VERSION "HNNBNNNYNNNNNNNNNNNNNNNNNNNNNNNNNNNNNNNNNN/4/%%%/4/'%**4NNN///"

NS_ :

BS_:

BU_: AFS AFS_LMod_L AFS_LMod_R BCM1 BVS FCM GLW_LMod_L GLW_LMod_R LCM_L LCM_R LED_DK3_LM_L LED_DK3_LM_R LED_LM_L LED_LM_R LLP_L LLP_R LWR_MXB_L LWR_MXB_R MXB MXB_LM_L MXB_LM_R ZFAS

BO_ 919 GLW_Feh_LM_R: 5 GLW_LMod_R
 SG_ FGR_Akt_KS_Plus : 0|1@1+ (1,0) [0|1] ""  AFS,BCM1,FCM
 SG_ FGR_RAkt_KS_Plus : 1|1@1+ (1,0) [0|1] ""  AFS,BCM1,FCM
 SG_ FGR_Akt_KS_Gnd : 2|1@1+ (1,0) [0|1] ""  AFS,BCM1,FCM
 SG_ FGR_RAkt_KS_Gnd : 3|1@1+ (1,0) [0|1] ""  AFS,BCM1,FCM
 SG_ FGR_Akt_OL : 4|1@1+ (1,0) [0|1] ""  AFS,BCM1,FCM
 SG_ FGR_RAkt_OL : 5|1@1+ (1,0) [0|1] ""  AFS,BCM1,FCM
 SG_ FGR_Akt_UeSpg : 6|1@1+ (1,0) [0|1] ""  AFS,BCM1,FCM
 SG_ FGR_RAkt_UeSpg : 7|1@1+ (1,0) [0|1] ""  AFS,BCM1,FCM
 SG_ FGR_Akt_USpg : 8|1@1+ (1,0) [0|1] ""  AFS,BCM1,FCM
 SG_ FGR_RAkt_USpg : 9|1@1+ (1,0) [0|1] ""  AFS,BCM1,FCM
 SG_ FGR_Akt_UeTemp : 10|1@1+ (1,0) [0|1] ""  AFS,BCM1,FCM
 SG_ FGR_RAkt_UeTemp : 11|1@1+ (1,0) [0|1] ""  AFS,BCM1,FCM
 SG_ FGR_Akt_TempPre : 12|1@1+ (1,0) [0|1] ""  AFS,BCM1,FCM
 SG_ FGR_RAkt_TempPre : 13|1@1+ (1,0) [0|1] ""  AFS,BCM1,FCM
 SG_ FGR_HS_KS_Plus : 18|1@1+ (1,0) [0|1] ""  AFS,BCM1,FCM
 SG_ FGR_RHS_KS_Plus : 19|1@1+ (1,0) [0|1] ""  AFS,BCM1,FCM
 SG_ FGR_HS_KS_Gnd : 20|1@1+ (1,0) [0|1] ""  AFS,BCM1,FCM
 SG_ FGR_RHS_KS_Gnd : 21|1@1+ (1,0) [0|1] ""  AFS,BCM1,FCM
 SG_ FGR_HS_unplSign : 22|1@1+ (1,0) [0|1] ""  AFS,BCM1,FCM
 SG_ FGR_RHS_unplSign : 23|1@1+ (1,0) [0|1] ""  AFS,BCM1,FCM
 SG_ FGR_LIN_Def : 24|1@1+ (1,0) [0|1] ""  AFS,BCM1,FCM
 SG_ FGR_LIN_Timeout : 25|1@1+ (1,0) [0|1] ""  AFS,BCM1,FCM
 SG_ FGR_RLIN_Def : 26|1@1+ (1,0) [0|1] ""  AFS,BCM1,FCM
 SG_ FGR_RLIN_Timeout : 27|1@1+ (1,0) [0|1] ""  AFS,BCM1,FCM

BO_ 272 GLW_Soll_Fkt: 8 AFS
 SG_ SOG_SollPos_L : 0|12@1+ (0.05,0) [0|200] "Unit_PerCent"  BVS,GLW_LMod_L,LCM_L,LLP_L,ZFAS
 SG_ SOG_MXB_Aufblenden : 12|1@1+ (1,0) [0|1] ""  BVS,ZFAS
 SG_ SOG_MXB_Aufbl_Schaltart : 13|1@1+ (1,0) [0|1] ""  BVS,ZFAS
 SG_ SOG_Mali_Freigabe_re : 14|1@1+ (1,0) [0|1] ""  BVS,ZFAS
 SG_ SOG_Mali_Freigabe_li : 15|1@1+ (1,0) [0|1] ""  BVS,ZFAS
 SG_ SOG_SollPos_R : 16|12@1+ (0.05,0) [0|200] "Unit_PerCent"  BVS,GLW_LMod_R,LCM_R,LLP_R,ZFAS
 SG_ SOG_FehlPos_L : 28|1@1+ (1,0) [0|1] ""  BVS,GLW_LMod_L,LCM_L,LLP_L,ZFAS
 SG_ SOG_FehlPos_R : 29|1@1+ (1,0) [0|1] ""  BVS,GLW_LMod_R,LCM_R,LLP_R,ZFAS
 SG_ SOG_RefLauf_L : 30|1@1+ (1,0) [0|1] ""  BVS,GLW_LMod_L,LCM_L,LLP_L,ZFAS
 SG_ SOG_RefLauf_R : 31|1@1+ (1,0) [0|1] ""  BVS,GLW_LMod_R,LCM_R,LLP_R,ZFAS
 SG_ SOG_StGlTest_L : 32|1@1+ (1,0) [0|1] ""  BVS,GLW_LMod_L,LCM_L,LLP_L,ZFAS
 SG_ SOG_StGlTest_R : 33|1@1+ (1,0) [0|1] ""  BVS,GLW_LMod_R,LCM_R,LLP_R,ZFAS
 SG_ SOG_Verkehrsrichtung : 34|1@1+ (1,0) [0|1] ""  BVS,GLW_LMod_L,GLW_LMod_R,LCM_L,LCM_R,LLP_L,LLP_R,ZFAS
 SG_ SOG_XenonLeistung_L : 35|8@1+ (0.125,25) [25|56.5] "Unit_Watt"  BVS,GLW_LMod_L,ZFAS
 SG_ SOG_XenonLeistung_L_Schaltart : 43|1@1+ (1,0) [0|1] ""  BVS,GLW_LMod_L,ZFAS
 SG_ SOG_XenonLeistung_R : 44|8@1+ (0.125,25) [25|56.5] "Unit_Watt"  BVS,GLW_LMod_R,ZFAS
 SG_ SOG_XenonLeistung_R_Schaltart : 52|1@1+ (1,0) [0|1] ""  BVS,GLW_LMod_R,ZFAS

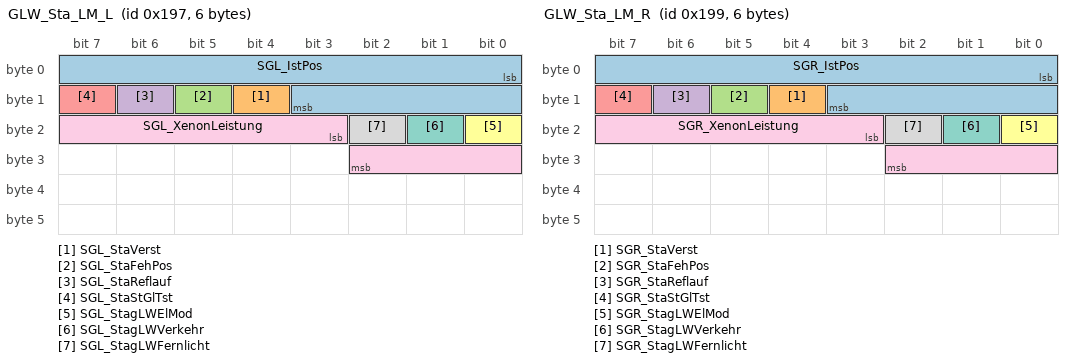
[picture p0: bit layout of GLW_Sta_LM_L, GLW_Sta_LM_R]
BO_ 407 GLW_Sta_LM_L: 6 GLW_LMod_L
 SG_ SGL_IstPos : 0|12@1+ (0.05,0) [0|200] "Unit_PerCent"  AFS,BCM1,FCM
 SG_ SGL_StaVerst : 12|1@1+ (1,0) [0|1] ""  AFS,BCM1,FCM
 SG_ SGL_StaFehPos : 13|1@1+ (1,0) [0|1] ""  AFS,BCM1,FCM
 SG_ SGL_StaReflauf : 14|1@1+ (1,0) [0|1] ""  AFS,BCM1,FCM
 SG_ SGL_StaStGlTst : 15|1@1+ (1,0) [0|1] ""  AFS,BCM1,FCM
 SG_ SGL_StagLWElMod : 16|1@1+ (1,0) [0|1] ""  AFS,BCM1,FCM
 SG_ SGL_StagLWVerkehr : 17|1@1+ (1,0) [0|1] ""  AFS,BCM1,FCM
 SG_ SGL_StagLWFernlicht : 18|1@1+ (1,0) [0|1] ""  AFS,BCM1,FCM
 SG_ SGL_XenonLeistung : 19|8@1+ (0.125,25) [25|56.5] "Unit_Watt"  AFS,BCM1,FCM

BO_ 409 GLW_Sta_LM_R: 6 GLW_LMod_R
 SG_ SGR_IstPos : 0|12@1+ (0.05,0) [0|200] "Unit_PerCent"  AFS,BCM1,FCM
 SG_ SGR_StaVerst : 12|1@1+ (1,0) [0|1] ""  AFS,BCM1,FCM
 SG_ SGR_StaFehPos : 13|1@1+ (1,0) [0|1] ""  AFS,BCM1,FCM
 SG_ SGR_StaReflauf : 14|1@1+ (1,0) [0|1] ""  AFS,BCM1,FCM
 SG_ SGR_StaStGlTst : 15|1@1+ (1,0) [0|1] ""  AFS,BCM1,FCM
 SG_ SGR_StagLWElMod : 16|1@1+ (1,0) [0|1] ""  AFS,BCM1,FCM
 SG_ SGR_StagLWVerkehr : 17|1@1+ (1,0) [0|1] ""  AFS,BCM1,FCM
 SG_ SGR_StagLWFernlicht : 18|1@1+ (1,0) [0|1] ""  AFS,BCM1,FCM
 SG_ SGR_XenonLeistung : 19|8@1+ (0.125,25) [25|56.5] "Unit_Watt"  AFS,BCM1,FCM

BO_ 1792 ISO_Funktionaler_Req_All: 8 AFS
 SG_ ISO_ALL_01_Req_Data : 0|64@1+ (1,0) [0|1.84467440737096E+019] ""  GLW_LMod_L,GLW_LMod_R,LCM_L,LCM_R,LED_DK3_LM_L,LED_DK3_LM_R,LED_LM_L,LED_LM_R,LLP_L,LLP_R

BO_ 2549874818 ISOx_LCM_L_Req: 8 AFS
 SG_ ISO_LCM_L_Req_Data : 0|64@1+ (1,0) [0|1.84467440737096E+019] ""  LCM_L

BO_ 2550005890 ISOx_LCM_L_Resp: 8 LCM_L
 SG_ ISO_LCM_L_Resp_Data : 0|64@1+ (1,0) [0|1.84467440737096E+019] ""  AFS,BCM1,FCM,MXB

BO_ 2549874819 ISOx_LCM_R_Req: 8 AFS
 SG_ ISO_LCM_R_Req_Data : 0|64@1+ (1,0) [0|1.84467440737096E+019] ""  LCM_R

BO_ 2550005891 ISOx_LCM_R_Resp: 8 LCM_R
 SG_ ISO_LCM_R_Resp_Data : 0|64@1+ (1,0) [0|1.84467440737096E+019] ""  AFS,BCM1,FCM,MXB

BO_ 2549874838 ISOx_LED_LM_L_Req: 8 AFS
 SG_ ISO_LED_LM_L_Req_Data : 0|64@1+ (1,0) [0|1.84467440737096E+019] ""  LED_DK3_LM_L,LED_LM_L,LLP_L

BO_ 2550005910 ISOx_LED_LM_L_Resp: 8 LED_DK3_LM_L
 SG_ ISO_LED_LM_L_Resp_Data : 0|64@1+ (1,0) [0|1.84467440737096E+019] ""  AFS,BCM1,FCM,MXB

BO_ 2549874839 ISOx_LED_LM_R_Req: 8 AFS
 SG_ ISO_LED_LM_R_Req_Data : 0|64@1+ (1,0) [0|1.84467440737096E+019] ""  LED_DK3_LM_R,LED_LM_R,LLP_R

BO_ 2550005911 ISOx_LED_LM_R_Resp: 8 LED_DK3_LM_R
 SG_ ISO_LED_LM_R_Resp_Data : 0|64@1+ (1,0) [0|1.84467440737096E+019] ""  AFS,BCM1,FCM,MXB

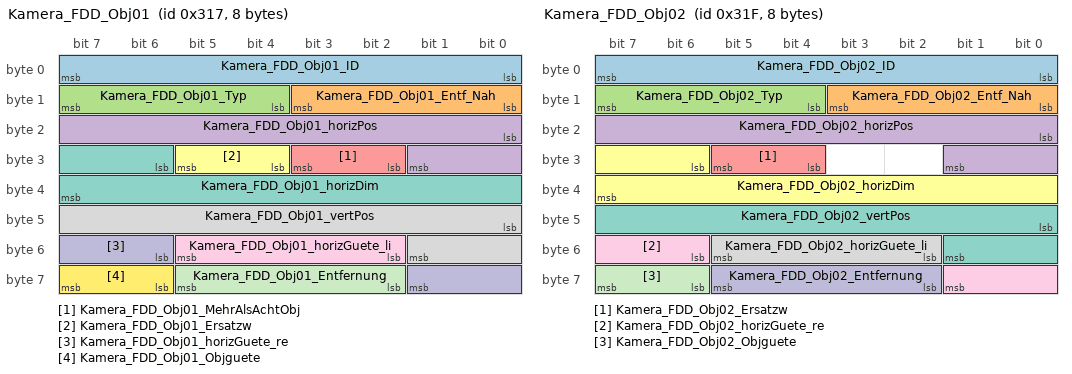
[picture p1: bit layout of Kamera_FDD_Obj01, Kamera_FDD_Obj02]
BO_ 791 Kamera_FDD_Obj01: 8 BVS
 SG_ Kamera_FDD_Obj01_ID : 0|8@1+ (1,0) [0|253] ""  BCM1
 SG_ Kamera_FDD_Obj01_Entf_Nah : 8|4@1+ (1,0) [0|15] ""  BCM1
 SG_ Kamera_FDD_Obj01_Typ : 12|4@1+ (1,0) [0|15] ""  BCM1
 SG_ Kamera_FDD_Obj01_horizPos : 16|10@1+ (0.05,-25.5) [-25.5|25.5] "Unit_DegreOfArc"  BCM1
 SG_ Kamera_FDD_Obj01_MehrAlsAchtObj : 26|2@1+ (1,0) [0|3] ""  BCM1
 SG_ Kamera_FDD_Obj01_Ersatzw : 28|2@1+ (1,0) [0|3] ""  BCM1
 SG_ Kamera_FDD_Obj01_horizDim : 30|10@1+ (0.05,0) [0|49.9] "Unit_DegreOfArc"  BCM1
 SG_ Kamera_FDD_Obj01_vertPos : 40|10@1+ (0.05,-12.75) [-12.75|12.75] "Unit_DegreOfArc"  BCM1
 SG_ Kamera_FDD_Obj01_horizGuete_li : 50|4@1+ (0.25,0) [0|3.75] "Unit_DegreOfArc"  BCM1
 SG_ Kamera_FDD_Obj01_horizGuete_re : 54|4@1+ (0.25,0) [0|3.75] "Unit_DegreOfArc"  BCM1
 SG_ Kamera_FDD_Obj01_Entfernung : 58|4@1+ (1,0) [0|15] ""  BCM1
 SG_ Kamera_FDD_Obj01_Objguete : 62|2@1+ (1,0) [0|3] ""  BCM1

BO_ 799 Kamera_FDD_Obj02: 8 BVS
 SG_ Kamera_FDD_Obj02_ID : 0|8@1+ (1,0) [0|253] ""  BCM1
 SG_ Kamera_FDD_Obj02_Entf_Nah : 8|4@1+ (1,0) [0|15] ""  BCM1
 SG_ Kamera_FDD_Obj02_Typ : 12|4@1+ (1,0) [0|15] ""  BCM1
 SG_ Kamera_FDD_Obj02_horizPos : 16|10@1+ (0.05,-25.5) [-25.5|25.5] "Unit_DegreOfArc"  BCM1
 SG_ Kamera_FDD_Obj02_Ersatzw : 28|2@1+ (1,0) [0|3] ""  BCM1
 SG_ Kamera_FDD_Obj02_horizDim : 30|10@1+ (0.05,0) [0|49.9] "Unit_DegreOfArc"  BCM1
 SG_ Kamera_FDD_Obj02_vertPos : 40|10@1+ (0.05,-12.75) [-12.75|12.75] "Unit_DegreOfArc"  BCM1
 SG_ Kamera_FDD_Obj02_horizGuete_li : 50|4@1+ (0.25,0) [0|3.75] "Unit_DegreOfArc"  BCM1
 SG_ Kamera_FDD_Obj02_horizGuete_re : 54|4@1+ (0.25,0) [0|3.75] "Unit_DegreOfArc"  BCM1
 SG_ Kamera_FDD_Obj02_Entfernung : 58|4@1+ (1,0) [0|15] ""  BCM1
 SG_ Kamera_FDD_Obj02_Objguete : 62|2@1+ (1,0) [0|3] ""  BCM1

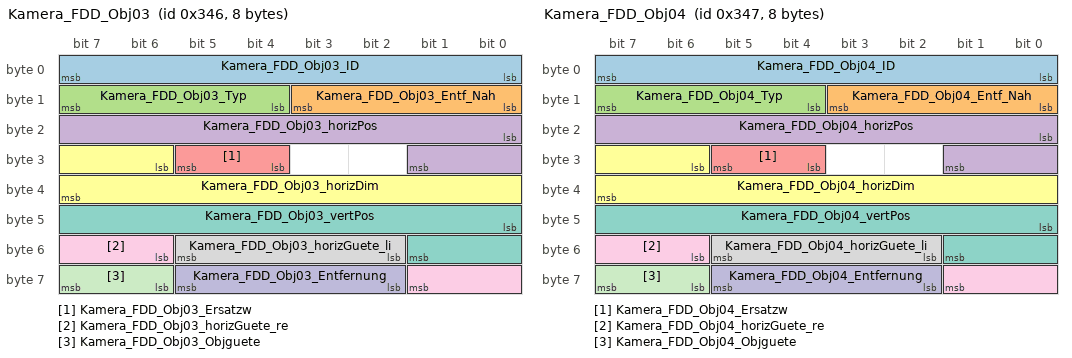
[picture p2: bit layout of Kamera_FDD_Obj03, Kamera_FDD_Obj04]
BO_ 838 Kamera_FDD_Obj03: 8 BVS
 SG_ Kamera_FDD_Obj03_ID : 0|8@1+ (1,0) [0|253] ""  BCM1
 SG_ Kamera_FDD_Obj03_Entf_Nah : 8|4@1+ (1,0) [0|15] ""  BCM1
 SG_ Kamera_FDD_Obj03_Typ : 12|4@1+ (1,0) [0|15] ""  BCM1
 SG_ Kamera_FDD_Obj03_horizPos : 16|10@1+ (0.05,-25.5) [-25.5|25.5] "Unit_DegreOfArc"  BCM1
 SG_ Kamera_FDD_Obj03_Ersatzw : 28|2@1+ (1,0) [0|3] ""  BCM1
 SG_ Kamera_FDD_Obj03_horizDim : 30|10@1+ (0.05,0) [0|49.9] "Unit_DegreOfArc"  BCM1
 SG_ Kamera_FDD_Obj03_vertPos : 40|10@1+ (0.05,-12.75) [-12.75|12.75] "Unit_DegreOfArc"  BCM1
 SG_ Kamera_FDD_Obj03_horizGuete_li : 50|4@1+ (0.25,0) [0|3.75] "Unit_DegreOfArc"  BCM1
 SG_ Kamera_FDD_Obj03_horizGuete_re : 54|4@1+ (0.25,0) [0|3.75] "Unit_DegreOfArc"  BCM1
 SG_ Kamera_FDD_Obj03_Entfernung : 58|4@1+ (1,0) [0|15] ""  BCM1
 SG_ Kamera_FDD_Obj03_Objguete : 62|2@1+ (1,0) [0|3] ""  BCM1

BO_ 839 Kamera_FDD_Obj04: 8 BVS
 SG_ Kamera_FDD_Obj04_ID : 0|8@1+ (1,0) [0|253] ""  BCM1
 SG_ Kamera_FDD_Obj04_Entf_Nah : 8|4@1+ (1,0) [0|15] ""  BCM1
 SG_ Kamera_FDD_Obj04_Typ : 12|4@1+ (1,0) [0|15] ""  BCM1
 SG_ Kamera_FDD_Obj04_horizPos : 16|10@1+ (0.05,-25.5) [-25.5|25.5] "Unit_DegreOfArc"  BCM1
 SG_ Kamera_FDD_Obj04_Ersatzw : 28|2@1+ (1,0) [0|3] ""  BCM1
 SG_ Kamera_FDD_Obj04_horizDim : 30|10@1+ (0.05,0) [0|49.9] "Unit_DegreOfArc"  BCM1
 SG_ Kamera_FDD_Obj04_vertPos : 40|10@1+ (0.05,-12.75) [-12.75|12.75] "Unit_DegreOfArc"  BCM1
 SG_ Kamera_FDD_Obj04_horizGuete_li : 50|4@1+ (0.25,0) [0|3.75] "Unit_DegreOfArc"  BCM1
 SG_ Kamera_FDD_Obj04_horizGuete_re : 54|4@1+ (0.25,0) [0|3.75] "Unit_DegreOfArc"  BCM1
 SG_ Kamera_FDD_Obj04_Entfernung : 58|4@1+ (1,0) [0|15] ""  BCM1
 SG_ Kamera_FDD_Obj04_Objguete : 62|2@1+ (1,0) [0|3] ""  BCM1

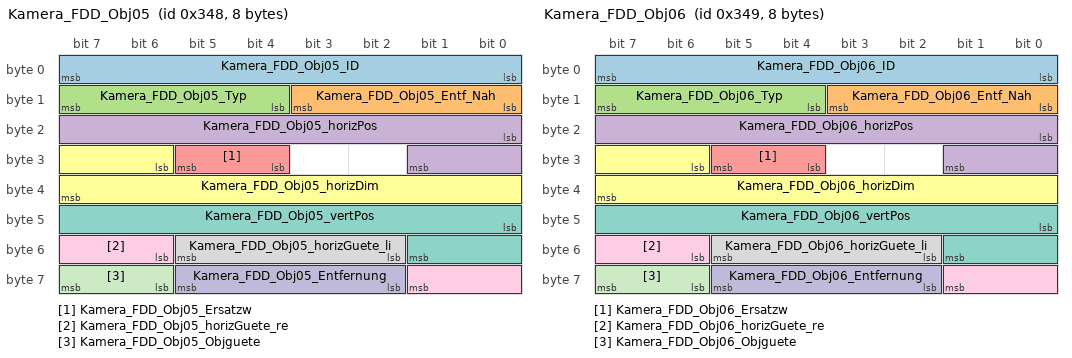
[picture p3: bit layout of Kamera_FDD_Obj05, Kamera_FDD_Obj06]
BO_ 840 Kamera_FDD_Obj05: 8 BVS
 SG_ Kamera_FDD_Obj05_ID : 0|8@1+ (1,0) [0|253] ""  BCM1
 SG_ Kamera_FDD_Obj05_Entf_Nah : 8|4@1+ (1,0) [0|15] ""  BCM1
 SG_ Kamera_FDD_Obj05_Typ : 12|4@1+ (1,0) [0|15] ""  BCM1
 SG_ Kamera_FDD_Obj05_horizPos : 16|10@1+ (0.05,-25.5) [-25.5|25.5] "Unit_DegreOfArc"  BCM1
 SG_ Kamera_FDD_Obj05_Ersatzw : 28|2@1+ (1,0) [0|3] ""  BCM1
 SG_ Kamera_FDD_Obj05_horizDim : 30|10@1+ (0.05,0) [0|49.9] "Unit_DegreOfArc"  BCM1
 SG_ Kamera_FDD_Obj05_vertPos : 40|10@1+ (0.05,-12.75) [-12.75|12.75] "Unit_DegreOfArc"  BCM1
 SG_ Kamera_FDD_Obj05_horizGuete_li : 50|4@1+ (0.25,0) [0|3.75] "Unit_DegreOfArc"  BCM1
 SG_ Kamera_FDD_Obj05_horizGuete_re : 54|4@1+ (0.25,0) [0|3.75] "Unit_DegreOfArc"  BCM1
 SG_ Kamera_FDD_Obj05_Entfernung : 58|4@1+ (1,0) [0|15] ""  BCM1
 SG_ Kamera_FDD_Obj05_Objguete : 62|2@1+ (1,0) [0|3] ""  BCM1

BO_ 841 Kamera_FDD_Obj06: 8 BVS
 SG_ Kamera_FDD_Obj06_ID : 0|8@1+ (1,0) [0|253] ""  BCM1
 SG_ Kamera_FDD_Obj06_Entf_Nah : 8|4@1+ (1,0) [0|15] ""  BCM1
 SG_ Kamera_FDD_Obj06_Typ : 12|4@1+ (1,0) [0|15] ""  BCM1
 SG_ Kamera_FDD_Obj06_horizPos : 16|10@1+ (0.05,-25.5) [-25.5|25.5] "Unit_DegreOfArc"  BCM1
 SG_ Kamera_FDD_Obj06_Ersatzw : 28|2@1+ (1,0) [0|3] ""  BCM1
 SG_ Kamera_FDD_Obj06_horizDim : 30|10@1+ (0.05,0) [0|49.9] "Unit_DegreOfArc"  BCM1
 SG_ Kamera_FDD_Obj06_vertPos : 40|10@1+ (0.05,-12.75) [-12.75|12.75] "Unit_DegreOfArc"  BCM1
 SG_ Kamera_FDD_Obj06_horizGuete_li : 50|4@1+ (0.25,0) [0|3.75] "Unit_DegreOfArc"  BCM1
 SG_ Kamera_FDD_Obj06_horizGuete_re : 54|4@1+ (0.25,0) [0|3.75] "Unit_DegreOfArc"  BCM1
 SG_ Kamera_FDD_Obj06_Entfernung : 58|4@1+ (1,0) [0|15] ""  BCM1
 SG_ Kamera_FDD_Obj06_Objguete : 62|2@1+ (1,0) [0|3] ""  BCM1

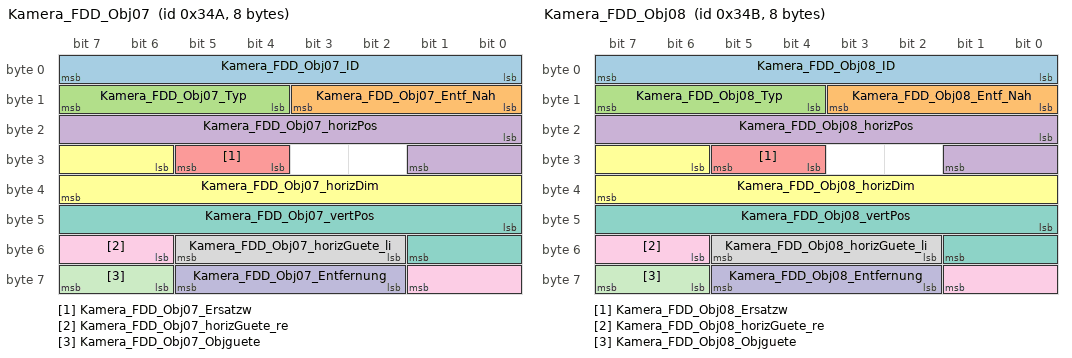
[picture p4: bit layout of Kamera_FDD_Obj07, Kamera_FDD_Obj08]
BO_ 842 Kamera_FDD_Obj07: 8 BVS
 SG_ Kamera_FDD_Obj07_ID : 0|8@1+ (1,0) [0|253] ""  BCM1
 SG_ Kamera_FDD_Obj07_Entf_Nah : 8|4@1+ (1,0) [0|15] ""  BCM1
 SG_ Kamera_FDD_Obj07_Typ : 12|4@1+ (1,0) [0|15] ""  BCM1
 SG_ Kamera_FDD_Obj07_horizPos : 16|10@1+ (0.05,-25.5) [-25.5|25.5] "Unit_DegreOfArc"  BCM1
 SG_ Kamera_FDD_Obj07_Ersatzw : 28|2@1+ (1,0) [0|3] ""  BCM1
 SG_ Kamera_FDD_Obj07_horizDim : 30|10@1+ (0.05,0) [0|49.9] "Unit_DegreOfArc"  BCM1
 SG_ Kamera_FDD_Obj07_vertPos : 40|10@1+ (0.05,-12.75) [-12.75|12.75] "Unit_DegreOfArc"  BCM1
 SG_ Kamera_FDD_Obj07_horizGuete_li : 50|4@1+ (0.25,0) [0|3.75] "Unit_DegreOfArc"  BCM1
 SG_ Kamera_FDD_Obj07_horizGuete_re : 54|4@1+ (0.25,0) [0|3.75] "Unit_DegreOfArc"  BCM1
 SG_ Kamera_FDD_Obj07_Entfernung : 58|4@1+ (1,0) [0|15] ""  BCM1
 SG_ Kamera_FDD_Obj07_Objguete : 62|2@1+ (1,0) [0|3] ""  BCM1

BO_ 843 Kamera_FDD_Obj08: 8 BVS
 SG_ Kamera_FDD_Obj08_ID : 0|8@1+ (1,0) [0|253] ""  BCM1
 SG_ Kamera_FDD_Obj08_Entf_Nah : 8|4@1+ (1,0) [0|15] ""  BCM1
 SG_ Kamera_FDD_Obj08_Typ : 12|4@1+ (1,0) [0|15] ""  BCM1
 SG_ Kamera_FDD_Obj08_horizPos : 16|10@1+ (0.05,-25.5) [-25.5|25.5] "Unit_DegreOfArc"  BCM1
 SG_ Kamera_FDD_Obj08_Ersatzw : 28|2@1+ (1,0) [0|3] ""  BCM1
 SG_ Kamera_FDD_Obj08_horizDim : 30|10@1+ (0.05,0) [0|49.9] "Unit_DegreOfArc"  BCM1
 SG_ Kamera_FDD_Obj08_vertPos : 40|10@1+ (0.05,-12.75) [-12.75|12.75] "Unit_DegreOfArc"  BCM1
 SG_ Kamera_FDD_Obj08_horizGuete_li : 50|4@1+ (0.25,0) [0|3.75] "Unit_DegreOfArc"  BCM1
 SG_ Kamera_FDD_Obj08_horizGuete_re : 54|4@1+ (0.25,0) [0|3.75] "Unit_DegreOfArc"  BCM1
 SG_ Kamera_FDD_Obj08_Entfernung : 58|4@1+ (1,0) [0|15] ""  BCM1
 SG_ Kamera_FDD_Obj08_Objguete : 62|2@1+ (1,0) [0|3] ""  BCM1

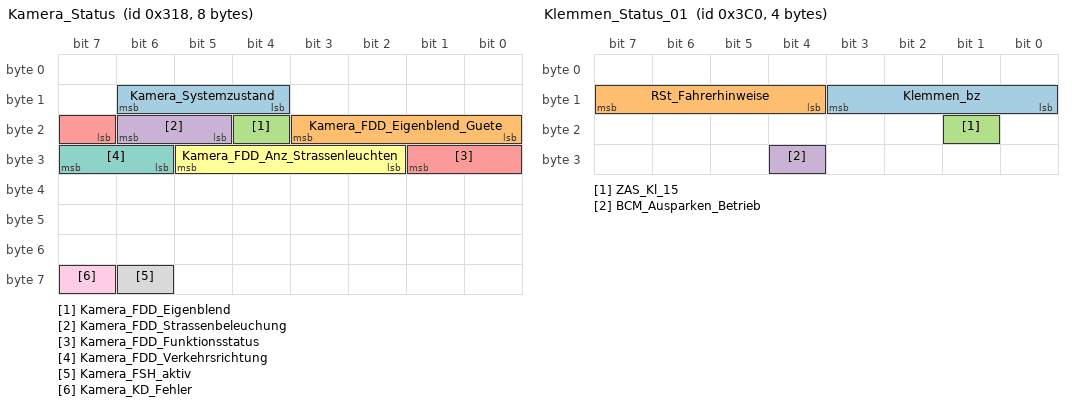
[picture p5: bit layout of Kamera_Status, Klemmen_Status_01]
BO_ 792 Kamera_Status: 8 BVS
 SG_ Kamera_Systemzustand : 12|3@1+ (1,0) [0|7] ""  BCM1
 SG_ Kamera_FDD_Eigenblend_Guete : 16|4@1+ (10,0) [0|100] "Unit_PerCent"  BCM1
 SG_ Kamera_FDD_Eigenblend : 20|1@1+ (1,0) [0|1] ""  BCM1
 SG_ Kamera_FDD_Strassenbeleuchung : 21|2@1+ (1,0) [0|3] ""  BCM1
 SG_ Kamera_FDD_Funktionsstatus : 23|3@1+ (1,0) [0|7] ""  BCM1
 SG_ Kamera_FDD_Anz_Strassenleuchten : 26|4@1+ (1,0) [0|14] ""  BCM1
 SG_ Kamera_FDD_Verkehrsrichtung : 30|2@1+ (1,0) [0|3] ""  BCM1
 SG_ Kamera_FSH_aktiv : 62|1@1+ (1,0) [0|1] ""  BCM1
 SG_ Kamera_KD_Fehler : 63|1@1+ (1,0) [0|1] "" Vector__XXX

BO_ 960 Klemmen_Status_01: 4 MXB
 SG_ Klemmen_bz : 8|4@1- (1,0) [0|0] "" Vector__XXX
 SG_ RSt_Fahrerhinweise : 12|4@1+ (1,0) [0|15] "" Vector__XXX
 SG_ ZAS_Kl_15 : 17|1@1+ (1,0) [0|1] ""  LCM_L,LCM_R,LED_DK3_LM_L,LED_DK3_LM_R,LED_LM_L,LED_LM_R,LLP_L,LLP_R
 SG_ BCM_Ausparken_Betrieb : 28|1@1+ (1,0) [0|1] "" Vector__XXX

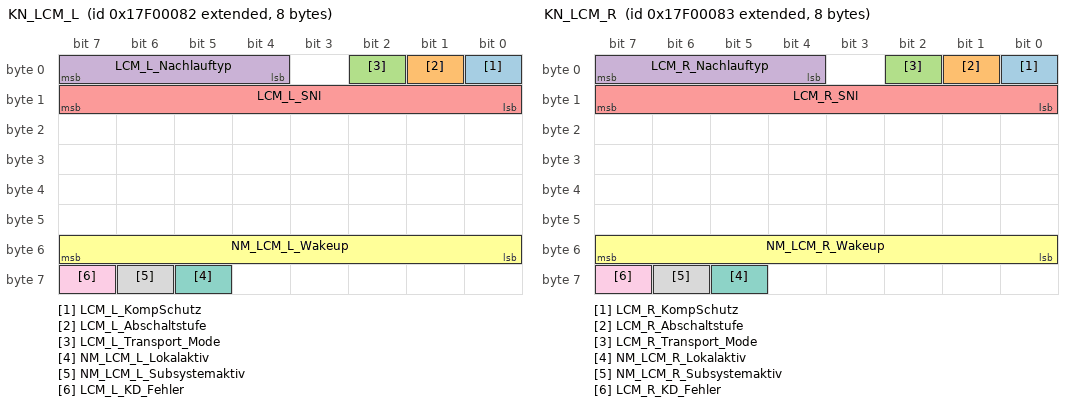
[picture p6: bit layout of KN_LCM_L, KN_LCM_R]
BO_ 2549088386 KN_LCM_L: 8 LCM_L
 SG_ LCM_L_KompSchutz : 0|1@1+ (1,0) [0|1] ""  AFS,BCM1,FCM,MXB
 SG_ LCM_L_Abschaltstufe : 1|1@1+ (1,0) [0|1] ""  AFS,BCM1,FCM,MXB
 SG_ LCM_L_Transport_Mode : 2|1@1+ (1,0) [0|1] ""  AFS,BCM1,FCM,MXB
 SG_ LCM_L_Nachlauftyp : 4|4@1+ (1,0) [0|15] ""  AFS,BCM1,FCM,MXB
 SG_ LCM_L_SNI : 8|8@1+ (1,0) [0|255] ""  AFS,BCM1,FCM,MXB
 SG_ NM_LCM_L_Wakeup : 48|8@1+ (1,0) [0|255] ""  AFS,BCM1,FCM,MXB
 SG_ NM_LCM_L_Lokalaktiv : 61|1@1+ (1,0) [0|1] ""  AFS,BCM1,FCM,MXB
 SG_ NM_LCM_L_Subsystemaktiv : 62|1@1+ (1,0) [0|1] ""  AFS,BCM1,FCM,MXB
 SG_ LCM_L_KD_Fehler : 63|1@1+ (1,0) [0|1] ""  AFS,BCM1,FCM,MXB

BO_ 2549088387 KN_LCM_R: 8 LCM_R
 SG_ LCM_R_KompSchutz : 0|1@1+ (1,0) [0|1] ""  AFS,BCM1,FCM,MXB
 SG_ LCM_R_Abschaltstufe : 1|1@1+ (1,0) [0|1] ""  AFS,BCM1,FCM,MXB
 SG_ LCM_R_Transport_Mode : 2|1@1+ (1,0) [0|1] ""  AFS,BCM1,FCM,MXB
 SG_ LCM_R_Nachlauftyp : 4|4@1+ (1,0) [0|15] ""  AFS,BCM1,FCM,MXB
 SG_ LCM_R_SNI : 8|8@1+ (1,0) [0|255] ""  AFS,BCM1,FCM,MXB
 SG_ NM_LCM_R_Wakeup : 48|8@1+ (1,0) [0|255] ""  AFS,BCM1,FCM,MXB
 SG_ NM_LCM_R_Lokalaktiv : 61|1@1+ (1,0) [0|1] ""  AFS,BCM1,FCM,MXB
 SG_ NM_LCM_R_Subsystemaktiv : 62|1@1+ (1,0) [0|1] ""  AFS,BCM1,FCM,MXB
 SG_ LCM_R_KD_Fehler : 63|1@1+ (1,0) [0|1] ""  AFS,BCM1,FCM,MXB

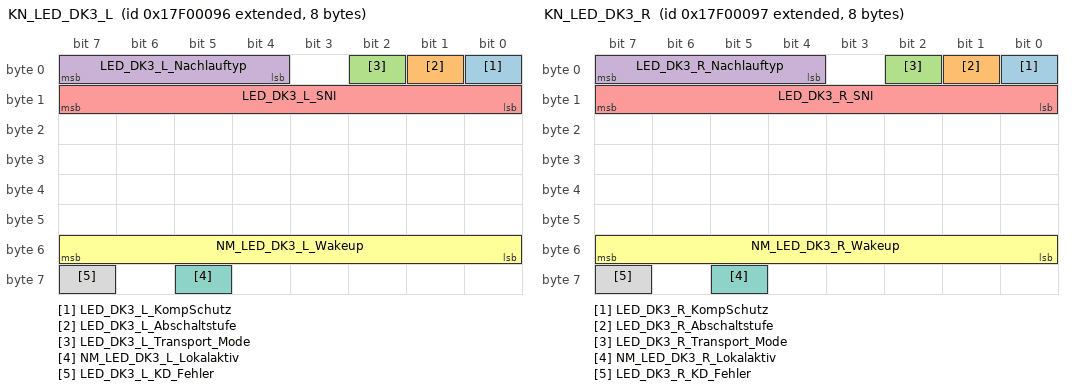
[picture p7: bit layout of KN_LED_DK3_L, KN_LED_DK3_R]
BO_ 2549088406 KN_LED_DK3_L: 8 LED_DK3_LM_L
 SG_ LED_DK3_L_KompSchutz : 0|1@1+ (1,0) [0|1] ""  AFS,BCM1,FCM,MXB
 SG_ LED_DK3_L_Abschaltstufe : 1|1@1+ (1,0) [0|1] ""  AFS,BCM1,FCM,MXB
 SG_ LED_DK3_L_Transport_Mode : 2|1@1+ (1,0) [0|1] ""  AFS,BCM1,FCM,MXB
 SG_ LED_DK3_L_Nachlauftyp : 4|4@1+ (1,0) [0|15] ""  AFS,BCM1,FCM,MXB
 SG_ LED_DK3_L_SNI : 8|8@1+ (1,0) [0|255] ""  AFS,BCM1,FCM,MXB
 SG_ NM_LED_DK3_L_Wakeup : 48|8@1+ (1,0) [0|255] ""  AFS,BCM1,FCM,MXB
 SG_ NM_LED_DK3_L_Lokalaktiv : 61|1@1+ (1,0) [0|1] ""  AFS,BCM1,FCM,MXB
 SG_ LED_DK3_L_KD_Fehler : 63|1@1+ (1,0) [0|1] ""  AFS,BCM1,FCM,MXB

BO_ 2549088407 KN_LED_DK3_R: 8 LED_DK3_LM_R
 SG_ LED_DK3_R_KompSchutz : 0|1@1+ (1,0) [0|1] ""  AFS,BCM1,FCM,MXB
 SG_ LED_DK3_R_Abschaltstufe : 1|1@1+ (1,0) [0|1] ""  AFS,BCM1,FCM,MXB
 SG_ LED_DK3_R_Transport_Mode : 2|1@1+ (1,0) [0|1] ""  AFS,BCM1,FCM,MXB
 SG_ LED_DK3_R_Nachlauftyp : 4|4@1+ (1,0) [0|15] ""  AFS,BCM1,FCM,MXB
 SG_ LED_DK3_R_SNI : 8|8@1+ (1,0) [0|255] ""  AFS,BCM1,FCM,MXB
 SG_ NM_LED_DK3_R_Wakeup : 48|8@1+ (1,0) [0|255] ""  AFS,BCM1,FCM,MXB
 SG_ NM_LED_DK3_R_Lokalaktiv : 61|1@1+ (1,0) [0|1] ""  AFS,BCM1,FCM,MXB
 SG_ LED_DK3_R_KD_Fehler : 63|1@1+ (1,0) [0|1] ""  AFS,BCM1,FCM,MXB

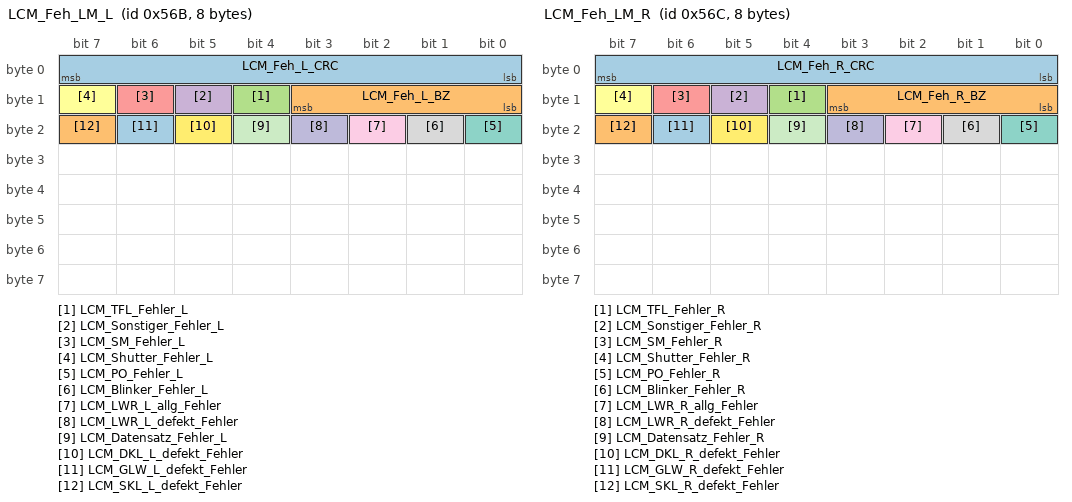
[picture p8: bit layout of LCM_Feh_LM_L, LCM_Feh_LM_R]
BO_ 1387 LCM_Feh_LM_L: 8 LCM_L
 SG_ LCM_Feh_L_CRC : 0|8@1+ (1,0) [0|255] ""  BCM1,MXB
 SG_ LCM_Feh_L_BZ : 8|4@1+ (1,0) [0|15] ""  BCM1,MXB
 SG_ LCM_TFL_Fehler_L : 12|1@1+ (1,0) [0|1] ""  AFS,BCM1,FCM,MXB
 SG_ LCM_Sonstiger_Fehler_L : 13|1@1+ (1,0) [0|1] ""  AFS,BCM1,FCM,MXB
 SG_ LCM_SM_Fehler_L : 14|1@1+ (1,0) [0|1] ""  AFS,BCM1,FCM,MXB
 SG_ LCM_Shutter_Fehler_L : 15|1@1+ (1,0) [0|1] ""  AFS,BCM1,FCM,MXB
 SG_ LCM_PO_Fehler_L : 16|1@1+ (1,0) [0|1] ""  AFS,BCM1,FCM,MXB
 SG_ LCM_Blinker_Fehler_L : 17|1@1+ (1,0) [0|1] ""  AFS,BCM1,FCM,MXB
 SG_ LCM_LWR_L_allg_Fehler : 18|1@1+ (1,0) [0|1] ""  AFS,BCM1,FCM,MXB
 SG_ LCM_LWR_L_defekt_Fehler : 19|1@1+ (1,0) [0|1] ""  AFS,BCM1,FCM,MXB
 SG_ LCM_Datensatz_Fehler_L : 20|1@1+ (1,0) [0|1] ""  AFS,BCM1,FCM,MXB
 SG_ LCM_DKL_L_defekt_Fehler : 21|1@1+ (1,0) [0|1] ""  AFS,BCM1,FCM,MXB
 SG_ LCM_GLW_L_defekt_Fehler : 22|1@1+ (1,0) [0|1] ""  AFS,BCM1,FCM,MXB
 SG_ LCM_SKL_L_defekt_Fehler : 23|1@1+ (1,0) [0|1] ""  AFS,BCM1,FCM,MXB

BO_ 1388 LCM_Feh_LM_R: 8 LCM_R
 SG_ LCM_Feh_R_CRC : 0|8@1+ (1,0) [0|255] ""  BCM1,MXB
 SG_ LCM_Feh_R_BZ : 8|4@1+ (1,0) [0|15] ""  BCM1,MXB
 SG_ LCM_TFL_Fehler_R : 12|1@1+ (1,0) [0|1] ""  AFS,BCM1,FCM,MXB
 SG_ LCM_Sonstiger_Fehler_R : 13|1@1+ (1,0) [0|1] ""  AFS,BCM1,FCM,MXB
 SG_ LCM_SM_Fehler_R : 14|1@1+ (1,0) [0|1] ""  AFS,BCM1,FCM,MXB
 SG_ LCM_Shutter_Fehler_R : 15|1@1+ (1,0) [0|1] ""  AFS,BCM1,FCM,MXB
 SG_ LCM_PO_Fehler_R : 16|1@1+ (1,0) [0|1] ""  AFS,BCM1,FCM,MXB
 SG_ LCM_Blinker_Fehler_R : 17|1@1+ (1,0) [0|1] ""  AFS,BCM1,FCM,MXB
 SG_ LCM_LWR_R_allg_Fehler : 18|1@1+ (1,0) [0|1] ""  AFS,BCM1,FCM,MXB
 SG_ LCM_LWR_R_defekt_Fehler : 19|1@1+ (1,0) [0|1] ""  AFS,BCM1,FCM,MXB
 SG_ LCM_Datensatz_Fehler_R : 20|1@1+ (1,0) [0|1] ""  AFS,BCM1,FCM,MXB
 SG_ LCM_DKL_R_defekt_Fehler : 21|1@1+ (1,0) [0|1] ""  AFS,BCM1,FCM,MXB
 SG_ LCM_GLW_R_defekt_Fehler : 22|1@1+ (1,0) [0|1] ""  AFS,BCM1,FCM,MXB
 SG_ LCM_SKL_R_defekt_Fehler : 23|1@1+ (1,0) [0|1] ""  AFS,BCM1,FCM,MXB

BO_ 403 LCM_Soll_Fkt: 8 AFS
 SG_ LCM_Soll_CRC : 0|8@1+ (1,0) [0|255] ""  LCM_L,LCM_R,LLP_L,LLP_R
 SG_ LCM_Soll_BZ : 8|4@1+ (1,0) [0|15] ""  LCM_L,LCM_R,LLP_L,LLP_R
 SG_ LCM_TFL_L_Anf : 12|1@1+ (1,0) [0|1] ""  LCM_L,LLP_L
 SG_ LCM_TFL_R_Anf : 13|1@1+ (1,0) [0|1] ""  LCM_R,LLP_R
 SG_ LCM_Abschaltung_Vbat_L_Anf : 14|1@1+ (1,0) [0|1] ""  LCM_L,LLP_L
 SG_ LCM_Abschaltung_Vbat_R_Anf : 15|1@1+ (1,0) [0|1] ""  LCM_R,LLP_R
 SG_ LCM_Blinker_L_Anf : 16|1@1+ (1,0) [0|1] ""  LCM_L,LLP_L
 SG_ LCM_Blinker_R_Anf : 17|1@1+ (1,0) [0|1] ""  LCM_R,LLP_R
 SG_ LCM_Blinkerzyklus_L : 18|1@1+ (1,0) [0|1] ""  LCM_L,LLP_L
 SG_ LCM_Blinkerzyklus_R : 19|1@1+ (1,0) [0|1] ""  LCM_R,LLP_R
 SG_ LCM_Sh_L_Anf : 20|1@1+ (1,0) [0|1] ""  LCM_L,LLP_L
 SG_ LCM_Sh_R_Anf : 21|1@1+ (1,0) [0|1] ""  LCM_R,LLP_R
 SG_ LCM_SM_L_Anf : 22|1@1+ (1,0) [0|1] ""  LCM_L,LLP_L
 SG_ LCM_SM_R_Anf : 23|1@1+ (1,0) [0|1] ""  LCM_R,LLP_R
 SG_ LCM_univ_1_L_Anf : 24|1@1+ (1,0) [0|1] ""  LCM_L,LLP_L
 SG_ LCM_univ_1_R_Anf : 25|1@1+ (1,0) [0|1] ""  LCM_R,LLP_R
 SG_ LCM_PO_L_Anf : 28|1@1+ (1,0) [0|1] ""  LCM_L,LLP_L
 SG_ LCM_PO_R_Anf : 29|1@1+ (1,0) [0|1] ""  LCM_R,LLP_R
 SG_ LCM_PL_L_Anf : 30|1@1+ (1,0) [0|1] ""  LCM_L,LLP_L
 SG_ LCM_PL_R_Anf : 31|1@1+ (1,0) [0|1] ""  LCM_R,LLP_R
 SG_ LCM_Leistungsreduzierung_Anf : 32|2@1+ (1,0) [0|3] ""  LCM_L,LCM_R,LLP_L,LLP_R
 SG_ LCM_Blinkerwischen_Anf : 35|1@1+ (1,0) [0|1] ""  LCM_L,LCM_R,LLP_L,LLP_R
 SG_ LCM_Animiertes_TFL_Anf : 36|1@1+ (1,0) [0|1] ""  LCM_L,LCM_R,LLP_L,LLP_R
 SG_ LCM_Signaturlicht_Anf : 39|1@1+ (1,0) [0|1] ""  LCM_L,LCM_R,LLP_L,LLP_R
 SG_ LCM_ECE_SAE_Umschaltung_Anf : 41|1@1+ (1,0) [0|1] ""  LCM_L,LCM_R,LLP_L,LLP_R
 SG_ BM_Autobahn : 42|1@1+ (1,0) [0|1] ""  LCM_L,LCM_R,LLP_L,LLP_R
 SG_ BM_ZV_auf : 43|1@1+ (1,0) [0|1] ""  LCM_L,LCM_R,LLP_L,LLP_R
 SG_ BM_ZV_zu : 44|1@1+ (1,0) [0|1] ""  LCM_L,LCM_R,LLP_L,LLP_R
 SG_ BCM1_CH_aktiv : 45|1@1+ (1,0) [0|1] ""  BVS,LCM_L,LCM_R,LED_DK3_LM_L,LED_DK3_LM_R,LED_LM_L,LED_LM_R,LLP_L,LLP_R,ZFAS
 SG_ BCM1_LH_aktiv : 46|1@1+ (1,0) [0|1] ""  BVS,LCM_L,LCM_R,LED_DK3_LM_L,LED_DK3_LM_R,LED_LM_L,LED_LM_R,LLP_L,LLP_R,ZFAS

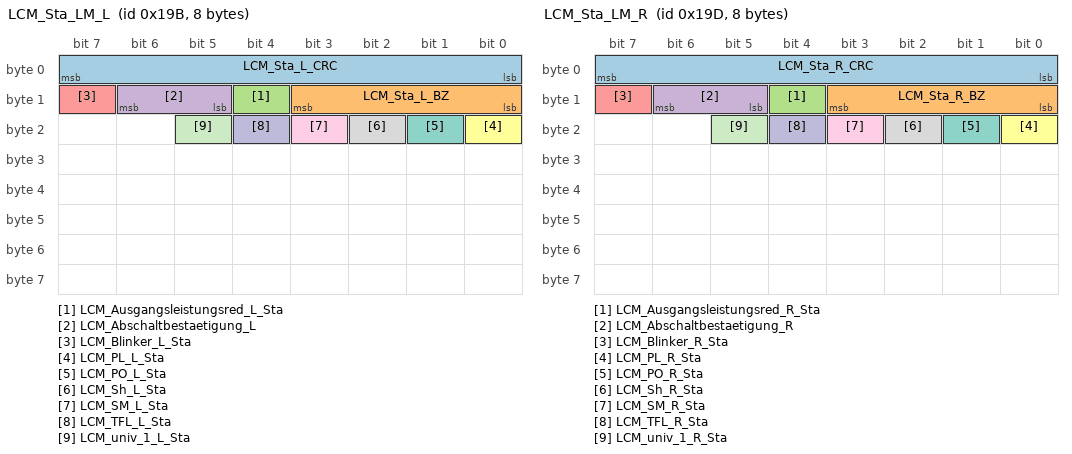
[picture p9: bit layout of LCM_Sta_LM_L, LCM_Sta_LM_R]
BO_ 411 LCM_Sta_LM_L: 8 LCM_L
 SG_ LCM_Sta_L_CRC : 0|8@1+ (1,0) [0|255] ""  BCM1,MXB
 SG_ LCM_Sta_L_BZ : 8|4@1+ (1,0) [0|15] ""  BCM1,MXB
 SG_ LCM_Ausgangsleistungsred_L_Sta : 12|1@1+ (1,0) [0|1] ""  BCM1,MXB
 SG_ LCM_Abschaltbestaetigung_L : 13|2@1+ (1,0) [0|3] ""  AFS,BCM1,FCM,MXB
 SG_ LCM_Blinker_L_Sta : 15|1@1+ (1,0) [0|1] ""  AFS,BCM1,FCM,MXB
 SG_ LCM_PL_L_Sta : 16|1@1+ (1,0) [0|1] ""  BCM1,MXB
 SG_ LCM_PO_L_Sta : 17|1@1+ (1,0) [0|1] ""  BCM1,MXB
 SG_ LCM_Sh_L_Sta : 18|1@1+ (1,0) [0|1] ""  BCM1,MXB
 SG_ LCM_SM_L_Sta : 19|1@1+ (1,0) [0|1] ""  BCM1,MXB
 SG_ LCM_TFL_L_Sta : 20|1@1+ (1,0) [0|1] ""  BCM1,MXB
 SG_ LCM_univ_1_L_Sta : 21|1@1+ (1,0) [0|1] ""  BCM1,MXB

BO_ 413 LCM_Sta_LM_R: 8 LCM_R
 SG_ LCM_Sta_R_CRC : 0|8@1+ (1,0) [0|255] ""  BCM1,MXB
 SG_ LCM_Sta_R_BZ : 8|4@1+ (1,0) [0|15] ""  BCM1,MXB
 SG_ LCM_Ausgangsleistungsred_R_Sta : 12|1@1+ (1,0) [0|1] ""  BCM1,MXB
 SG_ LCM_Abschaltbestaetigung_R : 13|2@1+ (1,0) [0|3] ""  AFS,BCM1,FCM,MXB
 SG_ LCM_Blinker_R_Sta : 15|1@1+ (1,0) [0|1] ""  AFS,BCM1,FCM,MXB
 SG_ LCM_PL_R_Sta : 16|1@1+ (1,0) [0|1] ""  BCM1,MXB
 SG_ LCM_PO_R_Sta : 17|1@1+ (1,0) [0|1] ""  BCM1,MXB
 SG_ LCM_Sh_R_Sta : 18|1@1+ (1,0) [0|1] ""  BCM1,MXB
 SG_ LCM_SM_R_Sta : 19|1@1+ (1,0) [0|1] ""  BCM1,MXB
 SG_ LCM_TFL_R_Sta : 20|1@1+ (1,0) [0|1] ""  BCM1,MXB
 SG_ LCM_univ_1_R_Sta : 21|1@1+ (1,0) [0|1] ""  BCM1,MXB

BO_TX_BU_ 272 : AFS,BCM1,FCM;
BO_TX_BU_ 407 : GLW_LMod_L,LCM_L,LLP_L;
BO_TX_BU_ 409 : GLW_LMod_R,LCM_R,LLP_R;
BO_TX_BU_ 1792 : AFS,BCM1,FCM,MXB;
BO_TX_BU_ 2549874818 : AFS,BCM1,FCM,MXB;
BO_TX_BU_ 2549874819 : AFS,BCM1,FCM,MXB;
BO_TX_BU_ 2549874838 : AFS,BCM1,FCM,MXB;
BO_TX_BU_ 2550005910 : LED_DK3_LM_L,LLP_L;
BO_TX_BU_ 2549874839 : AFS,BCM1,FCM,MXB;
BO_TX_BU_ 2550005911 : LED_DK3_LM_R,LLP_R;
BO_TX_BU_ 791 : BVS,ZFAS;
BO_TX_BU_ 799 : BVS,ZFAS;
BO_TX_BU_ 838 : BVS,ZFAS;
BO_TX_BU_ 839 : BVS,ZFAS;
BO_TX_BU_ 840 : BVS,ZFAS;
BO_TX_BU_ 841 : BVS,ZFAS;
BO_TX_BU_ 842 : BVS,ZFAS;
BO_TX_BU_ 843 : BVS,ZFAS;
BO_TX_BU_ 792 : BVS,ZFAS;
BO_TX_BU_ 960 : AFS,BCM1,FCM,MXB;
BO_TX_BU_ 2549088386 : LCM_L,MXB;
BO_TX_BU_ 2549088406 : LED_DK3_LM_L,LLP_L;
BO_TX_BU_ 2549088407 : LED_DK3_LM_R,LLP_R;
BO_TX_BU_ 1387 : LCM_L,LLP_L;
BO_TX_BU_ 1388 : LCM_R,LLP_R;
BO_TX_BU_ 403 : AFS,BCM1,FCM,MXB;
BO_TX_BU_ 411 : LCM_L,LLP_L;
BO_TX_BU_ 413 : LCM_R,LLP_R;
CM_ SG_ 919 FGR_Akt_KS_Plus "Kurzschluss nach Plus gLW-Aktuator rechter Scheinwerfer";
CM_ SG_ 919 FGR_RAkt_KS_Plus "Das Readyness-Bit dient als Indikator dafür, das der Fehlerbaum sauber durchlaufen wurde. Erst beim Setzen des Readyness-Bits auf '0' wird das dazugehörige Fehlerbit gesetzt";
CM_ SG_ 919 FGR_Akt_KS_Gnd "Kurzschluss nach Masse gLW-Aktuator rechter Scheinwerfer";
CM_ SG_ 919 FGR_RAkt_KS_Gnd "Das Readyness-Bit dient als Indikator dafür, das der Fehlerbaum sauber durchlaufen wurde. Erst beim Setzen des Readyness-Bits auf '0' wird das dazugehörige Fehlerbit gesetzt";
CM_ SG_ 919 FGR_Akt_OL "Offene Leitung (Unterbrechung) gLW-Aktuator rechter Scheinwerfer";
CM_ SG_ 919 FGR_RAkt_OL "Das Readyness-Bit dient als Indikator dafür, das der Fehlerbaum sauber durchlaufen wurde. Erst beim Setzen des Readyness-Bits auf '0' wird das dazugehörige Fehlerbit gesetzt";
CM_ SG_ 919 FGR_Akt_UeSpg "Abschaltung gLW-Aktuator rechter Scheinwerfer aufgrund Überspannung";
CM_ SG_ 919 FGR_RAkt_UeSpg "Das Readyness-Bit dient als Indikator dafür, das der Fehlerbaum sauber durchlaufen wurde. Erst beim Setzen des Readyness-Bits auf '0' wird das dazugehörige Fehlerbit gesetzt";
CM_ SG_ 919 FGR_Akt_USpg "Abschaltung gLW-Aktuator rechter Scheinwerfer aufgrund Unterspannung";
CM_ SG_ 919 FGR_RAkt_USpg "Das Readyness-Bit dient als Indikator dafür, das der Fehlerbaum sauber durchlaufen wurde. Erst beim Setzen des Readyness-Bits auf '0' wird das dazugehörige Fehlerbit gesetzt";
CM_ SG_ 919 FGR_Akt_UeTemp "Abschaltung gLW-Aktuator rechter Scheinwerfer aufgrund Übertemperatur";
CM_ SG_ 919 FGR_RAkt_UeTemp "Das Readyness-Bit dient als Indikator dafür, das der Fehlerbaum sauber durchlaufen wurde. Erst beim Setzen des Readyness-Bits auf '0' wird das dazugehörige Fehlerbit gesetzt";
CM_ SG_ 919 FGR_Akt_TempPre "Ansteuergeschwindigkeit muss reduziert werden wegen erhöhter gLW-Aktuator Temperatur  
(dies ist kein Fehler-BIT!)";
CM_ SG_ 919 FGR_RAkt_TempPre "Das Readyness-Bit dient als Indikator dafür, das der Fehlerbaum sauber durchlaufen wurde. Erst beim Setzen des Readyness-Bits auf '0' wird das dazugehörige Fehlerbit gesetzt";
CM_ SG_ 919 FGR_HS_KS_Plus "Kurzschluss nach Plus gLW Sensor rechter Scheinwerfer

Scheinwerferspezifisch wird nur bei verbauter 360° Rückmeldung gesendet!";
CM_ SG_ 919 FGR_RHS_KS_Plus "Das Readyness-Bit dient als Indikator dafür, das der Fehlerbaum sauber durchlaufen wurde. Erst beim Setzen des Readyness-Bits auf '0' wird das dazugehörige Fehlerbit gesetzt";
CM_ SG_ 919 FGR_HS_KS_Gnd "Kurzschluss nach Masse gLW Sensor rechter Scheinwerfer";
CM_ SG_ 919 FGR_RHS_KS_Gnd "Das Readyness-Bit dient als Indikator dafür, das der Fehlerbaum sauber durchlaufen wurde. Erst beim Setzen des Readyness-Bits auf '0' wird das dazugehörige Fehlerbit gesetzt";
CM_ SG_ 919 FGR_HS_unplSign "Bei einem Fehler kann die 0%-Position des 
GLW-Aktuators nicht bestimmt werden!
Rückmeldung GLW Sensorwerte außerhalb des gültigen Bereichs
(Sensor/ Treiber/ Zuleitung/ Schrittmotoransteuerung prüfen!)";
CM_ SG_ 919 FGR_RHS_unplSign "Das Readyness-Bit dient als Indikator dafür, das der Fehlerbaum sauber durchlaufen wurde. Erst beim Setzen des Readyness-Bits auf '0' wird das dazugehörige Fehlerbit gesetzt";
CM_ SG_ 919 FGR_LIN_Def "Physikalischer Defekt der LIN-Leitung";
CM_ SG_ 919 FGR_LIN_Timeout "Keine Kommunikation zum Teilnehmer";
CM_ SG_ 919 FGR_RLIN_Def "Das Readyness-Bit dient als Indikator dafür, das der Fehlerbaum sauber durchlaufen wurde. Erst beim Setzen des Readyness-Bits auf '0' wird das dazugehörige Fehlerbit gesetzt";
CM_ SG_ 919 FGR_RLIN_Timeout "Das Readyness-Bit dient als Indikator dafür, das der Fehlerbaum sauber durchlaufen wurde. Erst beim Setzen des Readyness-Bits auf '0' wird das dazugehörige Fehlerbit gesetzt";
CM_ SG_ 272 SOG_SollPos_L "Sollposition 'normierter Lichtindex' für den linken Scheinwerfer in %";
CM_ SG_ 272 SOG_MXB_Aufblenden "Synchronisationssignal Aufblenden zwischen MDF und MXB";
CM_ SG_ 272 SOG_MXB_Aufbl_Schaltart "Aufblenden hart oder gedimmt mit Rampe";
CM_ SG_ 272 SOG_Mali_Freigabe_re "Freigabe Markierungslicht rechts duch MDF bei Markierung durch Matrix";
CM_ SG_ 272 SOG_Mali_Freigabe_li "Freigabe Markierungslicht links duch MDF bei Markierung durch Matrix";
CM_ SG_ 272 SOG_SollPos_R "Sollposition 'normierter Lichtindex' für den linken Scheinwerfer in %";
CM_ SG_ 272 SOG_FehlPos_L "gLW Fehlerfallposition des Aktuators im linken Scheinwerfer 

Position komplett Abblenden bedeutet Landstrassenlicht";
CM_ SG_ 272 SOG_FehlPos_R "gLW Fehlerfallposition des Aktuators im rechten Scheinwerfer 

Position komplett Abblenden bedeutet Landstrassenlicht";
CM_ SG_ 272 SOG_RefLauf_L "Referenzlauf des Aktuators im linken Scheinwerfer

Der komplette Bereich von Landstrassenlicht bis hin zu Fernlicht wird abgefahren";
CM_ SG_ 272 SOG_RefLauf_R "Referenzlauf des Aktuators im rechten Scheinwerfer

Der komplette Bereich von Landstrassenlicht bis hin zu Fernlicht wird abgefahren";
CM_ SG_ 272 SOG_StGlTest_L "Stellgliedtest Aktuator linker Scheinwerfer";
CM_ SG_ 272 SOG_StGlTest_R "Stellgliedtest Aktuator rechter Scheinwerfer";
CM_ SG_ 272 SOG_Verkehrsrichtung "Anpassung für Verkehrsrichtung über Codierung
Notwendig für die Referenzierung des 3. Aktuators in Bezug auf die aktuelle Verkehrsart
Die Aktuatorposition Touristenmodus wird über die Sollbotschaften vorgegeben.

Bei Scheinwerferteilenummern die für b";
CM_ SG_ 272 SOG_XenonLeistung_L "Sollwert-Vorgabe Xenius-Brennerleistung
Diagnosefähigkeit / Fehlererkennung erfolgt nur bei eingeschaltetem Brenner";
CM_ SG_ 272 SOG_XenonLeistung_L_Schaltart "Umschaltverhalten bei Leistungsänderung";
CM_ SG_ 272 SOG_XenonLeistung_R "Sollwert-Vorgabe Xenius-Brennerleistung
Diagnosefähigkeit / Fehlererkennung erfolgt nur bei eingeschaltetem Brenner";
CM_ SG_ 272 SOG_XenonLeistung_R_Schaltart "Umschaltverhalten bei Leistungsänderung";
CM_ SG_ 407 SGL_IstPos "Istposition 'normierter Lichtindex' für den linken Scheinwerfer in %";
CM_ SG_ 407 SGL_StaVerst "Verstellung im linken Scheinwerfer
0: keine Verstellung der adaptiven Lichtverteilung
1: Verstellung der adaptiven Lichtverteilung";
CM_ SG_ 407 SGL_StaFehPos "Status Fehlerfallposition linker Scheinwerfer";
CM_ SG_ 407 SGL_StaReflauf "Status Referenzlauf linker Scheinwerfer

Nach erfolgtem Referenzlauf wird  Zustand '1' eingenommen";
CM_ SG_ 407 SGL_StaStGlTst "Stellgliedtest im linken Scheinwerfer";
CM_ SG_ 407 SGL_StagLWElMod "Betrieb mit reduzierter Verstellgeschwindigkeit für gLW 

Wegen Unterspannung oder Übertemperatur 
(dies ist kein Fehler-BIT!)";
CM_ SG_ 407 SGL_StagLWVerkehr "Status Verkehrsrichtung des linken Scheinwerfers

Status in welchem Bereich der gLW-Aktuator eingestellt ist.";
CM_ SG_ 407 SGL_StagLWFernlicht "Status Fernlicht des linken Scheinwerfers";
CM_ SG_ 407 SGL_XenonLeistung "Aktuelle Xenius-Brennerleistung";
CM_ SG_ 409 SGR_IstPos "Istposition 'normierter Lichtindex' für den rechten Scheinwerfer in %";
CM_ SG_ 409 SGR_StaVerst "Verstellung im linken Scheinwerfer
0: keine Verstellung der adaptiven Lichtverteilung
1: Verstellung der adaptiven Lichtverteilung";
CM_ SG_ 409 SGR_StaFehPos "Status Fehlerfallposition rechter Scheinwerfer";
CM_ SG_ 409 SGR_StaReflauf "Status Referenzlauf rechter Scheinwerfer

Nach erfolgtem Referenzlauf wird  Zustand '1' eingenommen";
CM_ SG_ 409 SGR_StaStGlTst "Stellgliedtest im rechten Scheinwerfer";
CM_ SG_ 409 SGR_StagLWElMod "Betrieb mit reduzierter Verstellgeschwindigkeit für gLW 

Wegen Unterspannung oder Übertemperatur 
(dies ist kein Fehler-BIT!)";
CM_ SG_ 409 SGR_StagLWVerkehr "Status Verkehrsrichtung des rechten Scheinwerfers

Status in welchem Bereich der gLW-Aktuator eingestellt ist.";
CM_ SG_ 409 SGR_StagLWFernlicht "Status Fernlicht des rechten Scheinwerfers";
CM_ SG_ 409 SGR_XenonLeistung "Aktuelle Xenius-Brennerleistung";
CM_ SG_ 1792 ISO_ALL_01_Req_Data "Funktionaler Request ALL";
CM_ BO_ 2549874818 "Lichtsteuerung links am Frontlicht-CAN";
CM_ SG_ 2549874818 ISO_LCM_L_Req_Data "Diagnose Request Light Control Module links";
CM_ BO_ 2550005890 "Lichtsteuerung links am Frontlicht-CAN";
CM_ SG_ 2550005890 ISO_LCM_L_Resp_Data "Diagnose Response Light Control Module links";
CM_ BO_ 2549874819 "Lichtsteuerung rechts am Frontlicht-CAN";
CM_ SG_ 2549874819 ISO_LCM_R_Req_Data "Diagnose Request Light Control Module rechts";
CM_ BO_ 2550005891 "Lichtsteuerung rechts am Frontlicht-CAN";
CM_ SG_ 2550005891 ISO_LCM_R_Resp_Data "Diagnose Response Light Control Module rechts";
CM_ BO_ 2549874838 "Lichtsteuerung links am Frontlicht-CAN";
CM_ SG_ 2549874838 ISO_LED_LM_L_Req_Data "Diagnose Request Steuergeraet für LED-Scheinwerfer links";
CM_ BO_ 2550005910 "Lichtsteuerung links am Frontlicht-CAN";
CM_ SG_ 2550005910 ISO_LED_LM_L_Resp_Data "Diagnose Response Steuergeraet für LED-Scheinwerfer links";
CM_ BO_ 2549874839 "Lichtsteuerung rechts am Frontlicht-CAN";
CM_ SG_ 2549874839 ISO_LED_LM_R_Req_Data "Diagnose Request Steuergeraet für LED-Scheinwerfer rechts";
CM_ BO_ 2550005911 "Lichtsteuerung rechts am Frontlicht-CAN";
CM_ SG_ 2550005911 ISO_LED_LM_R_Resp_Data "Diagnose Response Steuergeraet für LED-Scheinwerfer rechts";
CM_ SG_ 791 Kamera_FDD_Obj01_ID "Objekt-ID: Zuordnung einer festen ID zu den Objekten über die Lebenszeit. Damit kann ein Objekttracking im AFS - SG aufgebaut
werden.
";
CM_ SG_ 791 Kamera_FDD_Obj01_Entf_Nah "Genauere Entfernung des erkannten Objekts im Nahbereich (0...100 m).";
CM_ SG_ 791 Kamera_FDD_Obj01_Typ "Objekttyp";
CM_ SG_ 791 Kamera_FDD_Obj01_horizPos "Horizontale Position eines Objekts in Grad. Position bezieht sich auf Objektmitte im Sensorkoordinatensystem. ";
CM_ SG_ 791 Kamera_FDD_Obj01_MehrAlsAchtObj "Detektionsstatus hinsichtlich der Anzahl detektierter Objekte";
CM_ SG_ 791 Kamera_FDD_Obj01_Ersatzw "Objekt entstammt dem Tracking";
CM_ SG_ 791 Kamera_FDD_Obj01_horizDim "Horizontale Ausdehnung eines Objektes";
CM_ SG_ 791 Kamera_FDD_Obj01_vertPos "Verktikale Position eines Objekts. Position bezieht sich auf Unterkante Objekt im Sensorkoordinatensystem. Mathematischer Drehsinn.";
CM_ SG_ 791 Kamera_FDD_Obj01_horizGuete_li "Güte der horizontalen Position (Breite) bzgl. der linken Objektkante. Dieses Signal ersetzt das Signal FDD_Obj01_Guete!";
CM_ SG_ 791 Kamera_FDD_Obj01_horizGuete_re "Güte der horizontalen Position (Breite) bzgl. der rechten Objektkante. Dieses Signal ersetzt das Signal FDD_Obj01_Guete!";
CM_ SG_ 791 Kamera_FDD_Obj01_Entfernung "Eine Entfernungsschzätzung wird anhand des Heckleuchten- und Frontleuchtenabstandes durchgeführt.";
CM_ SG_ 791 Kamera_FDD_Obj01_Objguete "Die Objekt-Güte soll die Qualität der Objektklassifikation darstellen. Bei kleineren Güten ist die Aussage unsicherer.
Ensprechend kann die AFS - Steuerung darauf reagieren und bei unsicheren Objekten die Reaktion verlangsamen.";
CM_ SG_ 799 Kamera_FDD_Obj02_ID "Objekt-ID: Zuordnung einer festen ID zu den Objekten über die Lebenszeit. Damit kann ein Objekttracking im AFS - SG aufgebaut
werden.
";
CM_ SG_ 799 Kamera_FDD_Obj02_Entf_Nah "Genauere Entfernung des erkannten Objekts im Nahbereich (0...100 m).";
CM_ SG_ 799 Kamera_FDD_Obj02_Typ "Objekttyp";
CM_ SG_ 799 Kamera_FDD_Obj02_horizPos "Horizontale Position eines Objekts in Grad. Position bezieht sich auf Objektmitte im Sensorkoordinatensystem. ";
CM_ SG_ 799 Kamera_FDD_Obj02_Ersatzw "Objekt entstammt dem Tracking";
CM_ SG_ 799 Kamera_FDD_Obj02_horizDim "Horizontale Ausdehnung eines Objektes";
CM_ SG_ 799 Kamera_FDD_Obj02_vertPos "Verktikale Position eines Objekts. Position bezieht sich auf Unterkante Objekt im Sensorkoordinatensystem. Mathematischer Drehsinn.";
CM_ SG_ 799 Kamera_FDD_Obj02_horizGuete_li "Güte der horizontalen Position (Breite) bzgl. der linken Objektkante. Dieses Signal ersetzt das Signal FDD_Obj02_Guete!";
CM_ SG_ 799 Kamera_FDD_Obj02_horizGuete_re "Güte der horizontalen Position (Breite) bzgl. der rechten Objektkante. Dieses Signal ersetzt das Signal FDD_Obj02_Guete!";
CM_ SG_ 799 Kamera_FDD_Obj02_Entfernung "Eine Entfernungsschzätzung wird anhand des Heckleuchten- und Frontleuchtenabstandes durchgeführt.";
CM_ SG_ 799 Kamera_FDD_Obj02_Objguete "Die Objekt-Güte soll die Qualität der Objektklassifikation darstellen. Bei kleineren Güten ist die Aussage unsicherer.
Ensprechend kann die AFS - Steuerung darauf reagieren und bei unsicheren Objekten die Reaktion verlangsamen.";
CM_ SG_ 838 Kamera_FDD_Obj03_ID "Objekt-ID: Zuordnung einer festen ID zu den Objekten über die Lebenszeit. Damit kann ein Objekttracking im AFS - SG aufgebaut
werden.
";
CM_ SG_ 838 Kamera_FDD_Obj03_Entf_Nah "Genauere Entfernung des erkannten Objekts im Nahbereich (0...100 m).";
CM_ SG_ 838 Kamera_FDD_Obj03_Typ "Objekttyp";
CM_ SG_ 838 Kamera_FDD_Obj03_horizPos "Horizontale Position eines Objekts in Grad. Position bezieht sich auf Objektmitte im Sensorkoordinatensystem. ";
CM_ SG_ 838 Kamera_FDD_Obj03_Ersatzw "Objekt entstammt dem Tracking";
CM_ SG_ 838 Kamera_FDD_Obj03_horizDim "Horizontale Ausdehnung eines Objektes";
CM_ SG_ 838 Kamera_FDD_Obj03_vertPos "Verktikale Position eines Objekts. Position bezieht sich auf Unterkante Objekt im Sensorkoordinatensystem. Mathematischer Drehsinn.";
CM_ SG_ 838 Kamera_FDD_Obj03_horizGuete_li "Güte der horizontalen Position (Breite) bzgl. der linken Objektkante. Dieses Signal ersetzt das Signal FDD_Obj03_Guete!";
CM_ SG_ 838 Kamera_FDD_Obj03_horizGuete_re "Güte der horizontalen Position (Breite) bzgl. der rechten Objektkante. Dieses Signal ersetzt das Signal FDD_Obj03_Guete!";
CM_ SG_ 838 Kamera_FDD_Obj03_Entfernung "Eine Entfernungsschzätzung wird anhand des Heckleuchten- und Frontleuchtenabstandes durchgeführt.";
CM_ SG_ 838 Kamera_FDD_Obj03_Objguete "Die Objekt-Güte soll die Qualität der Objektklassifikation darstellen. Bei kleineren Güten ist die Aussage unsicherer.
Ensprechend kann die AFS - Steuerung darauf reagieren und bei unsicheren Objekten die Reaktion verlangsamen.";
CM_ SG_ 839 Kamera_FDD_Obj04_ID "Objekt-ID: Zuordnung einer festen ID zu den Objekten über die Lebenszeit. Damit kann ein Objekttracking im AFS - SG aufgebaut
werden.
";
CM_ SG_ 839 Kamera_FDD_Obj04_Entf_Nah "Genauere Entfernung des erkannten Objekts im Nahbereich (0...100 m).";
CM_ SG_ 839 Kamera_FDD_Obj04_Typ "Objekttyp";
CM_ SG_ 839 Kamera_FDD_Obj04_horizPos "Horizontale Position eines Objekts in Grad. Position bezieht sich auf Objektmitte im Sensorkoordinatensystem. ";
CM_ SG_ 839 Kamera_FDD_Obj04_Ersatzw "Objekt entstammt dem Tracking";
CM_ SG_ 839 Kamera_FDD_Obj04_horizDim "Horizontale Ausdehnung eines Objektes";
CM_ SG_ 839 Kamera_FDD_Obj04_vertPos "Verktikale Position eines Objekts. Position bezieht sich auf Unterkante Objekt im Sensorkoordinatensystem. Mathematischer Drehsinn.";
CM_ SG_ 839 Kamera_FDD_Obj04_horizGuete_li "Güte der horizontalen Position (Breite) bzgl. der linken Objektkante. Dieses Signal ersetzt das Signal FDD_Obj04_Guete!";
CM_ SG_ 839 Kamera_FDD_Obj04_horizGuete_re "Güte der horizontalen Position (Breite) bzgl. der rechten Objektkante. Dieses Signal ersetzt das Signal FDD_Obj04_Guete!";
CM_ SG_ 839 Kamera_FDD_Obj04_Entfernung "Eine Entfernungsschzätzung wird anhand des Heckleuchten- und Frontleuchtenabstandes durchgeführt.";
CM_ SG_ 839 Kamera_FDD_Obj04_Objguete "Die Objekt-Güte soll die Qualität der Objektklassifikation darstellen. Bei kleineren Güten ist die Aussage unsicherer.
Ensprechend kann die AFS - Steuerung darauf reagieren und bei unsicheren Objekten die Reaktion verlangsamen.";
CM_ SG_ 840 Kamera_FDD_Obj05_ID "Objekt-ID: Zuordnung einer festen ID zu den Objekten über die Lebenszeit. Damit kann ein Objekttracking im AFS - SG aufgebaut
werden.
";
CM_ SG_ 840 Kamera_FDD_Obj05_Entf_Nah "Genauere Entfernung des erkannten Objekts im Nahbereich (0...100 m).";
CM_ SG_ 840 Kamera_FDD_Obj05_Typ "Objekttyp";
CM_ SG_ 840 Kamera_FDD_Obj05_horizPos "Horizontale Position eines Objekts in Grad. Position bezieht sich auf Objektmitte im Sensorkoordinatensystem. ";
CM_ SG_ 840 Kamera_FDD_Obj05_Ersatzw "Objekt entstammt dem Tracking";
CM_ SG_ 840 Kamera_FDD_Obj05_horizDim "Horizontale Ausdehnung eines Objektes";
CM_ SG_ 840 Kamera_FDD_Obj05_vertPos "Verktikale Position eines Objekts. Position bezieht sich auf Unterkante Objekt im Sensorkoordinatensystem. Mathematischer Drehsinn.";
CM_ SG_ 840 Kamera_FDD_Obj05_horizGuete_li "Güte der horizontalen Position (Breite) bzgl. der linken Objektkante. Dieses Signal ersetzt das Signal FDD_Obj05_Guete!";
CM_ SG_ 840 Kamera_FDD_Obj05_horizGuete_re "Güte der horizontalen Position (Breite) bzgl. der rechten Objektkante. Dieses Signal ersetzt das Signal FDD_Obj05_Guete!";
CM_ SG_ 840 Kamera_FDD_Obj05_Entfernung "Eine Entfernungsschzätzung wird anhand des Heckleuchten- und Frontleuchtenabstandes durchgeführt.";
CM_ SG_ 840 Kamera_FDD_Obj05_Objguete "Die Objekt-Güte soll die Qualität der Objektklassifikation darstellen. Bei kleineren Güten ist die Aussage unsicherer.
Ensprechend kann die AFS - Steuerung darauf reagieren und bei unsicheren Objekten die Reaktion verlangsamen.";
CM_ SG_ 841 Kamera_FDD_Obj06_ID "Objekt-ID: Zuordnung einer festen ID zu den Objekten über die Lebenszeit. Damit kann ein Objekttracking im AFS - SG aufgebaut
werden.
";
CM_ SG_ 841 Kamera_FDD_Obj06_Entf_Nah "Genauere Entfernung des erkannten Objekts im Nahbereich (0...100 m).";
CM_ SG_ 841 Kamera_FDD_Obj06_Typ "Objekttyp";
CM_ SG_ 841 Kamera_FDD_Obj06_horizPos "Horizontale Position eines Objekts in Grad. Position bezieht sich auf Objektmitte im Sensorkoordinatensystem. ";
CM_ SG_ 841 Kamera_FDD_Obj06_Ersatzw "Objekt entstammt dem Tracking";
CM_ SG_ 841 Kamera_FDD_Obj06_horizDim "Horizontale Ausdehnung eines Objektes";
CM_ SG_ 841 Kamera_FDD_Obj06_vertPos "Verktikale Position eines Objekts. Position bezieht sich auf Unterkante Objekt im Sensorkoordinatensystem. Mathematischer Drehsinn.";
CM_ SG_ 841 Kamera_FDD_Obj06_horizGuete_li "Güte der horizontalen Position (Breite) bzgl. der linken Objektkante. Dieses Signal ersetzt das Signal FDD_Obj06_Guete!";
CM_ SG_ 841 Kamera_FDD_Obj06_horizGuete_re "Güte der horizontalen Position (Breite) bzgl. der rechten Objektkante. Dieses Signal ersetzt das Signal FDD_Obj06_Guete!";
CM_ SG_ 841 Kamera_FDD_Obj06_Entfernung "Eine Entfernungsschzätzung wird anhand des Heckleuchten- und Frontleuchtenabstandes durchgeführt.";
CM_ SG_ 841 Kamera_FDD_Obj06_Objguete "Die Objekt-Güte soll die Qualität der Objektklassifikation darstellen. Bei kleineren Güten ist die Aussage unsicherer.
Ensprechend kann die AFS - Steuerung darauf reagieren und bei unsicheren Objekten die Reaktion verlangsamen.";
CM_ SG_ 842 Kamera_FDD_Obj07_ID "Objekt-ID: Zuordnung einer festen ID zu den Objekten über die Lebenszeit. Damit kann ein Objekttracking im AFS - SG aufgebaut
werden.
";
CM_ SG_ 842 Kamera_FDD_Obj07_Entf_Nah "Genauere Entfernung des erkannten Objekts im Nahbereich (0...100 m).";
CM_ SG_ 842 Kamera_FDD_Obj07_Typ "Objekttyp";
CM_ SG_ 842 Kamera_FDD_Obj07_horizPos "Horizontale Position eines Objekts in Grad. Position bezieht sich auf Objektmitte im Sensorkoordinatensystem. ";
CM_ SG_ 842 Kamera_FDD_Obj07_Ersatzw "Objekt entstammt dem Tracking";
CM_ SG_ 842 Kamera_FDD_Obj07_horizDim "Horizontale Ausdehnung eines Objektes";
CM_ SG_ 842 Kamera_FDD_Obj07_vertPos "Verktikale Position eines Objekts. Position bezieht sich auf Unterkante Objekt im Sensorkoordinatensystem. Mathematischer Drehsinn.";
CM_ SG_ 842 Kamera_FDD_Obj07_horizGuete_li "Güte der horizontalen Position (Breite) bzgl. der linken Objektkante. Dieses Signal ersetzt das Signal FDD_Obj07_Guete!";
CM_ SG_ 842 Kamera_FDD_Obj07_horizGuete_re "Güte der horizontalen Position (Breite) bzgl. der rechten Objektkante. Dieses Signal ersetzt das Signal FDD_Obj07_Guete!";
CM_ SG_ 842 Kamera_FDD_Obj07_Entfernung "Eine Entfernungsschzätzung wird anhand des Heckleuchten- und Frontleuchtenabstandes durchgeführt.";
CM_ SG_ 842 Kamera_FDD_Obj07_Objguete "Die Objekt-Güte soll die Qualität der Objektklassifikation darstellen. Bei kleineren Güten ist die Aussage unsicherer.
Ensprechend kann die AFS - Steuerung darauf reagieren und bei unsicheren Objekten die Reaktion verlangsamen.";
CM_ SG_ 843 Kamera_FDD_Obj08_ID "Objekt-ID: Zuordnung einer festen ID zu den Objekten über die Lebenszeit. Damit kann ein Objekttracking im AFS - SG aufgebaut
werden.
";
CM_ SG_ 843 Kamera_FDD_Obj08_Entf_Nah "Genauere Entfernung des erkannten Objekts im Nahbereich (0...100 m).";
CM_ SG_ 843 Kamera_FDD_Obj08_Typ "Objekttyp";
CM_ SG_ 843 Kamera_FDD_Obj08_horizPos "Horizontale Position eines Objekts in Grad. Position bezieht sich auf Objektmitte im Sensorkoordinatensystem. ";
CM_ SG_ 843 Kamera_FDD_Obj08_Ersatzw "Objekt entstammt dem Tracking";
CM_ SG_ 843 Kamera_FDD_Obj08_horizDim "Horizontale Ausdehnung eines Objektes";
CM_ SG_ 843 Kamera_FDD_Obj08_vertPos "Verktikale Position eines Objekts. Position bezieht sich auf Unterkante Objekt im Sensorkoordinatensystem. Mathematischer Drehsinn.";
CM_ SG_ 843 Kamera_FDD_Obj08_horizGuete_li "Güte der horizontalen Position (Breite) bzgl. der linken Objektkante. Dieses Signal ersetzt das Signal FDD_Obj08_Guete!";
CM_ SG_ 843 Kamera_FDD_Obj08_horizGuete_re "Güte der horizontalen Position (Breite) bzgl. der rechten Objektkante. Dieses Signal ersetzt das Signal FDD_Obj08_Guete!";
CM_ SG_ 843 Kamera_FDD_Obj08_Entfernung "Eine Entfernungsschzätzung wird anhand des Heckleuchten- und Frontleuchtenabstandes durchgeführt.";
CM_ SG_ 843 Kamera_FDD_Obj08_Objguete "Die Objekt-Güte soll die Qualität der Objektklassifikation darstellen. Bei kleineren Güten ist die Aussage unsicherer.
Ensprechend kann die AFS - Steuerung darauf reagieren und bei unsicheren Objekten die Reaktion verlangsamen.";
CM_ SG_ 792 Kamera_Systemzustand "Systemzustand der Kamera";
CM_ SG_ 792 Kamera_FDD_Eigenblend_Guete "Diese Signal gibt an, welches Maß einer Eigenblendung vorliegt.";
CM_ SG_ 792 Kamera_FDD_Eigenblend "Dieses Signal gibt an, ob von der Kamera eine Eigenblendung, z.B. Nebel, erkannt wird.";
CM_ SG_ 792 Kamera_FDD_Strassenbeleuchung "Status Straßenbeleuchungsdetektion";
CM_ SG_ 792 Kamera_FDD_Funktionsstatus "Status der Fahrzeugdetektion bei Dunkelheit";
CM_ SG_ 792 Kamera_FDD_Anz_Strassenleuchten "Anzahl der erkannten Straßenleuchten";
CM_ SG_ 792 Kamera_FDD_Verkehrsrichtung "Gibt bei Nacht die auf Grund der entgegenkommenden Fahrzeuge erkannte Verkehrsrichtung an";
CM_ SG_ 792 Kamera_FSH_aktiv "Bei aktivierter (lokaler) Frontscheibenheizung wird die Scheibentemperaturmessung des Klimafeuchtesensors beeinflusst. Über das Signal wird dem Klima-SG mitgeteilt, dass die lokale Scheibenheizung aktiviert ist, um entsprechende Korrekturwerte bei der Sch";
CM_ SG_ 792 Kamera_KD_Fehler "Status Kundendienstfehlerspeichereinträge
";
CM_ BO_ 960 "MQB";
CM_ SG_ 960 RSt_Fahrerhinweise "Über das Signal fordert das BCM Fahrerhinweise im Kombi für die Funktion RemoteStart an.";
CM_ SG_ 960 ZAS_Kl_15 "Klemme 15: Zuendung (SW-Kl.15)
";
CM_ SG_ 960 BCM_Ausparken_Betrieb "Anforderung zur erneuten Lampenaufprüfung und Anzeige von Warnhinweisen nach einem pilotierten Ausparkvorgang (Trigger: fallende Flanke)";
CM_ SG_ 2549088386 LCM_L_KompSchutz "Funktionseinschränkung aufgrund Komponentenschutz aktiv";
CM_ SG_ 2549088386 LCM_L_Abschaltstufe "Funktionseinschränkung aufgrund aktiver Abschaltstufe";
CM_ SG_ 2549088386 LCM_L_Transport_Mode "Funktionseinschränkung aufgrund aktivem Transport Mode und/oder Transport Schutz
";
CM_ SG_ 2549088386 LCM_L_Nachlauftyp "Abgebildet wird die von der Hardware vorgegebene Möglichkeit, die Kommunikation nach Klemme 15 = AUS aufrecht zu erhalten. Es wird ein Init-Wert gesendet.
0 = Kommunikation nur bei KL15=EIN (kein Nachlauf, nicht weckfähig)
1 = Kommunikation nach KL15=AU";
CM_ SG_ 2549088386 LCM_L_SNI "Das Signal beinhaltet den Source Node Identifier (Knotenadresse, die auch in der Abbildungsvorschrift zur CAN-ID für die NM-High Botschaft verwendet wird).";
CM_ SG_ 2549088386 NM_LCM_L_Wakeup "enthält die Weckursache; stehen mehrere Weckursachen parallel an, dann muss der kleinste Wert übertragen werden";
CM_ SG_ 2549088386 NM_LCM_L_Lokalaktiv "Zeigt an ob das SG nach Klemme15 AUS und nach entsprechender MAX Aktivzeit noch aktiv war";
CM_ SG_ 2549088386 NM_LCM_L_Subsystemaktiv "Zeigt an ob ein Subsystem des SGs nach Klemme15 AUS und nach entsprechender MAX Aktivzeit noch aktiv war";
CM_ SG_ 2549088386 LCM_L_KD_Fehler "Status Kundendienst-Fehlerspeicher";
CM_ SG_ 2549088387 LCM_R_KompSchutz "Funktionseinschränkung aufgrund Komponentenschutz aktiv";
CM_ SG_ 2549088387 LCM_R_Abschaltstufe "Funktionseinschränkung aufgrund aktiver Abschaltstufe";
CM_ SG_ 2549088387 LCM_R_Transport_Mode "Funktionseinschränkung aufgrund aktivem Transport Mode und/oder Transport Schutz
";
CM_ SG_ 2549088387 LCM_R_Nachlauftyp "Abgebildet wird die von der Hardware vorgegebene Möglichkeit, die Kommunikation nach Klemme 15 = AUS aufrecht zu erhalten. Es wird ein Init-Wert gesendet.
0 = Kommunikation nur bei KL15=EIN (kein Nachlauf, nicht weckfähig)
1 = Kommunikation nach KL15=AU";
CM_ SG_ 2549088387 LCM_R_SNI "Das Signal beinhaltet den Source Node Identifier (Knotenadresse, die auch in der Abbildungsvorschrift zur CAN-ID für die NM-High Botschaft verwendet wird).";
CM_ SG_ 2549088387 NM_LCM_R_Wakeup "enthält die Weckursache; stehen mehrere Weckursachen parallel an, dann muss der kleinste Wert übertragen werden";
CM_ SG_ 2549088387 NM_LCM_R_Lokalaktiv "Zeigt an ob das SG nach Klemme15 AUS und nach entsprechender MAX Aktivzeit noch aktiv war";
CM_ SG_ 2549088387 NM_LCM_R_Subsystemaktiv "Zeigt an ob ein Subsystem des SGs nach Klemme15 AUS und nach entsprechender MAX Aktivzeit noch aktiv war";
CM_ SG_ 2549088387 LCM_R_KD_Fehler "Status Kundendienst-Fehlerspeicher";
CM_ SG_ 2549088406 LED_DK3_L_KompSchutz "Funktionseinschränkung aufgrund Komponentenschutz aktiv";
CM_ SG_ 2549088406 LED_DK3_L_Abschaltstufe "Funktionseinschränkung aufgrund aktiver Abschaltstufe";
CM_ SG_ 2549088406 LED_DK3_L_Transport_Mode "Funktionseinschränkung aufgrund aktivem Transport Mode und/oder Transport Schutz
";
CM_ SG_ 2549088406 LED_DK3_L_Nachlauftyp "Abgebildet wird die von der Hardware vorgegebene Möglichkeit, die Kommunikation nach Klemme 15 = AUS aufrecht zu erhalten. Es wird ein Init-Wert gesendet.
0 = Kommunikation nur bei KL15=EIN (kein Nachlauf, nicht weckfähig)
1 = Kommunikation nach KL15=AU";
CM_ SG_ 2549088406 LED_DK3_L_SNI "Das Signal beinhaltet den Source Node Identifier (Knotenadresse, die auch in der Abbildungsvorschrift zur CAN-ID für die NM-High Botschaft verwendet wird).
";
CM_ SG_ 2549088406 NM_LED_DK3_L_Wakeup "enthält die Weckursache; stehen mehrere Weckursachen parallel an, dann muss der kleinste Wert übertragen werden";
CM_ SG_ 2549088406 NM_LED_DK3_L_Lokalaktiv "Zeigt an ob das SG nach Klemme15 AUS und nach entsprechender MAX Aktivzeit noch aktiv war";
CM_ SG_ 2549088406 LED_DK3_L_KD_Fehler "Status Kundendienst-Fehlerspeicher";
CM_ SG_ 2549088407 LED_DK3_R_KompSchutz "Funktionseinschränkung aufgrund Komponentenschutz aktiv";
CM_ SG_ 2549088407 LED_DK3_R_Abschaltstufe "Funktionseinschränkung aufgrund aktiver Abschaltstufe";
CM_ SG_ 2549088407 LED_DK3_R_Transport_Mode "Funktionseinschränkung aufgrund aktivem Transport Mode und/oder Transport Schutz
";
CM_ SG_ 2549088407 LED_DK3_R_Nachlauftyp "Abgebildet wird die von der Hardware vorgegebene Möglichkeit, die Kommunikation nach Klemme 15 = AUS aufrecht zu erhalten. Es wird ein Init-Wert gesendet.
0 = Kommunikation nur bei KL15=EIN (kein Nachlauf, nicht weckfähig)
1 = Kommunikation nach KL15=AU";
CM_ SG_ 2549088407 LED_DK3_R_SNI "Das Signal beinhaltet den Source Node Identifier (Knotenadresse, die auch in der Abbildungsvorschrift zur CAN-ID für die NM-High Botschaft verwendet wird).
";
CM_ SG_ 2549088407 NM_LED_DK3_R_Wakeup "enthält die Weckursache; stehen mehrere Weckursachen parallel an, dann muss der kleinste Wert übertragen werden";
CM_ SG_ 2549088407 NM_LED_DK3_R_Lokalaktiv "Zeigt an ob das SG nach Klemme15 AUS und nach entsprechender MAX Aktivzeit noch aktiv war";
CM_ SG_ 2549088407 LED_DK3_R_KD_Fehler "Status Kundendienst-Fehlerspeicher";
CM_ SG_ 1387 LCM_Feh_L_CRC "Checksumme mit CRC8";
CM_ SG_ 1387 LCM_Feh_L_BZ "Botschaftszaehler";
CM_ SG_ 1387 LCM_TFL_Fehler_L "TFL Fehler";
CM_ SG_ 1387 LCM_Sonstiger_Fehler_L "Sonstiger Fehler";
CM_ SG_ 1387 LCM_SM_Fehler_L "Sidemarker Fehler";
CM_ SG_ 1387 LCM_Shutter_Fehler_L "Shutter Fehler";
CM_ SG_ 1387 LCM_PO_Fehler_L "PO Fehler";
CM_ SG_ 1387 LCM_Blinker_Fehler_L "Blinker Fehler";
CM_ SG_ 1387 LCM_LWR_L_allg_Fehler "Allgemeiner Schrittmotor-Fehler im linken LCM.";
CM_ SG_ 1387 LCM_LWR_L_defekt_Fehler "Allgemeiner LWR-Fehler im linken LCM.";
CM_ SG_ 1387 LCM_Datensatz_Fehler_L "zeigt einen vorliegenden Datensatz Fehler im LCM an (fehlender bzw. unplausibler Datensatz)";
CM_ SG_ 1387 LCM_DKL_L_defekt_Fehler "Sammel-Fehlerbit für den Ausfall der Funktion DKL";
CM_ SG_ 1387 LCM_GLW_L_defekt_Fehler "Sammel-Fehlerbit für den Ausfall der Funktion GLW";
CM_ SG_ 1387 LCM_SKL_L_defekt_Fehler "Sammel-Fehlerbit für den Ausfall der Funktion SKL";
CM_ SG_ 1388 LCM_Feh_R_CRC "Checksumme mit CRC8";
CM_ SG_ 1388 LCM_Feh_R_BZ "Botschaftszaehler";
CM_ SG_ 1388 LCM_TFL_Fehler_R "TFL Fehler";
CM_ SG_ 1388 LCM_Sonstiger_Fehler_R "Sonstiger Fehler";
CM_ SG_ 1388 LCM_SM_Fehler_R "Sidemarker Fehler";
CM_ SG_ 1388 LCM_Shutter_Fehler_R "Shutter Fehler";
CM_ SG_ 1388 LCM_PO_Fehler_R "PO Fehler";
CM_ SG_ 1388 LCM_Blinker_Fehler_R "Blinker Fehler";
CM_ SG_ 1388 LCM_LWR_R_allg_Fehler "Allgemeiner Schrittmotor-Fehler im rechten LCM.";
CM_ SG_ 1388 LCM_LWR_R_defekt_Fehler "LWR defekt im rechten LCM.";
CM_ SG_ 1388 LCM_Datensatz_Fehler_R "zeigt einen vorliegenden Datensatz Fehler im LCM an (fehlender bzw. unplausibler Datensatz)";
CM_ SG_ 1388 LCM_DKL_R_defekt_Fehler "Sammel-Fehlerbit für den Ausfall der Funktion DKL";
CM_ SG_ 1388 LCM_GLW_R_defekt_Fehler "Sammel-Fehlerbit für den Ausfall der Funktion GLW";
CM_ SG_ 1388 LCM_SKL_R_defekt_Fehler "Sammel-Fehlerbit für den Ausfall der Funktion SKL";
CM_ SG_ 403 LCM_Soll_CRC "Checksumme nach CRC8 Algo";
CM_ SG_ 403 LCM_Soll_BZ "Botschaftszaehler";
CM_ SG_ 403 LCM_TFL_L_Anf "TFL Ansteuerung links";
CM_ SG_ 403 LCM_TFL_R_Anf "TFL Ansteuerung rechts";
CM_ SG_ 403 LCM_Abschaltung_Vbat_L_Anf "Anfrage Abschaltung Vbat LCM links";
CM_ SG_ 403 LCM_Abschaltung_Vbat_R_Anf "Anfrage Abschaltung Vbat LCM rechts";
CM_ SG_ 403 LCM_Blinker_L_Anf "Blinker Ansteuerung links (inkl.Takt)";
CM_ SG_ 403 LCM_Blinker_R_Anf "Blinker Ansteuerung rechts (inkl.Takt)";
CM_ SG_ 403 LCM_Blinkerzyklus_L "Blinkfunktion/zyklus links (in)aktiv";
CM_ SG_ 403 LCM_Blinkerzyklus_R "Blinkfunktion/zyklus rechts (in)aktiv";
CM_ SG_ 403 LCM_Sh_L_Anf "Shutter Ansteuerung links";
CM_ SG_ 403 LCM_Sh_R_Anf "Shutter Ansteuerung rechts";
CM_ SG_ 403 LCM_SM_L_Anf "Sidemarker Ansteuerung links";
CM_ SG_ 403 LCM_SM_R_Anf "Sidemarker Ansteuerung rechts";
CM_ SG_ 403 LCM_univ_1_L_Anf "zusätzlicher High Side Schalter links";
CM_ SG_ 403 LCM_univ_1_R_Anf "zusätzlicher High Side Schalter rechts";
CM_ SG_ 403 LCM_PO_L_Anf "PO Ansteuerung links";
CM_ SG_ 403 LCM_PO_R_Anf "PO Ansteuerung rechts";
CM_ SG_ 403 LCM_PL_L_Anf "PL Ansteuerung links";
CM_ SG_ 403 LCM_PL_R_Anf "PL Ansteuerung rechts";
CM_ SG_ 403 LCM_Leistungsreduzierung_Anf "Anfrage Leistungsreduzierung (BCM1 -->  LCM)";
CM_ SG_ 403 LCM_Blinkerwischen_Anf "Anforderung Blinkerwischen";
CM_ SG_ 403 LCM_Animiertes_TFL_Anf "Anforderung TFL-Animation";
CM_ SG_ 403 LCM_Signaturlicht_Anf "Ansteuerung Signaturlicht";
CM_ SG_ 403 LCM_ECE_SAE_Umschaltung_Anf "Anforderung Umschaltung für LCM";
CM_ SG_ 403 BM_Autobahn "Status Autobahnblinken
";
CM_ SG_ 403 BM_ZV_auf "Blinken bei ZV auf

";
CM_ SG_ 403 BM_ZV_zu "Blinken bei ZV zu

";
CM_ SG_ 403 BCM1_CH_aktiv "Coming Home (zusätzlich zum Signal 'BCM1_CH_LH_aktiv' in der Botschaft BCM1_01)";
CM_ SG_ 403 BCM1_LH_aktiv "Leaving Home (zusätzlich zum Signal 'BCM1_CH_LH_aktiv' in der Botschaft BCM1_01)";
CM_ SG_ 411 LCM_Sta_L_CRC "Checksumme nach CRC8 Algo";
CM_ SG_ 411 LCM_Sta_L_BZ "Botschaftszaehler";
CM_ SG_ 411 LCM_Ausgangsleistungsred_L_Sta "Info Ausgangsleistungsreduzierung";
CM_ SG_ 411 LCM_Abschaltbestaetigung_L "Handshake - LCM bestätigt Anfrage";
CM_ SG_ 411 LCM_Blinker_L_Sta "Blinker Status links";
CM_ SG_ 411 LCM_PL_L_Sta "PL Status links";
CM_ SG_ 411 LCM_PO_L_Sta "PO Status links";
CM_ SG_ 411 LCM_Sh_L_Sta "Shutter Status links";
CM_ SG_ 411 LCM_SM_L_Sta "Sidemarker Status links";
CM_ SG_ 411 LCM_TFL_L_Sta "TFL Status links";
CM_ SG_ 411 LCM_univ_1_L_Sta "Status zusätzlicher High Side Schalter links";
CM_ SG_ 413 LCM_Sta_R_CRC "Checksumme nach CRC8 Algo";
CM_ SG_ 413 LCM_Sta_R_BZ "Botschaftszaehler";
CM_ SG_ 413 LCM_Ausgangsleistungsred_R_Sta "Info Ausgangsleistungsreduzierung";
CM_ SG_ 413 LCM_Abschaltbestaetigung_R "Handshake - LCM bestätigt Anfrage";
CM_ SG_ 413 LCM_Blinker_R_Sta "Blinker Status rechts";
CM_ SG_ 413 LCM_PL_R_Sta "PL Status rechts";
CM_ SG_ 413 LCM_PO_R_Sta "PO Status rechts";
CM_ SG_ 413 LCM_Sh_R_Sta "Shutter Status rechts";
CM_ SG_ 413 LCM_SM_R_Sta "Sidemarker Status rechts";
CM_ SG_ 413 LCM_TFL_R_Sta "TFL Status rechts";
CM_ SG_ 413 LCM_univ_1_R_Sta "Status zusätzlicher High Side Schalter rechts";
BA_DEF_ BO_  "DiagRequest" ENUM  "No","Yes";
BA_DEF_ BO_  "DiagResponse" ENUM  "No","Yes";
BA_DEF_ BO_  "DiagState" ENUM  "No","Yes";
BA_DEF_ BO_  "GenMsgChkConstant" HEX 0 4095;
BA_DEF_ BO_  "GenMsgCycleTime" INT 0 65535;
BA_DEF_ BO_  "GenMsgCycleTimeFast" INT 0 65535;
BA_DEF_ BO_  "GenMsgDelayTime" INT 0 100000;
BA_DEF_ BO_  "GenMsgILSupport" ENUM  "No","Yes";
BA_DEF_ BO_  "GenMsgNrOfRepetition" INT 0 100;
BA_DEF_ BO_  "GenMsgPDUConstants" STRING ;
BA_DEF_ BO_  "GenMsgSendType" ENUM  "Cyclic","not_used","not_used","not_used","not_used","not_used","not_used","IfActive","NoMsgSendType";
BA_DEF_ BO_  "GenMsgStartDelayTime" INT 0 100000;
BA_DEF_ BO_  "NmMessage" ENUM  "No","Yes";
BA_DEF_ BO_  "NmhMessage" ENUM  "No","Yes";
BA_DEF_ BO_  "MsgType" ENUM  "Application","NM ","NMH","TP2.0","ISO-TP ","BAP","EID","KS";
BA_DEF_ BO_  "VAGTP20_API" HEX 0 255;
BA_DEF_ BO_  "VAGTP20_DynConnection" ENUM  "No","Yes";
BA_DEF_ BO_  "VAGTP20_DynSetup" ENUM  "No","Yes";
BA_DEF_ BO_  "VAGTP20_StatConnection" ENUM  "No","Yes";
BA_DEF_ SG_  "GenSigActiveRepetitions" INT -2147483648 2147483647;
BA_DEF_ SG_  "GenSigSendType" ENUM  "Cyclic","OnWrite","OnWriteWithRepetition","OnChange","OnChangeWithRepetition","IfActive","IfActiveWithRepetition","NoSigSendType","OnChangeAndIfActive","OnChangeAndIfActiveWithRepetition";
BA_DEF_ SG_  "GenSigStartValue" INT -2147483648 2147483647;
BA_DEF_ SG_  "NWM-WakeupAllowed" ENUM  "No","Yes";
BA_DEF_ SG_  "GenSigFuncType" ENUM  "NoFunction","MsgCounter","CRC-8","XOR","XOR-2","DatedBit","SW-Kl15","CHK","Constant","Protocol","CRC-8-SAE_J1850";
BA_DEF_ SG_  "GenSigSwitchedByIgnition" ENUM  "No","Yes";
BA_DEF_ SG_  "Fehlerwert" HEX 0 2147483647;
BA_DEF_ SG_  "GenSigMissingSourceValue" HEX 0 2147483647;
BA_DEF_REL_ BU_SG_REL_  "GenSigTimeoutTime" INT 0 65535;
BA_DEF_DEF_  "DiagRequest" "No";
BA_DEF_DEF_  "DiagResponse" "No";
BA_DEF_DEF_  "DiagState" "No";
BA_DEF_DEF_  "GenMsgChkConstant" 0;
BA_DEF_DEF_  "GenMsgCycleTime" 0;
BA_DEF_DEF_  "GenMsgCycleTimeFast" 0;
BA_DEF_DEF_  "GenMsgDelayTime" 0;
BA_DEF_DEF_  "GenMsgILSupport" "No";
BA_DEF_DEF_  "GenMsgNrOfRepetition" 0;
BA_DEF_DEF_  "GenMsgPDUConstants" "";
BA_DEF_DEF_  "GenMsgSendType" "NoMsgSendType";
BA_DEF_DEF_  "GenMsgStartDelayTime" 0;
BA_DEF_DEF_  "NmMessage" "No";
BA_DEF_DEF_  "NmhMessage" "No";
BA_DEF_DEF_  "MsgType" "Application";
BA_DEF_DEF_  "VAGTP20_API" 0;
BA_DEF_DEF_  "VAGTP20_DynConnection" "No";
BA_DEF_DEF_  "VAGTP20_DynSetup" "No";
BA_DEF_DEF_  "VAGTP20_StatConnection" "No";
BA_DEF_DEF_  "GenSigActiveRepetitions" 0;
BA_DEF_DEF_  "GenSigSendType" "NoSigSendType";
BA_DEF_DEF_  "GenSigStartValue" 0;
BA_DEF_DEF_  "NWM-WakeupAllowed" "No";
BA_DEF_DEF_  "GenSigFuncType" "NoFunction";
BA_DEF_DEF_  "GenSigSwitchedByIgnition" "Yes";
BA_DEF_DEF_  "Fehlerwert" 0;
BA_DEF_DEF_  "GenSigMissingSourceValue" 0;
BA_DEF_DEF_REL_ "GenSigTimeoutTime" 0;
BA_ "GenMsgCycleTime" BO_ 919 100;
BA_ "GenMsgILSupport" BO_ 919 1;
BA_ "GenMsgSendType" BO_ 919 0;
BA_ "GenMsgCycleTime" BO_ 272 10;
BA_ "GenMsgILSupport" BO_ 272 1;
BA_ "GenMsgSendType" BO_ 272 0;
BA_ "GenMsgCycleTime" BO_ 407 10;
BA_ "GenMsgILSupport" BO_ 407 1;
BA_ "GenMsgSendType" BO_ 407 0;
BA_ "GenMsgCycleTime" BO_ 409 10;
BA_ "GenMsgILSupport" BO_ 409 1;
BA_ "GenMsgSendType" BO_ 409 0;
BA_ "DiagState" BO_ 1792 1;
BA_ "MsgType" BO_ 1792 4;
BA_ "DiagRequest" BO_ 2549874818 1;
BA_ "MsgType" BO_ 2549874818 4;
BA_ "DiagResponse" BO_ 2550005890 1;
BA_ "MsgType" BO_ 2550005890 4;
BA_ "DiagRequest" BO_ 2549874819 1;
BA_ "MsgType" BO_ 2549874819 4;
BA_ "DiagResponse" BO_ 2550005891 1;
BA_ "MsgType" BO_ 2550005891 4;
BA_ "DiagRequest" BO_ 2549874838 1;
BA_ "MsgType" BO_ 2549874838 4;
BA_ "DiagResponse" BO_ 2550005910 1;
BA_ "MsgType" BO_ 2550005910 4;
BA_ "DiagRequest" BO_ 2549874839 1;
BA_ "MsgType" BO_ 2549874839 4;
BA_ "DiagResponse" BO_ 2550005911 1;
BA_ "MsgType" BO_ 2550005911 4;
BA_ "GenMsgCycleTime" BO_ 791 40;
BA_ "GenMsgILSupport" BO_ 791 1;
BA_ "GenMsgSendType" BO_ 791 0;
BA_ "GenMsgStartDelayTime" BO_ 791 15;
BA_ "GenMsgCycleTime" BO_ 799 40;
BA_ "GenMsgILSupport" BO_ 799 1;
BA_ "GenMsgSendType" BO_ 799 0;
BA_ "GenMsgStartDelayTime" BO_ 799 15;
BA_ "GenMsgCycleTime" BO_ 838 40;
BA_ "GenMsgILSupport" BO_ 838 1;
BA_ "GenMsgSendType" BO_ 838 0;
BA_ "GenMsgStartDelayTime" BO_ 838 15;
BA_ "GenMsgCycleTime" BO_ 839 40;
BA_ "GenMsgILSupport" BO_ 839 1;
BA_ "GenMsgSendType" BO_ 839 0;
BA_ "GenMsgStartDelayTime" BO_ 839 15;
BA_ "GenMsgCycleTime" BO_ 840 40;
BA_ "GenMsgILSupport" BO_ 840 1;
BA_ "GenMsgSendType" BO_ 840 0;
BA_ "GenMsgStartDelayTime" BO_ 840 20;
BA_ "GenMsgCycleTime" BO_ 841 40;
BA_ "GenMsgILSupport" BO_ 841 1;
BA_ "GenMsgSendType" BO_ 841 0;
BA_ "GenMsgStartDelayTime" BO_ 841 20;
BA_ "GenMsgCycleTime" BO_ 842 40;
BA_ "GenMsgILSupport" BO_ 842 1;
BA_ "GenMsgSendType" BO_ 842 0;
BA_ "GenMsgStartDelayTime" BO_ 842 20;
BA_ "GenMsgCycleTime" BO_ 843 40;
BA_ "GenMsgILSupport" BO_ 843 1;
BA_ "GenMsgSendType" BO_ 843 0;
BA_ "GenMsgStartDelayTime" BO_ 843 20;
BA_ "GenMsgCycleTime" BO_ 792 80;
BA_ "GenMsgILSupport" BO_ 792 1;
BA_ "GenMsgSendType" BO_ 792 0;
BA_ "GenMsgStartDelayTime" BO_ 792 25;
BA_ "GenMsgChkConstant" BO_ 960 195;
BA_ "GenMsgCycleTime" BO_ 960 100;
BA_ "GenMsgDelayTime" BO_ 960 10;
BA_ "GenMsgILSupport" BO_ 960 1;
BA_ "GenMsgPDUConstants" BO_ 960 "0xc3,0xc3,0xc3,0xc3,0xc3,0xc3,0xc3,0xc3,0xc3,0xc3,0xc3,0xc3,0xc3,0xc3,0xc3,0xc3";
BA_ "GenMsgSendType" BO_ 960 0;
BA_ "GenMsgCycleTime" BO_ 2549088386 500;
BA_ "GenMsgILSupport" BO_ 2549088386 1;
BA_ "GenMsgSendType" BO_ 2549088386 0;
BA_ "GenMsgCycleTime" BO_ 2549088387 500;
BA_ "GenMsgILSupport" BO_ 2549088387 1;
BA_ "GenMsgSendType" BO_ 2549088387 0;
BA_ "GenMsgCycleTime" BO_ 2549088406 500;
BA_ "GenMsgILSupport" BO_ 2549088406 1;
BA_ "GenMsgSendType" BO_ 2549088406 0;
BA_ "GenMsgCycleTime" BO_ 2549088407 500;
BA_ "GenMsgILSupport" BO_ 2549088407 1;
BA_ "GenMsgSendType" BO_ 2549088407 0;
BA_ "GenMsgCycleTime" BO_ 1387 200;
BA_ "GenMsgILSupport" BO_ 1387 1;
BA_ "GenMsgPDUConstants" BO_ 1387 "0x37,0x11,0x60,0x17,0x81,0xbb,0x2c,0xaa,0xf1,0xd0,0x34,0x83,0x2e,0xe1,0xf9,0x8e";
BA_ "GenMsgSendType" BO_ 1387 0;
BA_ "GenMsgCycleTime" BO_ 1388 200;
BA_ "GenMsgILSupport" BO_ 1388 1;
BA_ "GenMsgPDUConstants" BO_ 1388 "0x71,0xf9,0x43,0x22,0xe4,0xa9,0x1c,0x67,0x2b,0x16,0x7f,0x15,0xe0,0x97,0x20,0x4e";
BA_ "GenMsgSendType" BO_ 1388 0;
BA_ "GenMsgCycleTime" BO_ 403 100;
BA_ "GenMsgDelayTime" BO_ 403 10;
BA_ "GenMsgILSupport" BO_ 403 1;
BA_ "GenMsgPDUConstants" BO_ 403 "0xbd,0x44,0x90,0x8d,0x74,0xfa,0x91,0x89,0x41,0x4a,0xbe,0x82,0xb3,0x05,0x84,0xcf";
BA_ "GenMsgSendType" BO_ 403 0;
BA_ "GenMsgCycleTime" BO_ 411 100;
BA_ "GenMsgDelayTime" BO_ 411 10;
BA_ "GenMsgILSupport" BO_ 411 1;
BA_ "GenMsgPDUConstants" BO_ 411 "0x8c,0x9c,0xb7,0x80,0xd8,0x98,0x32,0x5c,0xdd,0xc3,0x44,0xb9,0xb2,0xa8,0xd9,0xce";
BA_ "GenMsgSendType" BO_ 411 0;
BA_ "GenMsgCycleTime" BO_ 413 100;
BA_ "GenMsgDelayTime" BO_ 413 10;
BA_ "GenMsgILSupport" BO_ 413 1;
BA_ "GenMsgPDUConstants" BO_ 413 "0x4b,0xdb,0xbe,0x71,0xa6,0x31,0x56,0xf9,0xc8,0x26,0xe3,0x43,0x0a,0x6d,0x29,0x22";
BA_ "GenMsgSendType" BO_ 413 0;
BA_ "GenSigSendType" SG_ 919 FGR_Akt_KS_Plus 0;
BA_ "Fehlerwert" SG_ 919 FGR_Akt_KS_Plus 1;
BA_ "GenSigSendType" SG_ 919 FGR_RAkt_KS_Plus 0;
BA_ "GenSigStartValue" SG_ 919 FGR_RAkt_KS_Plus 1;
BA_ "GenSigSendType" SG_ 919 FGR_Akt_KS_Gnd 0;
BA_ "Fehlerwert" SG_ 919 FGR_Akt_KS_Gnd 1;
BA_ "GenSigSendType" SG_ 919 FGR_RAkt_KS_Gnd 0;
BA_ "GenSigStartValue" SG_ 919 FGR_RAkt_KS_Gnd 1;
BA_ "GenSigSendType" SG_ 919 FGR_Akt_OL 0;
BA_ "Fehlerwert" SG_ 919 FGR_Akt_OL 1;
BA_ "GenSigSendType" SG_ 919 FGR_RAkt_OL 0;
BA_ "GenSigStartValue" SG_ 919 FGR_RAkt_OL 1;
BA_ "GenSigSendType" SG_ 919 FGR_Akt_UeSpg 0;
BA_ "Fehlerwert" SG_ 919 FGR_Akt_UeSpg 1;
BA_ "GenSigSendType" SG_ 919 FGR_RAkt_UeSpg 0;
BA_ "GenSigStartValue" SG_ 919 FGR_RAkt_UeSpg 1;
BA_ "GenSigSendType" SG_ 919 FGR_Akt_USpg 0;
BA_ "Fehlerwert" SG_ 919 FGR_Akt_USpg 1;
BA_ "GenSigSendType" SG_ 919 FGR_RAkt_USpg 0;
BA_ "GenSigStartValue" SG_ 919 FGR_RAkt_USpg 1;
BA_ "GenSigSendType" SG_ 919 FGR_Akt_UeTemp 0;
BA_ "Fehlerwert" SG_ 919 FGR_Akt_UeTemp 1;
BA_ "GenSigSendType" SG_ 919 FGR_RAkt_UeTemp 0;
BA_ "GenSigStartValue" SG_ 919 FGR_RAkt_UeTemp 1;
BA_ "GenSigSendType" SG_ 919 FGR_Akt_TempPre 0;
BA_ "GenSigSendType" SG_ 919 FGR_RAkt_TempPre 0;
BA_ "GenSigStartValue" SG_ 919 FGR_RAkt_TempPre 1;
BA_ "GenSigSendType" SG_ 919 FGR_HS_KS_Plus 0;
BA_ "Fehlerwert" SG_ 919 FGR_HS_KS_Plus 1;
BA_ "GenSigSendType" SG_ 919 FGR_RHS_KS_Plus 0;
BA_ "GenSigStartValue" SG_ 919 FGR_RHS_KS_Plus 1;
BA_ "GenSigSendType" SG_ 919 FGR_HS_KS_Gnd 0;
BA_ "Fehlerwert" SG_ 919 FGR_HS_KS_Gnd 1;
BA_ "GenSigSendType" SG_ 919 FGR_RHS_KS_Gnd 0;
BA_ "GenSigStartValue" SG_ 919 FGR_RHS_KS_Gnd 1;
BA_ "GenSigSendType" SG_ 919 FGR_HS_unplSign 0;
BA_ "Fehlerwert" SG_ 919 FGR_HS_unplSign 1;
BA_ "GenSigSendType" SG_ 919 FGR_RHS_unplSign 0;
BA_ "GenSigStartValue" SG_ 919 FGR_RHS_unplSign 1;
BA_ "GenSigSendType" SG_ 919 FGR_LIN_Def 0;
BA_ "Fehlerwert" SG_ 919 FGR_LIN_Def 1;
BA_ "GenSigSendType" SG_ 919 FGR_LIN_Timeout 0;
BA_ "Fehlerwert" SG_ 919 FGR_LIN_Timeout 1;
BA_ "GenSigSendType" SG_ 919 FGR_RLIN_Def 0;
BA_ "GenSigSendType" SG_ 919 FGR_RLIN_Timeout 0;
BA_ "GenSigSendType" SG_ 272 SOG_SollPos_L 0;
BA_ "GenSigStartValue" SG_ 272 SOG_SollPos_L 4094;
BA_ "Fehlerwert" SG_ 272 SOG_SollPos_L 4095;
BA_ "GenSigSendType" SG_ 272 SOG_MXB_Aufblenden 0;
BA_ "GenSigSendType" SG_ 272 SOG_MXB_Aufbl_Schaltart 0;
BA_ "GenSigSendType" SG_ 272 SOG_Mali_Freigabe_re 0;
BA_ "GenSigSendType" SG_ 272 SOG_Mali_Freigabe_li 0;
BA_ "GenSigSendType" SG_ 272 SOG_SollPos_R 0;
BA_ "GenSigStartValue" SG_ 272 SOG_SollPos_R 4094;
BA_ "Fehlerwert" SG_ 272 SOG_SollPos_R 4095;
BA_ "GenSigSendType" SG_ 272 SOG_FehlPos_L 0;
BA_ "GenSigSendType" SG_ 272 SOG_FehlPos_R 0;
BA_ "GenSigSendType" SG_ 272 SOG_RefLauf_L 0;
BA_ "GenSigSendType" SG_ 272 SOG_RefLauf_R 0;
BA_ "GenSigSendType" SG_ 272 SOG_StGlTest_L 0;
BA_ "GenSigSendType" SG_ 272 SOG_StGlTest_R 0;
BA_ "GenSigSendType" SG_ 272 SOG_Verkehrsrichtung 0;
BA_ "GenSigSendType" SG_ 272 SOG_XenonLeistung_L 0;
BA_ "GenSigStartValue" SG_ 272 SOG_XenonLeistung_L 254;
BA_ "Fehlerwert" SG_ 272 SOG_XenonLeistung_L 255;
BA_ "GenSigSendType" SG_ 272 SOG_XenonLeistung_L_Schaltart 0;
BA_ "GenSigSendType" SG_ 272 SOG_XenonLeistung_R 0;
BA_ "GenSigStartValue" SG_ 272 SOG_XenonLeistung_R 254;
BA_ "Fehlerwert" SG_ 272 SOG_XenonLeistung_R 255;
BA_ "GenSigSendType" SG_ 272 SOG_XenonLeistung_R_Schaltart 0;
BA_ "GenSigSendType" SG_ 407 SGL_IstPos 0;
BA_ "GenSigStartValue" SG_ 407 SGL_IstPos 4094;
BA_ "Fehlerwert" SG_ 407 SGL_IstPos 4095;
BA_ "GenSigSendType" SG_ 407 SGL_StaVerst 0;
BA_ "GenSigSendType" SG_ 407 SGL_StaFehPos 0;
BA_ "GenSigSendType" SG_ 407 SGL_StaReflauf 0;
BA_ "GenSigSendType" SG_ 407 SGL_StaStGlTst 0;
BA_ "GenSigSendType" SG_ 407 SGL_StagLWElMod 0;
BA_ "GenSigSendType" SG_ 407 SGL_StagLWVerkehr 0;
BA_ "GenSigSendType" SG_ 407 SGL_StagLWFernlicht 0;
BA_ "GenSigSendType" SG_ 407 SGL_XenonLeistung 0;
BA_ "GenSigStartValue" SG_ 407 SGL_XenonLeistung 254;
BA_ "Fehlerwert" SG_ 407 SGL_XenonLeistung 255;
BA_ "GenSigSendType" SG_ 409 SGR_IstPos 0;
BA_ "GenSigStartValue" SG_ 409 SGR_IstPos 4094;
BA_ "Fehlerwert" SG_ 409 SGR_IstPos 4095;
BA_ "GenSigSendType" SG_ 409 SGR_StaVerst 0;
BA_ "GenSigSendType" SG_ 409 SGR_StaFehPos 0;
BA_ "GenSigSendType" SG_ 409 SGR_StaReflauf 0;
BA_ "GenSigSendType" SG_ 409 SGR_StaStGlTst 0;
BA_ "GenSigSendType" SG_ 409 SGR_StagLWElMod 0;
BA_ "GenSigSendType" SG_ 409 SGR_StagLWVerkehr 0;
BA_ "GenSigSendType" SG_ 409 SGR_StagLWFernlicht 0;
BA_ "GenSigSendType" SG_ 409 SGR_XenonLeistung 0;
BA_ "GenSigStartValue" SG_ 409 SGR_XenonLeistung 254;
BA_ "Fehlerwert" SG_ 409 SGR_XenonLeistung 255;
BA_ "GenSigSendType" SG_ 1792 ISO_ALL_01_Req_Data 3;
BA_ "GenSigFuncType" SG_ 1792 ISO_ALL_01_Req_Data 9;
BA_ "GenSigSendType" SG_ 2549874818 ISO_LCM_L_Req_Data 3;
BA_ "GenSigFuncType" SG_ 2549874818 ISO_LCM_L_Req_Data 9;
BA_ "GenSigSendType" SG_ 2550005890 ISO_LCM_L_Resp_Data 3;
BA_ "GenSigFuncType" SG_ 2550005890 ISO_LCM_L_Resp_Data 9;
BA_ "GenSigSendType" SG_ 2549874819 ISO_LCM_R_Req_Data 3;
BA_ "GenSigFuncType" SG_ 2549874819 ISO_LCM_R_Req_Data 9;
BA_ "GenSigSendType" SG_ 2550005891 ISO_LCM_R_Resp_Data 3;
BA_ "GenSigFuncType" SG_ 2550005891 ISO_LCM_R_Resp_Data 9;
BA_ "GenSigSendType" SG_ 2549874838 ISO_LED_LM_L_Req_Data 3;
BA_ "GenSigFuncType" SG_ 2549874838 ISO_LED_LM_L_Req_Data 9;
BA_ "GenSigSendType" SG_ 2550005910 ISO_LED_LM_L_Resp_Data 3;
BA_ "GenSigFuncType" SG_ 2550005910 ISO_LED_LM_L_Resp_Data 9;
BA_ "GenSigSendType" SG_ 2549874839 ISO_LED_LM_R_Req_Data 3;
BA_ "GenSigFuncType" SG_ 2549874839 ISO_LED_LM_R_Req_Data 9;
BA_ "GenSigSendType" SG_ 2550005911 ISO_LED_LM_R_Resp_Data 3;
BA_ "GenSigFuncType" SG_ 2550005911 ISO_LED_LM_R_Resp_Data 9;
BA_ "GenSigSendType" SG_ 791 Kamera_FDD_Obj01_ID 0;
BA_ "GenSigStartValue" SG_ 791 Kamera_FDD_Obj01_ID 254;
BA_ "GenSigSendType" SG_ 791 Kamera_FDD_Obj01_Entf_Nah 0;
BA_ "GenSigSendType" SG_ 791 Kamera_FDD_Obj01_Typ 0;
BA_ "GenSigStartValue" SG_ 791 Kamera_FDD_Obj01_Typ 14;
BA_ "GenSigSendType" SG_ 791 Kamera_FDD_Obj01_horizPos 0;
BA_ "GenSigStartValue" SG_ 791 Kamera_FDD_Obj01_horizPos 1022;
BA_ "GenSigSendType" SG_ 791 Kamera_FDD_Obj01_MehrAlsAchtObj 0;
BA_ "GenSigStartValue" SG_ 791 Kamera_FDD_Obj01_MehrAlsAchtObj 2;
BA_ "GenSigSendType" SG_ 791 Kamera_FDD_Obj01_Ersatzw 0;
BA_ "GenSigStartValue" SG_ 791 Kamera_FDD_Obj01_Ersatzw 2;
BA_ "GenSigSendType" SG_ 791 Kamera_FDD_Obj01_horizDim 0;
BA_ "GenSigStartValue" SG_ 791 Kamera_FDD_Obj01_horizDim 1022;
BA_ "GenSigSendType" SG_ 791 Kamera_FDD_Obj01_vertPos 0;
BA_ "GenSigStartValue" SG_ 791 Kamera_FDD_Obj01_vertPos 1022;
BA_ "GenSigSendType" SG_ 791 Kamera_FDD_Obj01_horizGuete_li 0;
BA_ "GenSigSendType" SG_ 791 Kamera_FDD_Obj01_horizGuete_re 0;
BA_ "GenSigSendType" SG_ 791 Kamera_FDD_Obj01_Entfernung 0;
BA_ "GenSigStartValue" SG_ 791 Kamera_FDD_Obj01_Entfernung 14;
BA_ "GenSigSendType" SG_ 791 Kamera_FDD_Obj01_Objguete 0;
BA_ "GenSigSendType" SG_ 799 Kamera_FDD_Obj02_ID 0;
BA_ "GenSigStartValue" SG_ 799 Kamera_FDD_Obj02_ID 254;
BA_ "GenSigSendType" SG_ 799 Kamera_FDD_Obj02_Entf_Nah 0;
BA_ "GenSigSendType" SG_ 799 Kamera_FDD_Obj02_Typ 0;
BA_ "GenSigStartValue" SG_ 799 Kamera_FDD_Obj02_Typ 14;
BA_ "GenSigSendType" SG_ 799 Kamera_FDD_Obj02_horizPos 0;
BA_ "GenSigStartValue" SG_ 799 Kamera_FDD_Obj02_horizPos 1022;
BA_ "GenSigSendType" SG_ 799 Kamera_FDD_Obj02_Ersatzw 0;
BA_ "GenSigStartValue" SG_ 799 Kamera_FDD_Obj02_Ersatzw 2;
BA_ "GenSigSendType" SG_ 799 Kamera_FDD_Obj02_horizDim 0;
BA_ "GenSigStartValue" SG_ 799 Kamera_FDD_Obj02_horizDim 1022;
BA_ "GenSigSendType" SG_ 799 Kamera_FDD_Obj02_vertPos 0;
BA_ "GenSigStartValue" SG_ 799 Kamera_FDD_Obj02_vertPos 1022;
BA_ "GenSigSendType" SG_ 799 Kamera_FDD_Obj02_horizGuete_li 0;
BA_ "GenSigSendType" SG_ 799 Kamera_FDD_Obj02_horizGuete_re 0;
BA_ "GenSigSendType" SG_ 799 Kamera_FDD_Obj02_Entfernung 0;
BA_ "GenSigStartValue" SG_ 799 Kamera_FDD_Obj02_Entfernung 14;
BA_ "GenSigSendType" SG_ 799 Kamera_FDD_Obj02_Objguete 0;
BA_ "GenSigSendType" SG_ 838 Kamera_FDD_Obj03_ID 0;
BA_ "GenSigStartValue" SG_ 838 Kamera_FDD_Obj03_ID 254;
BA_ "GenSigSendType" SG_ 838 Kamera_FDD_Obj03_Entf_Nah 0;
BA_ "GenSigSendType" SG_ 838 Kamera_FDD_Obj03_Typ 0;
BA_ "GenSigStartValue" SG_ 838 Kamera_FDD_Obj03_Typ 14;
BA_ "GenSigSendType" SG_ 838 Kamera_FDD_Obj03_horizPos 0;
BA_ "GenSigStartValue" SG_ 838 Kamera_FDD_Obj03_horizPos 1022;
BA_ "GenSigSendType" SG_ 838 Kamera_FDD_Obj03_Ersatzw 0;
BA_ "GenSigStartValue" SG_ 838 Kamera_FDD_Obj03_Ersatzw 2;
BA_ "GenSigSendType" SG_ 838 Kamera_FDD_Obj03_horizDim 0;
BA_ "GenSigStartValue" SG_ 838 Kamera_FDD_Obj03_horizDim 1022;
BA_ "GenSigSendType" SG_ 838 Kamera_FDD_Obj03_vertPos 0;
BA_ "GenSigStartValue" SG_ 838 Kamera_FDD_Obj03_vertPos 1022;
BA_ "GenSigSendType" SG_ 838 Kamera_FDD_Obj03_horizGuete_li 0;
BA_ "GenSigSendType" SG_ 838 Kamera_FDD_Obj03_horizGuete_re 0;
BA_ "GenSigSendType" SG_ 838 Kamera_FDD_Obj03_Entfernung 0;
BA_ "GenSigStartValue" SG_ 838 Kamera_FDD_Obj03_Entfernung 14;
BA_ "GenSigSendType" SG_ 838 Kamera_FDD_Obj03_Objguete 0;
BA_ "GenSigSendType" SG_ 839 Kamera_FDD_Obj04_ID 0;
BA_ "GenSigStartValue" SG_ 839 Kamera_FDD_Obj04_ID 254;
BA_ "GenSigSendType" SG_ 839 Kamera_FDD_Obj04_Entf_Nah 0;
BA_ "GenSigSendType" SG_ 839 Kamera_FDD_Obj04_Typ 0;
BA_ "GenSigStartValue" SG_ 839 Kamera_FDD_Obj04_Typ 14;
BA_ "GenSigSendType" SG_ 839 Kamera_FDD_Obj04_horizPos 0;
BA_ "GenSigStartValue" SG_ 839 Kamera_FDD_Obj04_horizPos 1022;
BA_ "GenSigSendType" SG_ 839 Kamera_FDD_Obj04_Ersatzw 0;
BA_ "GenSigStartValue" SG_ 839 Kamera_FDD_Obj04_Ersatzw 2;
BA_ "GenSigSendType" SG_ 839 Kamera_FDD_Obj04_horizDim 0;
BA_ "GenSigStartValue" SG_ 839 Kamera_FDD_Obj04_horizDim 1022;
BA_ "GenSigSendType" SG_ 839 Kamera_FDD_Obj04_vertPos 0;
BA_ "GenSigStartValue" SG_ 839 Kamera_FDD_Obj04_vertPos 1022;
BA_ "GenSigSendType" SG_ 839 Kamera_FDD_Obj04_horizGuete_li 0;
BA_ "GenSigSendType" SG_ 839 Kamera_FDD_Obj04_horizGuete_re 0;
BA_ "GenSigSendType" SG_ 839 Kamera_FDD_Obj04_Entfernung 0;
BA_ "GenSigStartValue" SG_ 839 Kamera_FDD_Obj04_Entfernung 14;
BA_ "GenSigSendType" SG_ 839 Kamera_FDD_Obj04_Objguete 0;
BA_ "GenSigSendType" SG_ 840 Kamera_FDD_Obj05_ID 0;
BA_ "GenSigStartValue" SG_ 840 Kamera_FDD_Obj05_ID 254;
BA_ "GenSigSendType" SG_ 840 Kamera_FDD_Obj05_Entf_Nah 0;
BA_ "GenSigSendType" SG_ 840 Kamera_FDD_Obj05_Typ 0;
BA_ "GenSigStartValue" SG_ 840 Kamera_FDD_Obj05_Typ 14;
BA_ "GenSigSendType" SG_ 840 Kamera_FDD_Obj05_horizPos 0;
BA_ "GenSigStartValue" SG_ 840 Kamera_FDD_Obj05_horizPos 1022;
BA_ "GenSigSendType" SG_ 840 Kamera_FDD_Obj05_Ersatzw 0;
BA_ "GenSigStartValue" SG_ 840 Kamera_FDD_Obj05_Ersatzw 2;
BA_ "GenSigSendType" SG_ 840 Kamera_FDD_Obj05_horizDim 0;
BA_ "GenSigStartValue" SG_ 840 Kamera_FDD_Obj05_horizDim 1022;
BA_ "GenSigSendType" SG_ 840 Kamera_FDD_Obj05_vertPos 0;
BA_ "GenSigStartValue" SG_ 840 Kamera_FDD_Obj05_vertPos 1022;
BA_ "GenSigSendType" SG_ 840 Kamera_FDD_Obj05_horizGuete_li 0;
BA_ "GenSigSendType" SG_ 840 Kamera_FDD_Obj05_horizGuete_re 0;
BA_ "GenSigSendType" SG_ 840 Kamera_FDD_Obj05_Entfernung 0;
BA_ "GenSigStartValue" SG_ 840 Kamera_FDD_Obj05_Entfernung 14;
BA_ "GenSigSendType" SG_ 840 Kamera_FDD_Obj05_Objguete 0;
BA_ "GenSigSendType" SG_ 841 Kamera_FDD_Obj06_ID 0;
BA_ "GenSigStartValue" SG_ 841 Kamera_FDD_Obj06_ID 254;
BA_ "GenSigSendType" SG_ 841 Kamera_FDD_Obj06_Entf_Nah 0;
BA_ "GenSigSendType" SG_ 841 Kamera_FDD_Obj06_Typ 0;
BA_ "GenSigStartValue" SG_ 841 Kamera_FDD_Obj06_Typ 14;
BA_ "GenSigSendType" SG_ 841 Kamera_FDD_Obj06_horizPos 0;
BA_ "GenSigStartValue" SG_ 841 Kamera_FDD_Obj06_horizPos 1022;
BA_ "GenSigSendType" SG_ 841 Kamera_FDD_Obj06_Ersatzw 0;
BA_ "GenSigStartValue" SG_ 841 Kamera_FDD_Obj06_Ersatzw 2;
BA_ "GenSigSendType" SG_ 841 Kamera_FDD_Obj06_horizDim 0;
BA_ "GenSigStartValue" SG_ 841 Kamera_FDD_Obj06_horizDim 1022;
BA_ "GenSigSendType" SG_ 841 Kamera_FDD_Obj06_vertPos 0;
BA_ "GenSigStartValue" SG_ 841 Kamera_FDD_Obj06_vertPos 1022;
BA_ "GenSigSendType" SG_ 841 Kamera_FDD_Obj06_horizGuete_li 0;
BA_ "GenSigSendType" SG_ 841 Kamera_FDD_Obj06_horizGuete_re 0;
BA_ "GenSigSendType" SG_ 841 Kamera_FDD_Obj06_Entfernung 0;
BA_ "GenSigStartValue" SG_ 841 Kamera_FDD_Obj06_Entfernung 14;
BA_ "GenSigSendType" SG_ 841 Kamera_FDD_Obj06_Objguete 0;
BA_ "GenSigSendType" SG_ 842 Kamera_FDD_Obj07_ID 0;
BA_ "GenSigStartValue" SG_ 842 Kamera_FDD_Obj07_ID 254;
BA_ "GenSigSendType" SG_ 842 Kamera_FDD_Obj07_Entf_Nah 0;
BA_ "GenSigSendType" SG_ 842 Kamera_FDD_Obj07_Typ 0;
BA_ "GenSigStartValue" SG_ 842 Kamera_FDD_Obj07_Typ 14;
BA_ "GenSigSendType" SG_ 842 Kamera_FDD_Obj07_horizPos 0;
BA_ "GenSigStartValue" SG_ 842 Kamera_FDD_Obj07_horizPos 1022;
BA_ "GenSigSendType" SG_ 842 Kamera_FDD_Obj07_Ersatzw 0;
BA_ "GenSigStartValue" SG_ 842 Kamera_FDD_Obj07_Ersatzw 2;
BA_ "GenSigSendType" SG_ 842 Kamera_FDD_Obj07_horizDim 0;
BA_ "GenSigStartValue" SG_ 842 Kamera_FDD_Obj07_horizDim 1022;
BA_ "GenSigSendType" SG_ 842 Kamera_FDD_Obj07_vertPos 0;
BA_ "GenSigStartValue" SG_ 842 Kamera_FDD_Obj07_vertPos 1022;
BA_ "GenSigSendType" SG_ 842 Kamera_FDD_Obj07_horizGuete_li 0;
BA_ "GenSigSendType" SG_ 842 Kamera_FDD_Obj07_horizGuete_re 0;
BA_ "GenSigSendType" SG_ 842 Kamera_FDD_Obj07_Entfernung 0;
BA_ "GenSigStartValue" SG_ 842 Kamera_FDD_Obj07_Entfernung 14;
BA_ "GenSigSendType" SG_ 842 Kamera_FDD_Obj07_Objguete 0;
BA_ "GenSigSendType" SG_ 843 Kamera_FDD_Obj08_ID 0;
BA_ "GenSigStartValue" SG_ 843 Kamera_FDD_Obj08_ID 254;
BA_ "GenSigSendType" SG_ 843 Kamera_FDD_Obj08_Entf_Nah 0;
BA_ "GenSigSendType" SG_ 843 Kamera_FDD_Obj08_Typ 0;
BA_ "GenSigStartValue" SG_ 843 Kamera_FDD_Obj08_Typ 14;
BA_ "GenSigSendType" SG_ 843 Kamera_FDD_Obj08_horizPos 0;
BA_ "GenSigStartValue" SG_ 843 Kamera_FDD_Obj08_horizPos 1022;
BA_ "GenSigSendType" SG_ 843 Kamera_FDD_Obj08_Ersatzw 0;
BA_ "GenSigStartValue" SG_ 843 Kamera_FDD_Obj08_Ersatzw 2;
BA_ "GenSigSendType" SG_ 843 Kamera_FDD_Obj08_horizDim 0;
BA_ "GenSigStartValue" SG_ 843 Kamera_FDD_Obj08_horizDim 1022;
BA_ "GenSigSendType" SG_ 843 Kamera_FDD_Obj08_vertPos 0;
BA_ "GenSigStartValue" SG_ 843 Kamera_FDD_Obj08_vertPos 1022;
BA_ "GenSigSendType" SG_ 843 Kamera_FDD_Obj08_horizGuete_li 0;
BA_ "GenSigSendType" SG_ 843 Kamera_FDD_Obj08_horizGuete_re 0;
BA_ "GenSigSendType" SG_ 843 Kamera_FDD_Obj08_Entfernung 0;
BA_ "GenSigStartValue" SG_ 843 Kamera_FDD_Obj08_Entfernung 14;
BA_ "GenSigSendType" SG_ 843 Kamera_FDD_Obj08_Objguete 0;
BA_ "GenSigSendType" SG_ 792 Kamera_Systemzustand 0;
BA_ "GenSigStartValue" SG_ 792 Kamera_Systemzustand 1;
BA_ "GenSigSendType" SG_ 792 Kamera_FDD_Eigenblend_Guete 0;
BA_ "GenSigStartValue" SG_ 792 Kamera_FDD_Eigenblend_Guete 14;
BA_ "Fehlerwert" SG_ 792 Kamera_FDD_Eigenblend_Guete 15;
BA_ "GenSigSendType" SG_ 792 Kamera_FDD_Eigenblend 0;
BA_ "GenSigSendType" SG_ 792 Kamera_FDD_Strassenbeleuchung 0;
BA_ "GenSigSendType" SG_ 792 Kamera_FDD_Funktionsstatus 0;
BA_ "GenSigStartValue" SG_ 792 Kamera_FDD_Funktionsstatus 6;
BA_ "GenSigSendType" SG_ 792 Kamera_FDD_Anz_Strassenleuchten 0;
BA_ "GenSigStartValue" SG_ 792 Kamera_FDD_Anz_Strassenleuchten 15;
BA_ "GenSigSendType" SG_ 792 Kamera_FDD_Verkehrsrichtung 0;
BA_ "GenSigStartValue" SG_ 792 Kamera_FDD_Verkehrsrichtung 2;
BA_ "GenSigSendType" SG_ 792 Kamera_FSH_aktiv 0;
BA_ "GenSigSendType" SG_ 792 Kamera_KD_Fehler 0;
BA_ "GenSigSendType" SG_ 960 RSt_Fahrerhinweise 3;
BA_ "GenSigSendType" SG_ 960 ZAS_Kl_15 3;
BA_ "NWM-WakeupAllowed" SG_ 960 ZAS_Kl_15 1;
BA_ "GenSigFuncType" SG_ 960 ZAS_Kl_15 6;
BA_ "GenSigSendType" SG_ 960 BCM_Ausparken_Betrieb 3;
BA_ "GenSigSendType" SG_ 2549088386 LCM_L_KompSchutz 0;
BA_ "GenSigSendType" SG_ 2549088386 LCM_L_Abschaltstufe 0;
BA_ "GenSigSendType" SG_ 2549088386 LCM_L_Transport_Mode 0;
BA_ "GenSigSendType" SG_ 2549088386 LCM_L_Nachlauftyp 0;
BA_ "GenSigStartValue" SG_ 2549088386 LCM_L_Nachlauftyp 2;
BA_ "GenSigSendType" SG_ 2549088386 LCM_L_SNI 0;
BA_ "GenSigStartValue" SG_ 2549088386 LCM_L_SNI 130;
BA_ "GenSigSendType" SG_ 2549088386 NM_LCM_L_Wakeup 0;
BA_ "NWM-WakeupAllowed" SG_ 2549088386 NM_LCM_L_Wakeup 1;
BA_ "GenSigSendType" SG_ 2549088386 NM_LCM_L_Lokalaktiv 0;
BA_ "GenSigSendType" SG_ 2549088386 NM_LCM_L_Subsystemaktiv 0;
BA_ "GenSigSendType" SG_ 2549088386 LCM_L_KD_Fehler 0;
BA_ "GenSigSendType" SG_ 2549088387 LCM_R_KompSchutz 0;
BA_ "GenSigSendType" SG_ 2549088387 LCM_R_Abschaltstufe 0;
BA_ "GenSigSendType" SG_ 2549088387 LCM_R_Transport_Mode 0;
BA_ "GenSigSendType" SG_ 2549088387 LCM_R_Nachlauftyp 0;
BA_ "GenSigStartValue" SG_ 2549088387 LCM_R_Nachlauftyp 2;
BA_ "GenSigSendType" SG_ 2549088387 LCM_R_SNI 0;
BA_ "GenSigStartValue" SG_ 2549088387 LCM_R_SNI 131;
BA_ "GenSigSendType" SG_ 2549088387 NM_LCM_R_Wakeup 0;
BA_ "NWM-WakeupAllowed" SG_ 2549088387 NM_LCM_R_Wakeup 1;
BA_ "GenSigSendType" SG_ 2549088387 NM_LCM_R_Lokalaktiv 0;
BA_ "GenSigSendType" SG_ 2549088387 NM_LCM_R_Subsystemaktiv 0;
BA_ "GenSigSendType" SG_ 2549088387 LCM_R_KD_Fehler 0;
BA_ "GenSigSendType" SG_ 2549088406 LED_DK3_L_KompSchutz 0;
BA_ "GenSigSendType" SG_ 2549088406 LED_DK3_L_Abschaltstufe 0;
BA_ "GenSigSendType" SG_ 2549088406 LED_DK3_L_Transport_Mode 0;
BA_ "GenSigSendType" SG_ 2549088406 LED_DK3_L_Nachlauftyp 0;
BA_ "GenSigStartValue" SG_ 2549088406 LED_DK3_L_Nachlauftyp 2;
BA_ "GenSigSendType" SG_ 2549088406 LED_DK3_L_SNI 0;
BA_ "GenSigStartValue" SG_ 2549088406 LED_DK3_L_SNI 150;
BA_ "GenSigSendType" SG_ 2549088406 NM_LED_DK3_L_Wakeup 0;
BA_ "GenSigSendType" SG_ 2549088406 NM_LED_DK3_L_Lokalaktiv 0;
BA_ "GenSigSendType" SG_ 2549088406 LED_DK3_L_KD_Fehler 0;
BA_ "GenSigSendType" SG_ 2549088407 LED_DK3_R_KompSchutz 0;
BA_ "GenSigSendType" SG_ 2549088407 LED_DK3_R_Abschaltstufe 0;
BA_ "GenSigSendType" SG_ 2549088407 LED_DK3_R_Transport_Mode 0;
BA_ "GenSigSendType" SG_ 2549088407 LED_DK3_R_Nachlauftyp 0;
BA_ "GenSigStartValue" SG_ 2549088407 LED_DK3_R_Nachlauftyp 2;
BA_ "GenSigSendType" SG_ 2549088407 LED_DK3_R_SNI 0;
BA_ "GenSigStartValue" SG_ 2549088407 LED_DK3_R_SNI 151;
BA_ "GenSigSendType" SG_ 2549088407 NM_LED_DK3_R_Wakeup 0;
BA_ "GenSigSendType" SG_ 2549088407 NM_LED_DK3_R_Lokalaktiv 0;
BA_ "GenSigSendType" SG_ 2549088407 LED_DK3_R_KD_Fehler 0;
BA_ "GenSigSendType" SG_ 1387 LCM_Feh_L_CRC 0;
BA_ "GenSigFuncType" SG_ 1387 LCM_Feh_L_CRC 2;
BA_ "GenSigSendType" SG_ 1387 LCM_Feh_L_BZ 0;
BA_ "GenSigFuncType" SG_ 1387 LCM_Feh_L_BZ 1;
BA_ "GenSigSendType" SG_ 1387 LCM_TFL_Fehler_L 0;
BA_ "Fehlerwert" SG_ 1387 LCM_TFL_Fehler_L 1;
BA_ "GenSigSendType" SG_ 1387 LCM_Sonstiger_Fehler_L 0;
BA_ "Fehlerwert" SG_ 1387 LCM_Sonstiger_Fehler_L 1;
BA_ "GenSigSendType" SG_ 1387 LCM_SM_Fehler_L 0;
BA_ "Fehlerwert" SG_ 1387 LCM_SM_Fehler_L 1;
BA_ "GenSigSendType" SG_ 1387 LCM_Shutter_Fehler_L 0;
BA_ "Fehlerwert" SG_ 1387 LCM_Shutter_Fehler_L 1;
BA_ "GenSigSendType" SG_ 1387 LCM_PO_Fehler_L 0;
BA_ "Fehlerwert" SG_ 1387 LCM_PO_Fehler_L 1;
BA_ "GenSigSendType" SG_ 1387 LCM_Blinker_Fehler_L 0;
BA_ "Fehlerwert" SG_ 1387 LCM_Blinker_Fehler_L 1;
BA_ "GenSigSendType" SG_ 1387 LCM_LWR_L_allg_Fehler 0;
BA_ "Fehlerwert" SG_ 1387 LCM_LWR_L_allg_Fehler 1;
BA_ "GenSigSendType" SG_ 1387 LCM_LWR_L_defekt_Fehler 0;
BA_ "Fehlerwert" SG_ 1387 LCM_LWR_L_defekt_Fehler 1;
BA_ "GenSigSendType" SG_ 1387 LCM_Datensatz_Fehler_L 0;
BA_ "Fehlerwert" SG_ 1387 LCM_Datensatz_Fehler_L 1;
BA_ "GenSigSendType" SG_ 1387 LCM_DKL_L_defekt_Fehler 0;
BA_ "Fehlerwert" SG_ 1387 LCM_DKL_L_defekt_Fehler 1;
BA_ "GenSigSendType" SG_ 1387 LCM_GLW_L_defekt_Fehler 0;
BA_ "Fehlerwert" SG_ 1387 LCM_GLW_L_defekt_Fehler 1;
BA_ "GenSigSendType" SG_ 1387 LCM_SKL_L_defekt_Fehler 0;
BA_ "Fehlerwert" SG_ 1387 LCM_SKL_L_defekt_Fehler 1;
BA_ "GenSigSendType" SG_ 1388 LCM_Feh_R_CRC 0;
BA_ "GenSigFuncType" SG_ 1388 LCM_Feh_R_CRC 2;
BA_ "GenSigSendType" SG_ 1388 LCM_Feh_R_BZ 0;
BA_ "GenSigFuncType" SG_ 1388 LCM_Feh_R_BZ 1;
BA_ "GenSigSendType" SG_ 1388 LCM_TFL_Fehler_R 0;
BA_ "Fehlerwert" SG_ 1388 LCM_TFL_Fehler_R 1;
BA_ "GenSigSendType" SG_ 1388 LCM_Sonstiger_Fehler_R 0;
BA_ "Fehlerwert" SG_ 1388 LCM_Sonstiger_Fehler_R 1;
BA_ "GenSigSendType" SG_ 1388 LCM_SM_Fehler_R 0;
BA_ "Fehlerwert" SG_ 1388 LCM_SM_Fehler_R 1;
BA_ "GenSigSendType" SG_ 1388 LCM_Shutter_Fehler_R 0;
BA_ "Fehlerwert" SG_ 1388 LCM_Shutter_Fehler_R 1;
BA_ "GenSigSendType" SG_ 1388 LCM_PO_Fehler_R 0;
BA_ "Fehlerwert" SG_ 1388 LCM_PO_Fehler_R 1;
BA_ "GenSigSendType" SG_ 1388 LCM_Blinker_Fehler_R 0;
BA_ "Fehlerwert" SG_ 1388 LCM_Blinker_Fehler_R 1;
BA_ "GenSigSendType" SG_ 1388 LCM_LWR_R_allg_Fehler 0;
BA_ "Fehlerwert" SG_ 1388 LCM_LWR_R_allg_Fehler 1;
BA_ "GenSigSendType" SG_ 1388 LCM_LWR_R_defekt_Fehler 0;
BA_ "Fehlerwert" SG_ 1388 LCM_LWR_R_defekt_Fehler 1;
BA_ "GenSigSendType" SG_ 1388 LCM_Datensatz_Fehler_R 0;
BA_ "Fehlerwert" SG_ 1388 LCM_Datensatz_Fehler_R 1;
BA_ "GenSigSendType" SG_ 1388 LCM_DKL_R_defekt_Fehler 0;
BA_ "Fehlerwert" SG_ 1388 LCM_DKL_R_defekt_Fehler 1;
BA_ "GenSigSendType" SG_ 1388 LCM_GLW_R_defekt_Fehler 0;
BA_ "Fehlerwert" SG_ 1388 LCM_GLW_R_defekt_Fehler 1;
BA_ "GenSigSendType" SG_ 1388 LCM_SKL_R_defekt_Fehler 0;
BA_ "Fehlerwert" SG_ 1388 LCM_SKL_R_defekt_Fehler 1;
BA_ "GenSigSendType" SG_ 403 LCM_Soll_CRC 0;
BA_ "GenSigFuncType" SG_ 403 LCM_Soll_CRC 2;
BA_ "GenSigSendType" SG_ 403 LCM_Soll_BZ 0;
BA_ "GenSigFuncType" SG_ 403 LCM_Soll_BZ 1;
BA_ "GenSigSendType" SG_ 403 LCM_TFL_L_Anf 3;
BA_ "GenSigSendType" SG_ 403 LCM_TFL_R_Anf 3;
BA_ "GenSigSendType" SG_ 403 LCM_Abschaltung_Vbat_L_Anf 3;
BA_ "GenSigSendType" SG_ 403 LCM_Abschaltung_Vbat_R_Anf 3;
BA_ "GenSigSendType" SG_ 403 LCM_Blinker_L_Anf 3;
BA_ "GenSigSendType" SG_ 403 LCM_Blinker_R_Anf 3;
BA_ "GenSigSendType" SG_ 403 LCM_Blinkerzyklus_L 3;
BA_ "GenSigSendType" SG_ 403 LCM_Blinkerzyklus_R 3;
BA_ "GenSigSendType" SG_ 403 LCM_Sh_L_Anf 3;
BA_ "GenSigSendType" SG_ 403 LCM_Sh_R_Anf 3;
BA_ "GenSigSendType" SG_ 403 LCM_SM_L_Anf 3;
BA_ "GenSigSendType" SG_ 403 LCM_SM_R_Anf 3;
BA_ "GenSigSendType" SG_ 403 LCM_univ_1_L_Anf 3;
BA_ "GenSigSendType" SG_ 403 LCM_univ_1_R_Anf 3;
BA_ "GenSigSendType" SG_ 403 LCM_PO_L_Anf 3;
BA_ "GenSigSendType" SG_ 403 LCM_PO_R_Anf 3;
BA_ "GenSigSendType" SG_ 403 LCM_PL_L_Anf 3;
BA_ "GenSigSendType" SG_ 403 LCM_PL_R_Anf 3;
BA_ "GenSigSendType" SG_ 403 LCM_Leistungsreduzierung_Anf 3;
BA_ "GenSigSendType" SG_ 403 LCM_Blinkerwischen_Anf 3;
BA_ "GenSigSendType" SG_ 403 LCM_Animiertes_TFL_Anf 3;
BA_ "GenSigSendType" SG_ 403 LCM_Signaturlicht_Anf 3;
BA_ "GenSigSendType" SG_ 403 LCM_ECE_SAE_Umschaltung_Anf 0;
BA_ "GenSigSendType" SG_ 403 BM_Autobahn 3;
BA_ "GenSigSendType" SG_ 403 BM_ZV_auf 3;
BA_ "GenSigSendType" SG_ 403 BM_ZV_zu 3;
BA_ "GenSigSendType" SG_ 403 BCM1_CH_aktiv 0;
BA_ "NWM-WakeupAllowed" SG_ 403 BCM1_CH_aktiv 1;
BA_ "GenSigSendType" SG_ 403 BCM1_LH_aktiv 0;
BA_ "NWM-WakeupAllowed" SG_ 403 BCM1_LH_aktiv 1;
BA_ "GenSigSendType" SG_ 411 LCM_Sta_L_CRC 0;
BA_ "GenSigFuncType" SG_ 411 LCM_Sta_L_CRC 2;
BA_ "GenSigSendType" SG_ 411 LCM_Sta_L_BZ 0;
BA_ "GenSigFuncType" SG_ 411 LCM_Sta_L_BZ 1;
BA_ "GenSigSendType" SG_ 411 LCM_Ausgangsleistungsred_L_Sta 3;
BA_ "GenSigSendType" SG_ 411 LCM_Abschaltbestaetigung_L 3;
BA_ "Fehlerwert" SG_ 411 LCM_Abschaltbestaetigung_L 3;
BA_ "GenSigSendType" SG_ 411 LCM_Blinker_L_Sta 3;
BA_ "GenSigSendType" SG_ 411 LCM_PL_L_Sta 3;
BA_ "GenSigSendType" SG_ 411 LCM_PO_L_Sta 3;
BA_ "GenSigSendType" SG_ 411 LCM_Sh_L_Sta 3;
BA_ "GenSigSendType" SG_ 411 LCM_SM_L_Sta 3;
BA_ "GenSigSendType" SG_ 411 LCM_TFL_L_Sta 3;
BA_ "GenSigSendType" SG_ 411 LCM_univ_1_L_Sta 3;
BA_ "GenSigSendType" SG_ 413 LCM_Sta_R_CRC 0;
BA_ "GenSigFuncType" SG_ 413 LCM_Sta_R_CRC 2;
BA_ "GenSigSendType" SG_ 413 LCM_Sta_R_BZ 0;
BA_ "GenSigFuncType" SG_ 413 LCM_Sta_R_BZ 1;
BA_ "GenSigSendType" SG_ 413 LCM_Ausgangsleistungsred_R_Sta 3;
BA_ "GenSigSendType" SG_ 413 LCM_Abschaltbestaetigung_R 3;
BA_ "Fehlerwert" SG_ 413 LCM_Abschaltbestaetigung_R 3;
BA_ "GenSigSendType" SG_ 413 LCM_Blinker_R_Sta 3;
BA_ "GenSigSendType" SG_ 413 LCM_PL_R_Sta 3;
BA_ "GenSigSendType" SG_ 413 LCM_PO_R_Sta 3;
BA_ "GenSigSendType" SG_ 413 LCM_Sh_R_Sta 3;
BA_ "GenSigSendType" SG_ 413 LCM_SM_R_Sta 3;
BA_ "GenSigSendType" SG_ 413 LCM_TFL_R_Sta 3;
BA_ "GenSigSendType" SG_ 413 LCM_univ_1_R_Sta 3;
BA_REL_ "GenSigTimeoutTime" BU_SG_REL_ AFS SG_ 919 FGR_Akt_KS_Plus 1000;
BA_REL_ "GenSigTimeoutTime" BU_SG_REL_ BCM1 SG_ 919 FGR_Akt_KS_Plus 1000;
BA_REL_ "GenSigTimeoutTime" BU_SG_REL_ FCM SG_ 919 FGR_Akt_KS_Plus 1000;
BA_REL_ "GenSigTimeoutTime" BU_SG_REL_ AFS SG_ 919 FGR_RAkt_KS_Plus 1000;
BA_REL_ "GenSigTimeoutTime" BU_SG_REL_ BCM1 SG_ 919 FGR_RAkt_KS_Plus 1000;
BA_REL_ "GenSigTimeoutTime" BU_SG_REL_ FCM SG_ 919 FGR_RAkt_KS_Plus 1000;
BA_REL_ "GenSigTimeoutTime" BU_SG_REL_ AFS SG_ 919 FGR_Akt_KS_Gnd 1000;
BA_REL_ "GenSigTimeoutTime" BU_SG_REL_ BCM1 SG_ 919 FGR_Akt_KS_Gnd 1000;
BA_REL_ "GenSigTimeoutTime" BU_SG_REL_ FCM SG_ 919 FGR_Akt_KS_Gnd 1000;
BA_REL_ "GenSigTimeoutTime" BU_SG_REL_ AFS SG_ 919 FGR_RAkt_KS_Gnd 1000;
BA_REL_ "GenSigTimeoutTime" BU_SG_REL_ BCM1 SG_ 919 FGR_RAkt_KS_Gnd 1000;
BA_REL_ "GenSigTimeoutTime" BU_SG_REL_ FCM SG_ 919 FGR_RAkt_KS_Gnd 1000;
BA_REL_ "GenSigTimeoutTime" BU_SG_REL_ AFS SG_ 919 FGR_Akt_OL 1000;
BA_REL_ "GenSigTimeoutTime" BU_SG_REL_ BCM1 SG_ 919 FGR_Akt_OL 1000;
BA_REL_ "GenSigTimeoutTime" BU_SG_REL_ FCM SG_ 919 FGR_Akt_OL 1000;
BA_REL_ "GenSigTimeoutTime" BU_SG_REL_ AFS SG_ 919 FGR_RAkt_OL 1000;
BA_REL_ "GenSigTimeoutTime" BU_SG_REL_ BCM1 SG_ 919 FGR_RAkt_OL 1000;
BA_REL_ "GenSigTimeoutTime" BU_SG_REL_ FCM SG_ 919 FGR_RAkt_OL 1000;
BA_REL_ "GenSigTimeoutTime" BU_SG_REL_ AFS SG_ 919 FGR_Akt_UeSpg 1000;
BA_REL_ "GenSigTimeoutTime" BU_SG_REL_ BCM1 SG_ 919 FGR_Akt_UeSpg 1000;
BA_REL_ "GenSigTimeoutTime" BU_SG_REL_ FCM SG_ 919 FGR_Akt_UeSpg 1000;
BA_REL_ "GenSigTimeoutTime" BU_SG_REL_ AFS SG_ 919 FGR_RAkt_UeSpg 1000;
BA_REL_ "GenSigTimeoutTime" BU_SG_REL_ BCM1 SG_ 919 FGR_RAkt_UeSpg 1000;
BA_REL_ "GenSigTimeoutTime" BU_SG_REL_ FCM SG_ 919 FGR_RAkt_UeSpg 1000;
BA_REL_ "GenSigTimeoutTime" BU_SG_REL_ AFS SG_ 919 FGR_Akt_USpg 1000;
BA_REL_ "GenSigTimeoutTime" BU_SG_REL_ BCM1 SG_ 919 FGR_Akt_USpg 1000;
BA_REL_ "GenSigTimeoutTime" BU_SG_REL_ FCM SG_ 919 FGR_Akt_USpg 1000;
BA_REL_ "GenSigTimeoutTime" BU_SG_REL_ AFS SG_ 919 FGR_RAkt_USpg 1000;
BA_REL_ "GenSigTimeoutTime" BU_SG_REL_ BCM1 SG_ 919 FGR_RAkt_USpg 1000;
BA_REL_ "GenSigTimeoutTime" BU_SG_REL_ FCM SG_ 919 FGR_RAkt_USpg 1000;
BA_REL_ "GenSigTimeoutTime" BU_SG_REL_ AFS SG_ 919 FGR_Akt_UeTemp 1000;
BA_REL_ "GenSigTimeoutTime" BU_SG_REL_ BCM1 SG_ 919 FGR_Akt_UeTemp 1000;
BA_REL_ "GenSigTimeoutTime" BU_SG_REL_ FCM SG_ 919 FGR_Akt_UeTemp 1000;
BA_REL_ "GenSigTimeoutTime" BU_SG_REL_ AFS SG_ 919 FGR_RAkt_UeTemp 1000;
BA_REL_ "GenSigTimeoutTime" BU_SG_REL_ BCM1 SG_ 919 FGR_RAkt_UeTemp 1000;
BA_REL_ "GenSigTimeoutTime" BU_SG_REL_ FCM SG_ 919 FGR_RAkt_UeTemp 1000;
BA_REL_ "GenSigTimeoutTime" BU_SG_REL_ AFS SG_ 919 FGR_Akt_TempPre 1000;
BA_REL_ "GenSigTimeoutTime" BU_SG_REL_ BCM1 SG_ 919 FGR_Akt_TempPre 1000;
BA_REL_ "GenSigTimeoutTime" BU_SG_REL_ FCM SG_ 919 FGR_Akt_TempPre 1000;
BA_REL_ "GenSigTimeoutTime" BU_SG_REL_ AFS SG_ 919 FGR_RAkt_TempPre 1000;
BA_REL_ "GenSigTimeoutTime" BU_SG_REL_ BCM1 SG_ 919 FGR_RAkt_TempPre 1000;
BA_REL_ "GenSigTimeoutTime" BU_SG_REL_ FCM SG_ 919 FGR_RAkt_TempPre 1000;
BA_REL_ "GenSigTimeoutTime" BU_SG_REL_ AFS SG_ 919 FGR_HS_KS_Plus 1000;
BA_REL_ "GenSigTimeoutTime" BU_SG_REL_ BCM1 SG_ 919 FGR_HS_KS_Plus 1000;
BA_REL_ "GenSigTimeoutTime" BU_SG_REL_ FCM SG_ 919 FGR_HS_KS_Plus 1000;
BA_REL_ "GenSigTimeoutTime" BU_SG_REL_ AFS SG_ 919 FGR_RHS_KS_Plus 1000;
BA_REL_ "GenSigTimeoutTime" BU_SG_REL_ BCM1 SG_ 919 FGR_RHS_KS_Plus 1000;
BA_REL_ "GenSigTimeoutTime" BU_SG_REL_ FCM SG_ 919 FGR_RHS_KS_Plus 1000;
BA_REL_ "GenSigTimeoutTime" BU_SG_REL_ AFS SG_ 919 FGR_HS_KS_Gnd 1000;
BA_REL_ "GenSigTimeoutTime" BU_SG_REL_ BCM1 SG_ 919 FGR_HS_KS_Gnd 1000;
BA_REL_ "GenSigTimeoutTime" BU_SG_REL_ FCM SG_ 919 FGR_HS_KS_Gnd 1000;
BA_REL_ "GenSigTimeoutTime" BU_SG_REL_ AFS SG_ 919 FGR_RHS_KS_Gnd 1000;
BA_REL_ "GenSigTimeoutTime" BU_SG_REL_ BCM1 SG_ 919 FGR_RHS_KS_Gnd 1000;
BA_REL_ "GenSigTimeoutTime" BU_SG_REL_ FCM SG_ 919 FGR_RHS_KS_Gnd 1000;
BA_REL_ "GenSigTimeoutTime" BU_SG_REL_ AFS SG_ 919 FGR_HS_unplSign 1000;
BA_REL_ "GenSigTimeoutTime" BU_SG_REL_ BCM1 SG_ 919 FGR_HS_unplSign 1000;
BA_REL_ "GenSigTimeoutTime" BU_SG_REL_ FCM SG_ 919 FGR_HS_unplSign 1000;
BA_REL_ "GenSigTimeoutTime" BU_SG_REL_ AFS SG_ 919 FGR_RHS_unplSign 1000;
BA_REL_ "GenSigTimeoutTime" BU_SG_REL_ BCM1 SG_ 919 FGR_RHS_unplSign 1000;
BA_REL_ "GenSigTimeoutTime" BU_SG_REL_ FCM SG_ 919 FGR_RHS_unplSign 1000;
BA_REL_ "GenSigTimeoutTime" BU_SG_REL_ AFS SG_ 919 FGR_LIN_Def 1000;
BA_REL_ "GenSigTimeoutTime" BU_SG_REL_ BCM1 SG_ 919 FGR_LIN_Def 1000;
BA_REL_ "GenSigTimeoutTime" BU_SG_REL_ FCM SG_ 919 FGR_LIN_Def 1000;
BA_REL_ "GenSigTimeoutTime" BU_SG_REL_ AFS SG_ 919 FGR_LIN_Timeout 1000;
BA_REL_ "GenSigTimeoutTime" BU_SG_REL_ BCM1 SG_ 919 FGR_LIN_Timeout 1000;
BA_REL_ "GenSigTimeoutTime" BU_SG_REL_ FCM SG_ 919 FGR_LIN_Timeout 1000;
BA_REL_ "GenSigTimeoutTime" BU_SG_REL_ AFS SG_ 919 FGR_RLIN_Def 1000;
BA_REL_ "GenSigTimeoutTime" BU_SG_REL_ BCM1 SG_ 919 FGR_RLIN_Def 1000;
BA_REL_ "GenSigTimeoutTime" BU_SG_REL_ FCM SG_ 919 FGR_RLIN_Def 1000;
BA_REL_ "GenSigTimeoutTime" BU_SG_REL_ AFS SG_ 919 FGR_RLIN_Timeout 1000;
BA_REL_ "GenSigTimeoutTime" BU_SG_REL_ BCM1 SG_ 919 FGR_RLIN_Timeout 1000;
BA_REL_ "GenSigTimeoutTime" BU_SG_REL_ FCM SG_ 919 FGR_RLIN_Timeout 1000;
BA_REL_ "GenSigTimeoutTime" BU_SG_REL_ GLW_LMod_L SG_ 272 SOG_SollPos_L 500;
BA_REL_ "GenSigTimeoutTime" BU_SG_REL_ LCM_L SG_ 272 SOG_SollPos_L 500;
BA_REL_ "GenSigTimeoutTime" BU_SG_REL_ LLP_L SG_ 272 SOG_SollPos_L 500;
BA_REL_ "GenSigTimeoutTime" BU_SG_REL_ GLW_LMod_R SG_ 272 SOG_SollPos_R 500;
BA_REL_ "GenSigTimeoutTime" BU_SG_REL_ LCM_R SG_ 272 SOG_SollPos_R 500;
BA_REL_ "GenSigTimeoutTime" BU_SG_REL_ LLP_R SG_ 272 SOG_SollPos_R 500;
BA_REL_ "GenSigTimeoutTime" BU_SG_REL_ GLW_LMod_L SG_ 272 SOG_FehlPos_L 500;
BA_REL_ "GenSigTimeoutTime" BU_SG_REL_ LCM_L SG_ 272 SOG_FehlPos_L 500;
BA_REL_ "GenSigTimeoutTime" BU_SG_REL_ LLP_L SG_ 272 SOG_FehlPos_L 500;
BA_REL_ "GenSigTimeoutTime" BU_SG_REL_ GLW_LMod_R SG_ 272 SOG_FehlPos_R 500;
BA_REL_ "GenSigTimeoutTime" BU_SG_REL_ LCM_R SG_ 272 SOG_FehlPos_R 500;
BA_REL_ "GenSigTimeoutTime" BU_SG_REL_ LLP_R SG_ 272 SOG_FehlPos_R 500;
BA_REL_ "GenSigTimeoutTime" BU_SG_REL_ GLW_LMod_L SG_ 272 SOG_RefLauf_L 500;
BA_REL_ "GenSigTimeoutTime" BU_SG_REL_ LCM_L SG_ 272 SOG_RefLauf_L 500;
BA_REL_ "GenSigTimeoutTime" BU_SG_REL_ LLP_L SG_ 272 SOG_RefLauf_L 500;
BA_REL_ "GenSigTimeoutTime" BU_SG_REL_ GLW_LMod_R SG_ 272 SOG_RefLauf_R 500;
BA_REL_ "GenSigTimeoutTime" BU_SG_REL_ LCM_R SG_ 272 SOG_RefLauf_R 500;
BA_REL_ "GenSigTimeoutTime" BU_SG_REL_ LLP_R SG_ 272 SOG_RefLauf_R 500;
BA_REL_ "GenSigTimeoutTime" BU_SG_REL_ GLW_LMod_L SG_ 272 SOG_StGlTest_L 500;
BA_REL_ "GenSigTimeoutTime" BU_SG_REL_ LCM_L SG_ 272 SOG_StGlTest_L 500;
BA_REL_ "GenSigTimeoutTime" BU_SG_REL_ LLP_L SG_ 272 SOG_StGlTest_L 500;
BA_REL_ "GenSigTimeoutTime" BU_SG_REL_ GLW_LMod_R SG_ 272 SOG_StGlTest_R 500;
BA_REL_ "GenSigTimeoutTime" BU_SG_REL_ LCM_R SG_ 272 SOG_StGlTest_R 500;
BA_REL_ "GenSigTimeoutTime" BU_SG_REL_ LLP_R SG_ 272 SOG_StGlTest_R 500;
BA_REL_ "GenSigTimeoutTime" BU_SG_REL_ GLW_LMod_L SG_ 272 SOG_Verkehrsrichtung 500;
BA_REL_ "GenSigTimeoutTime" BU_SG_REL_ GLW_LMod_R SG_ 272 SOG_Verkehrsrichtung 500;
BA_REL_ "GenSigTimeoutTime" BU_SG_REL_ LCM_L SG_ 272 SOG_Verkehrsrichtung 500;
BA_REL_ "GenSigTimeoutTime" BU_SG_REL_ LCM_R SG_ 272 SOG_Verkehrsrichtung 500;
BA_REL_ "GenSigTimeoutTime" BU_SG_REL_ LLP_L SG_ 272 SOG_Verkehrsrichtung 500;
BA_REL_ "GenSigTimeoutTime" BU_SG_REL_ LLP_R SG_ 272 SOG_Verkehrsrichtung 500;
BA_REL_ "GenSigTimeoutTime" BU_SG_REL_ GLW_LMod_L SG_ 272 SOG_XenonLeistung_L 500;
BA_REL_ "GenSigTimeoutTime" BU_SG_REL_ GLW_LMod_L SG_ 272 SOG_XenonLeistung_L_Schaltart 500;
BA_REL_ "GenSigTimeoutTime" BU_SG_REL_ GLW_LMod_R SG_ 272 SOG_XenonLeistung_R 500;
BA_REL_ "GenSigTimeoutTime" BU_SG_REL_ GLW_LMod_R SG_ 272 SOG_XenonLeistung_R_Schaltart 500;
BA_REL_ "GenSigTimeoutTime" BU_SG_REL_ AFS SG_ 407 SGL_IstPos 500;
BA_REL_ "GenSigTimeoutTime" BU_SG_REL_ BCM1 SG_ 407 SGL_IstPos 500;
BA_REL_ "GenSigTimeoutTime" BU_SG_REL_ FCM SG_ 407 SGL_IstPos 500;
BA_REL_ "GenSigTimeoutTime" BU_SG_REL_ AFS SG_ 407 SGL_StaVerst 500;
BA_REL_ "GenSigTimeoutTime" BU_SG_REL_ BCM1 SG_ 407 SGL_StaVerst 500;
BA_REL_ "GenSigTimeoutTime" BU_SG_REL_ FCM SG_ 407 SGL_StaVerst 500;
BA_REL_ "GenSigTimeoutTime" BU_SG_REL_ AFS SG_ 407 SGL_StaFehPos 500;
BA_REL_ "GenSigTimeoutTime" BU_SG_REL_ BCM1 SG_ 407 SGL_StaFehPos 500;
BA_REL_ "GenSigTimeoutTime" BU_SG_REL_ FCM SG_ 407 SGL_StaFehPos 500;
BA_REL_ "GenSigTimeoutTime" BU_SG_REL_ AFS SG_ 407 SGL_StaReflauf 500;
BA_REL_ "GenSigTimeoutTime" BU_SG_REL_ BCM1 SG_ 407 SGL_StaReflauf 500;
BA_REL_ "GenSigTimeoutTime" BU_SG_REL_ FCM SG_ 407 SGL_StaReflauf 500;
BA_REL_ "GenSigTimeoutTime" BU_SG_REL_ AFS SG_ 407 SGL_StaStGlTst 500;
BA_REL_ "GenSigTimeoutTime" BU_SG_REL_ BCM1 SG_ 407 SGL_StaStGlTst 500;
BA_REL_ "GenSigTimeoutTime" BU_SG_REL_ FCM SG_ 407 SGL_StaStGlTst 500;
BA_REL_ "GenSigTimeoutTime" BU_SG_REL_ AFS SG_ 407 SGL_StagLWElMod 500;
BA_REL_ "GenSigTimeoutTime" BU_SG_REL_ BCM1 SG_ 407 SGL_StagLWElMod 500;
BA_REL_ "GenSigTimeoutTime" BU_SG_REL_ FCM SG_ 407 SGL_StagLWElMod 500;
BA_REL_ "GenSigTimeoutTime" BU_SG_REL_ AFS SG_ 407 SGL_StagLWVerkehr 500;
BA_REL_ "GenSigTimeoutTime" BU_SG_REL_ BCM1 SG_ 407 SGL_StagLWVerkehr 500;
BA_REL_ "GenSigTimeoutTime" BU_SG_REL_ FCM SG_ 407 SGL_StagLWVerkehr 500;
BA_REL_ "GenSigTimeoutTime" BU_SG_REL_ AFS SG_ 407 SGL_StagLWFernlicht 500;
BA_REL_ "GenSigTimeoutTime" BU_SG_REL_ BCM1 SG_ 407 SGL_StagLWFernlicht 500;
BA_REL_ "GenSigTimeoutTime" BU_SG_REL_ FCM SG_ 407 SGL_StagLWFernlicht 500;
BA_REL_ "GenSigTimeoutTime" BU_SG_REL_ AFS SG_ 407 SGL_XenonLeistung 500;
BA_REL_ "GenSigTimeoutTime" BU_SG_REL_ BCM1 SG_ 407 SGL_XenonLeistung 500;
BA_REL_ "GenSigTimeoutTime" BU_SG_REL_ FCM SG_ 407 SGL_XenonLeistung 500;
BA_REL_ "GenSigTimeoutTime" BU_SG_REL_ AFS SG_ 409 SGR_IstPos 500;
BA_REL_ "GenSigTimeoutTime" BU_SG_REL_ BCM1 SG_ 409 SGR_IstPos 500;
BA_REL_ "GenSigTimeoutTime" BU_SG_REL_ FCM SG_ 409 SGR_IstPos 500;
BA_REL_ "GenSigTimeoutTime" BU_SG_REL_ AFS SG_ 409 SGR_StaVerst 500;
BA_REL_ "GenSigTimeoutTime" BU_SG_REL_ BCM1 SG_ 409 SGR_StaVerst 500;
BA_REL_ "GenSigTimeoutTime" BU_SG_REL_ FCM SG_ 409 SGR_StaVerst 500;
BA_REL_ "GenSigTimeoutTime" BU_SG_REL_ AFS SG_ 409 SGR_StaFehPos 500;
BA_REL_ "GenSigTimeoutTime" BU_SG_REL_ BCM1 SG_ 409 SGR_StaFehPos 500;
BA_REL_ "GenSigTimeoutTime" BU_SG_REL_ FCM SG_ 409 SGR_StaFehPos 500;
BA_REL_ "GenSigTimeoutTime" BU_SG_REL_ AFS SG_ 409 SGR_StaReflauf 500;
BA_REL_ "GenSigTimeoutTime" BU_SG_REL_ BCM1 SG_ 409 SGR_StaReflauf 500;
BA_REL_ "GenSigTimeoutTime" BU_SG_REL_ FCM SG_ 409 SGR_StaReflauf 500;
BA_REL_ "GenSigTimeoutTime" BU_SG_REL_ AFS SG_ 409 SGR_StaStGlTst 500;
BA_REL_ "GenSigTimeoutTime" BU_SG_REL_ BCM1 SG_ 409 SGR_StaStGlTst 500;
BA_REL_ "GenSigTimeoutTime" BU_SG_REL_ FCM SG_ 409 SGR_StaStGlTst 500;
BA_REL_ "GenSigTimeoutTime" BU_SG_REL_ AFS SG_ 409 SGR_StagLWElMod 500;
BA_REL_ "GenSigTimeoutTime" BU_SG_REL_ BCM1 SG_ 409 SGR_StagLWElMod 500;
BA_REL_ "GenSigTimeoutTime" BU_SG_REL_ FCM SG_ 409 SGR_StagLWElMod 500;
BA_REL_ "GenSigTimeoutTime" BU_SG_REL_ AFS SG_ 409 SGR_StagLWVerkehr 500;
BA_REL_ "GenSigTimeoutTime" BU_SG_REL_ BCM1 SG_ 409 SGR_StagLWVerkehr 500;
BA_REL_ "GenSigTimeoutTime" BU_SG_REL_ FCM SG_ 409 SGR_StagLWVerkehr 500;
BA_REL_ "GenSigTimeoutTime" BU_SG_REL_ AFS SG_ 409 SGR_StagLWFernlicht 500;
BA_REL_ "GenSigTimeoutTime" BU_SG_REL_ BCM1 SG_ 409 SGR_StagLWFernlicht 500;
BA_REL_ "GenSigTimeoutTime" BU_SG_REL_ FCM SG_ 409 SGR_StagLWFernlicht 500;
BA_REL_ "GenSigTimeoutTime" BU_SG_REL_ AFS SG_ 409 SGR_XenonLeistung 500;
BA_REL_ "GenSigTimeoutTime" BU_SG_REL_ BCM1 SG_ 409 SGR_XenonLeistung 500;
BA_REL_ "GenSigTimeoutTime" BU_SG_REL_ FCM SG_ 409 SGR_XenonLeistung 500;
BA_REL_ "GenSigTimeoutTime" BU_SG_REL_ BCM1 SG_ 791 Kamera_FDD_Obj01_ID 500;
BA_REL_ "GenSigTimeoutTime" BU_SG_REL_ BCM1 SG_ 791 Kamera_FDD_Obj01_Entf_Nah 500;
BA_REL_ "GenSigTimeoutTime" BU_SG_REL_ BCM1 SG_ 791 Kamera_FDD_Obj01_Typ 500;
BA_REL_ "GenSigTimeoutTime" BU_SG_REL_ BCM1 SG_ 791 Kamera_FDD_Obj01_horizPos 500;
BA_REL_ "GenSigTimeoutTime" BU_SG_REL_ BCM1 SG_ 791 Kamera_FDD_Obj01_MehrAlsAchtObj 500;
BA_REL_ "GenSigTimeoutTime" BU_SG_REL_ BCM1 SG_ 791 Kamera_FDD_Obj01_Ersatzw 500;
BA_REL_ "GenSigTimeoutTime" BU_SG_REL_ BCM1 SG_ 791 Kamera_FDD_Obj01_horizDim 500;
BA_REL_ "GenSigTimeoutTime" BU_SG_REL_ BCM1 SG_ 791 Kamera_FDD_Obj01_vertPos 500;
BA_REL_ "GenSigTimeoutTime" BU_SG_REL_ BCM1 SG_ 791 Kamera_FDD_Obj01_horizGuete_li 500;
BA_REL_ "GenSigTimeoutTime" BU_SG_REL_ BCM1 SG_ 791 Kamera_FDD_Obj01_horizGuete_re 500;
BA_REL_ "GenSigTimeoutTime" BU_SG_REL_ BCM1 SG_ 791 Kamera_FDD_Obj01_Entfernung 500;
BA_REL_ "GenSigTimeoutTime" BU_SG_REL_ BCM1 SG_ 791 Kamera_FDD_Obj01_Objguete 500;
BA_REL_ "GenSigTimeoutTime" BU_SG_REL_ BCM1 SG_ 799 Kamera_FDD_Obj02_ID 500;
BA_REL_ "GenSigTimeoutTime" BU_SG_REL_ BCM1 SG_ 799 Kamera_FDD_Obj02_Entf_Nah 500;
BA_REL_ "GenSigTimeoutTime" BU_SG_REL_ BCM1 SG_ 799 Kamera_FDD_Obj02_Typ 500;
BA_REL_ "GenSigTimeoutTime" BU_SG_REL_ BCM1 SG_ 799 Kamera_FDD_Obj02_horizPos 500;
BA_REL_ "GenSigTimeoutTime" BU_SG_REL_ BCM1 SG_ 799 Kamera_FDD_Obj02_Ersatzw 500;
BA_REL_ "GenSigTimeoutTime" BU_SG_REL_ BCM1 SG_ 799 Kamera_FDD_Obj02_horizDim 500;
BA_REL_ "GenSigTimeoutTime" BU_SG_REL_ BCM1 SG_ 799 Kamera_FDD_Obj02_vertPos 500;
BA_REL_ "GenSigTimeoutTime" BU_SG_REL_ BCM1 SG_ 799 Kamera_FDD_Obj02_horizGuete_li 500;
BA_REL_ "GenSigTimeoutTime" BU_SG_REL_ BCM1 SG_ 799 Kamera_FDD_Obj02_horizGuete_re 500;
BA_REL_ "GenSigTimeoutTime" BU_SG_REL_ BCM1 SG_ 799 Kamera_FDD_Obj02_Entfernung 500;
BA_REL_ "GenSigTimeoutTime" BU_SG_REL_ BCM1 SG_ 799 Kamera_FDD_Obj02_Objguete 500;
BA_REL_ "GenSigTimeoutTime" BU_SG_REL_ BCM1 SG_ 838 Kamera_FDD_Obj03_ID 500;
BA_REL_ "GenSigTimeoutTime" BU_SG_REL_ BCM1 SG_ 838 Kamera_FDD_Obj03_Entf_Nah 500;
BA_REL_ "GenSigTimeoutTime" BU_SG_REL_ BCM1 SG_ 838 Kamera_FDD_Obj03_Typ 500;
BA_REL_ "GenSigTimeoutTime" BU_SG_REL_ BCM1 SG_ 838 Kamera_FDD_Obj03_horizPos 500;
BA_REL_ "GenSigTimeoutTime" BU_SG_REL_ BCM1 SG_ 838 Kamera_FDD_Obj03_Ersatzw 500;
BA_REL_ "GenSigTimeoutTime" BU_SG_REL_ BCM1 SG_ 838 Kamera_FDD_Obj03_horizDim 500;
BA_REL_ "GenSigTimeoutTime" BU_SG_REL_ BCM1 SG_ 838 Kamera_FDD_Obj03_vertPos 500;
BA_REL_ "GenSigTimeoutTime" BU_SG_REL_ BCM1 SG_ 838 Kamera_FDD_Obj03_horizGuete_li 500;
BA_REL_ "GenSigTimeoutTime" BU_SG_REL_ BCM1 SG_ 838 Kamera_FDD_Obj03_horizGuete_re 500;
BA_REL_ "GenSigTimeoutTime" BU_SG_REL_ BCM1 SG_ 838 Kamera_FDD_Obj03_Entfernung 500;
BA_REL_ "GenSigTimeoutTime" BU_SG_REL_ BCM1 SG_ 838 Kamera_FDD_Obj03_Objguete 500;
BA_REL_ "GenSigTimeoutTime" BU_SG_REL_ BCM1 SG_ 839 Kamera_FDD_Obj04_ID 500;
BA_REL_ "GenSigTimeoutTime" BU_SG_REL_ BCM1 SG_ 839 Kamera_FDD_Obj04_Entf_Nah 500;
BA_REL_ "GenSigTimeoutTime" BU_SG_REL_ BCM1 SG_ 839 Kamera_FDD_Obj04_Typ 500;
BA_REL_ "GenSigTimeoutTime" BU_SG_REL_ BCM1 SG_ 839 Kamera_FDD_Obj04_horizPos 500;
BA_REL_ "GenSigTimeoutTime" BU_SG_REL_ BCM1 SG_ 839 Kamera_FDD_Obj04_Ersatzw 500;
BA_REL_ "GenSigTimeoutTime" BU_SG_REL_ BCM1 SG_ 839 Kamera_FDD_Obj04_horizDim 500;
BA_REL_ "GenSigTimeoutTime" BU_SG_REL_ BCM1 SG_ 839 Kamera_FDD_Obj04_vertPos 500;
BA_REL_ "GenSigTimeoutTime" BU_SG_REL_ BCM1 SG_ 839 Kamera_FDD_Obj04_horizGuete_li 500;
BA_REL_ "GenSigTimeoutTime" BU_SG_REL_ BCM1 SG_ 839 Kamera_FDD_Obj04_horizGuete_re 500;
BA_REL_ "GenSigTimeoutTime" BU_SG_REL_ BCM1 SG_ 839 Kamera_FDD_Obj04_Entfernung 500;
BA_REL_ "GenSigTimeoutTime" BU_SG_REL_ BCM1 SG_ 839 Kamera_FDD_Obj04_Objguete 500;
BA_REL_ "GenSigTimeoutTime" BU_SG_REL_ BCM1 SG_ 840 Kamera_FDD_Obj05_ID 500;
BA_REL_ "GenSigTimeoutTime" BU_SG_REL_ BCM1 SG_ 840 Kamera_FDD_Obj05_Entf_Nah 500;
BA_REL_ "GenSigTimeoutTime" BU_SG_REL_ BCM1 SG_ 840 Kamera_FDD_Obj05_Typ 500;
BA_REL_ "GenSigTimeoutTime" BU_SG_REL_ BCM1 SG_ 840 Kamera_FDD_Obj05_horizPos 500;
BA_REL_ "GenSigTimeoutTime" BU_SG_REL_ BCM1 SG_ 840 Kamera_FDD_Obj05_Ersatzw 500;
BA_REL_ "GenSigTimeoutTime" BU_SG_REL_ BCM1 SG_ 840 Kamera_FDD_Obj05_horizDim 500;
BA_REL_ "GenSigTimeoutTime" BU_SG_REL_ BCM1 SG_ 840 Kamera_FDD_Obj05_vertPos 500;
BA_REL_ "GenSigTimeoutTime" BU_SG_REL_ BCM1 SG_ 840 Kamera_FDD_Obj05_horizGuete_li 500;
BA_REL_ "GenSigTimeoutTime" BU_SG_REL_ BCM1 SG_ 840 Kamera_FDD_Obj05_horizGuete_re 500;
BA_REL_ "GenSigTimeoutTime" BU_SG_REL_ BCM1 SG_ 840 Kamera_FDD_Obj05_Entfernung 500;
BA_REL_ "GenSigTimeoutTime" BU_SG_REL_ BCM1 SG_ 840 Kamera_FDD_Obj05_Objguete 500;
BA_REL_ "GenSigTimeoutTime" BU_SG_REL_ BCM1 SG_ 841 Kamera_FDD_Obj06_ID 500;
BA_REL_ "GenSigTimeoutTime" BU_SG_REL_ BCM1 SG_ 841 Kamera_FDD_Obj06_Entf_Nah 500;
BA_REL_ "GenSigTimeoutTime" BU_SG_REL_ BCM1 SG_ 841 Kamera_FDD_Obj06_Typ 500;
BA_REL_ "GenSigTimeoutTime" BU_SG_REL_ BCM1 SG_ 841 Kamera_FDD_Obj06_horizPos 500;
BA_REL_ "GenSigTimeoutTime" BU_SG_REL_ BCM1 SG_ 841 Kamera_FDD_Obj06_Ersatzw 500;
BA_REL_ "GenSigTimeoutTime" BU_SG_REL_ BCM1 SG_ 841 Kamera_FDD_Obj06_horizDim 500;
BA_REL_ "GenSigTimeoutTime" BU_SG_REL_ BCM1 SG_ 841 Kamera_FDD_Obj06_vertPos 500;
BA_REL_ "GenSigTimeoutTime" BU_SG_REL_ BCM1 SG_ 841 Kamera_FDD_Obj06_horizGuete_li 500;
BA_REL_ "GenSigTimeoutTime" BU_SG_REL_ BCM1 SG_ 841 Kamera_FDD_Obj06_horizGuete_re 500;
BA_REL_ "GenSigTimeoutTime" BU_SG_REL_ BCM1 SG_ 841 Kamera_FDD_Obj06_Entfernung 500;
BA_REL_ "GenSigTimeoutTime" BU_SG_REL_ BCM1 SG_ 841 Kamera_FDD_Obj06_Objguete 500;
BA_REL_ "GenSigTimeoutTime" BU_SG_REL_ BCM1 SG_ 842 Kamera_FDD_Obj07_ID 500;
BA_REL_ "GenSigTimeoutTime" BU_SG_REL_ BCM1 SG_ 842 Kamera_FDD_Obj07_Entf_Nah 500;
BA_REL_ "GenSigTimeoutTime" BU_SG_REL_ BCM1 SG_ 842 Kamera_FDD_Obj07_Typ 500;
BA_REL_ "GenSigTimeoutTime" BU_SG_REL_ BCM1 SG_ 842 Kamera_FDD_Obj07_horizPos 500;
BA_REL_ "GenSigTimeoutTime" BU_SG_REL_ BCM1 SG_ 842 Kamera_FDD_Obj07_Ersatzw 500;
BA_REL_ "GenSigTimeoutTime" BU_SG_REL_ BCM1 SG_ 842 Kamera_FDD_Obj07_horizDim 500;
BA_REL_ "GenSigTimeoutTime" BU_SG_REL_ BCM1 SG_ 842 Kamera_FDD_Obj07_vertPos 500;
BA_REL_ "GenSigTimeoutTime" BU_SG_REL_ BCM1 SG_ 842 Kamera_FDD_Obj07_horizGuete_li 500;
BA_REL_ "GenSigTimeoutTime" BU_SG_REL_ BCM1 SG_ 842 Kamera_FDD_Obj07_horizGuete_re 500;
BA_REL_ "GenSigTimeoutTime" BU_SG_REL_ BCM1 SG_ 842 Kamera_FDD_Obj07_Entfernung 500;
BA_REL_ "GenSigTimeoutTime" BU_SG_REL_ BCM1 SG_ 842 Kamera_FDD_Obj07_Objguete 500;
BA_REL_ "GenSigTimeoutTime" BU_SG_REL_ BCM1 SG_ 843 Kamera_FDD_Obj08_ID 500;
BA_REL_ "GenSigTimeoutTime" BU_SG_REL_ BCM1 SG_ 843 Kamera_FDD_Obj08_Entf_Nah 500;
BA_REL_ "GenSigTimeoutTime" BU_SG_REL_ BCM1 SG_ 843 Kamera_FDD_Obj08_Typ 500;
BA_REL_ "GenSigTimeoutTime" BU_SG_REL_ BCM1 SG_ 843 Kamera_FDD_Obj08_horizPos 500;
BA_REL_ "GenSigTimeoutTime" BU_SG_REL_ BCM1 SG_ 843 Kamera_FDD_Obj08_Ersatzw 500;
BA_REL_ "GenSigTimeoutTime" BU_SG_REL_ BCM1 SG_ 843 Kamera_FDD_Obj08_horizDim 500;
BA_REL_ "GenSigTimeoutTime" BU_SG_REL_ BCM1 SG_ 843 Kamera_FDD_Obj08_vertPos 500;
BA_REL_ "GenSigTimeoutTime" BU_SG_REL_ BCM1 SG_ 843 Kamera_FDD_Obj08_horizGuete_li 500;
BA_REL_ "GenSigTimeoutTime" BU_SG_REL_ BCM1 SG_ 843 Kamera_FDD_Obj08_horizGuete_re 500;
BA_REL_ "GenSigTimeoutTime" BU_SG_REL_ BCM1 SG_ 843 Kamera_FDD_Obj08_Entfernung 500;
BA_REL_ "GenSigTimeoutTime" BU_SG_REL_ BCM1 SG_ 843 Kamera_FDD_Obj08_Objguete 500;
BA_REL_ "GenSigTimeoutTime" BU_SG_REL_ BCM1 SG_ 792 Kamera_Systemzustand 800;
BA_REL_ "GenSigTimeoutTime" BU_SG_REL_ BCM1 SG_ 792 Kamera_FDD_Eigenblend_Guete 800;
BA_REL_ "GenSigTimeoutTime" BU_SG_REL_ BCM1 SG_ 792 Kamera_FDD_Eigenblend 800;
BA_REL_ "GenSigTimeoutTime" BU_SG_REL_ BCM1 SG_ 792 Kamera_FDD_Strassenbeleuchung 800;
BA_REL_ "GenSigTimeoutTime" BU_SG_REL_ BCM1 SG_ 792 Kamera_FDD_Funktionsstatus 800;
BA_REL_ "GenSigTimeoutTime" BU_SG_REL_ BCM1 SG_ 792 Kamera_FDD_Anz_Strassenleuchten 800;
BA_REL_ "GenSigTimeoutTime" BU_SG_REL_ BCM1 SG_ 792 Kamera_FDD_Verkehrsrichtung 800;
BA_REL_ "GenSigTimeoutTime" BU_SG_REL_ BCM1 SG_ 792 Kamera_FSH_aktiv 800;
BA_REL_ "GenSigTimeoutTime" BU_SG_REL_ LCM_L SG_ 960 ZAS_Kl_15 1000;
BA_REL_ "GenSigTimeoutTime" BU_SG_REL_ LCM_R SG_ 960 ZAS_Kl_15 1000;
BA_REL_ "GenSigTimeoutTime" BU_SG_REL_ LED_DK3_LM_L SG_ 960 ZAS_Kl_15 1000;
BA_REL_ "GenSigTimeoutTime" BU_SG_REL_ LED_DK3_LM_R SG_ 960 ZAS_Kl_15 1000;
BA_REL_ "GenSigTimeoutTime" BU_SG_REL_ LED_LM_L SG_ 960 ZAS_Kl_15 1000;
BA_REL_ "GenSigTimeoutTime" BU_SG_REL_ LED_LM_R SG_ 960 ZAS_Kl_15 1000;
BA_REL_ "GenSigTimeoutTime" BU_SG_REL_ LLP_L SG_ 960 ZAS_Kl_15 1000;
BA_REL_ "GenSigTimeoutTime" BU_SG_REL_ LLP_R SG_ 960 ZAS_Kl_15 1000;
BA_REL_ "GenSigTimeoutTime" BU_SG_REL_ AFS SG_ 2549088386 LCM_L_KompSchutz 5000;
BA_REL_ "GenSigTimeoutTime" BU_SG_REL_ BCM1 SG_ 2549088386 LCM_L_KompSchutz 5000;
BA_REL_ "GenSigTimeoutTime" BU_SG_REL_ FCM SG_ 2549088386 LCM_L_KompSchutz 5000;
BA_REL_ "GenSigTimeoutTime" BU_SG_REL_ MXB SG_ 2549088386 LCM_L_KompSchutz 5000;
BA_REL_ "GenSigTimeoutTime" BU_SG_REL_ AFS SG_ 2549088386 LCM_L_Abschaltstufe 5000;
BA_REL_ "GenSigTimeoutTime" BU_SG_REL_ BCM1 SG_ 2549088386 LCM_L_Abschaltstufe 5000;
BA_REL_ "GenSigTimeoutTime" BU_SG_REL_ FCM SG_ 2549088386 LCM_L_Abschaltstufe 5000;
BA_REL_ "GenSigTimeoutTime" BU_SG_REL_ MXB SG_ 2549088386 LCM_L_Abschaltstufe 5000;
BA_REL_ "GenSigTimeoutTime" BU_SG_REL_ AFS SG_ 2549088386 LCM_L_Transport_Mode 5000;
BA_REL_ "GenSigTimeoutTime" BU_SG_REL_ BCM1 SG_ 2549088386 LCM_L_Transport_Mode 5000;
BA_REL_ "GenSigTimeoutTime" BU_SG_REL_ FCM SG_ 2549088386 LCM_L_Transport_Mode 5000;
BA_REL_ "GenSigTimeoutTime" BU_SG_REL_ MXB SG_ 2549088386 LCM_L_Transport_Mode 5000;
BA_REL_ "GenSigTimeoutTime" BU_SG_REL_ AFS SG_ 2549088386 LCM_L_Nachlauftyp 5000;
BA_REL_ "GenSigTimeoutTime" BU_SG_REL_ BCM1 SG_ 2549088386 LCM_L_Nachlauftyp 5000;
BA_REL_ "GenSigTimeoutTime" BU_SG_REL_ FCM SG_ 2549088386 LCM_L_Nachlauftyp 5000;
BA_REL_ "GenSigTimeoutTime" BU_SG_REL_ MXB SG_ 2549088386 LCM_L_Nachlauftyp 5000;
BA_REL_ "GenSigTimeoutTime" BU_SG_REL_ AFS SG_ 2549088386 LCM_L_SNI 5000;
BA_REL_ "GenSigTimeoutTime" BU_SG_REL_ BCM1 SG_ 2549088386 LCM_L_SNI 5000;
BA_REL_ "GenSigTimeoutTime" BU_SG_REL_ FCM SG_ 2549088386 LCM_L_SNI 5000;
BA_REL_ "GenSigTimeoutTime" BU_SG_REL_ MXB SG_ 2549088386 LCM_L_SNI 5000;
BA_REL_ "GenSigTimeoutTime" BU_SG_REL_ AFS SG_ 2549088386 NM_LCM_L_Wakeup 5000;
BA_REL_ "GenSigTimeoutTime" BU_SG_REL_ BCM1 SG_ 2549088386 NM_LCM_L_Wakeup 5000;
BA_REL_ "GenSigTimeoutTime" BU_SG_REL_ FCM SG_ 2549088386 NM_LCM_L_Wakeup 5000;
BA_REL_ "GenSigTimeoutTime" BU_SG_REL_ MXB SG_ 2549088386 NM_LCM_L_Wakeup 5000;
BA_REL_ "GenSigTimeoutTime" BU_SG_REL_ AFS SG_ 2549088386 NM_LCM_L_Lokalaktiv 5000;
BA_REL_ "GenSigTimeoutTime" BU_SG_REL_ BCM1 SG_ 2549088386 NM_LCM_L_Lokalaktiv 5000;
BA_REL_ "GenSigTimeoutTime" BU_SG_REL_ FCM SG_ 2549088386 NM_LCM_L_Lokalaktiv 5000;
BA_REL_ "GenSigTimeoutTime" BU_SG_REL_ MXB SG_ 2549088386 NM_LCM_L_Lokalaktiv 5000;
BA_REL_ "GenSigTimeoutTime" BU_SG_REL_ AFS SG_ 2549088386 NM_LCM_L_Subsystemaktiv 5000;
BA_REL_ "GenSigTimeoutTime" BU_SG_REL_ BCM1 SG_ 2549088386 NM_LCM_L_Subsystemaktiv 5000;
BA_REL_ "GenSigTimeoutTime" BU_SG_REL_ FCM SG_ 2549088386 NM_LCM_L_Subsystemaktiv 5000;
BA_REL_ "GenSigTimeoutTime" BU_SG_REL_ MXB SG_ 2549088386 NM_LCM_L_Subsystemaktiv 5000;
BA_REL_ "GenSigTimeoutTime" BU_SG_REL_ AFS SG_ 2549088386 LCM_L_KD_Fehler 5000;
BA_REL_ "GenSigTimeoutTime" BU_SG_REL_ BCM1 SG_ 2549088386 LCM_L_KD_Fehler 5000;
BA_REL_ "GenSigTimeoutTime" BU_SG_REL_ FCM SG_ 2549088386 LCM_L_KD_Fehler 5000;
BA_REL_ "GenSigTimeoutTime" BU_SG_REL_ MXB SG_ 2549088386 LCM_L_KD_Fehler 5000;
BA_REL_ "GenSigTimeoutTime" BU_SG_REL_ AFS SG_ 2549088387 LCM_R_KompSchutz 5000;
BA_REL_ "GenSigTimeoutTime" BU_SG_REL_ BCM1 SG_ 2549088387 LCM_R_KompSchutz 5000;
BA_REL_ "GenSigTimeoutTime" BU_SG_REL_ FCM SG_ 2549088387 LCM_R_KompSchutz 5000;
BA_REL_ "GenSigTimeoutTime" BU_SG_REL_ MXB SG_ 2549088387 LCM_R_KompSchutz 5000;
BA_REL_ "GenSigTimeoutTime" BU_SG_REL_ AFS SG_ 2549088387 LCM_R_Abschaltstufe 5000;
BA_REL_ "GenSigTimeoutTime" BU_SG_REL_ BCM1 SG_ 2549088387 LCM_R_Abschaltstufe 5000;
BA_REL_ "GenSigTimeoutTime" BU_SG_REL_ FCM SG_ 2549088387 LCM_R_Abschaltstufe 5000;
BA_REL_ "GenSigTimeoutTime" BU_SG_REL_ MXB SG_ 2549088387 LCM_R_Abschaltstufe 5000;
BA_REL_ "GenSigTimeoutTime" BU_SG_REL_ AFS SG_ 2549088387 LCM_R_Transport_Mode 5000;
BA_REL_ "GenSigTimeoutTime" BU_SG_REL_ BCM1 SG_ 2549088387 LCM_R_Transport_Mode 5000;
BA_REL_ "GenSigTimeoutTime" BU_SG_REL_ FCM SG_ 2549088387 LCM_R_Transport_Mode 5000;
BA_REL_ "GenSigTimeoutTime" BU_SG_REL_ MXB SG_ 2549088387 LCM_R_Transport_Mode 5000;
BA_REL_ "GenSigTimeoutTime" BU_SG_REL_ AFS SG_ 2549088387 LCM_R_Nachlauftyp 5000;
BA_REL_ "GenSigTimeoutTime" BU_SG_REL_ BCM1 SG_ 2549088387 LCM_R_Nachlauftyp 5000;
BA_REL_ "GenSigTimeoutTime" BU_SG_REL_ FCM SG_ 2549088387 LCM_R_Nachlauftyp 5000;
BA_REL_ "GenSigTimeoutTime" BU_SG_REL_ MXB SG_ 2549088387 LCM_R_Nachlauftyp 5000;
BA_REL_ "GenSigTimeoutTime" BU_SG_REL_ AFS SG_ 2549088387 LCM_R_SNI 5000;
BA_REL_ "GenSigTimeoutTime" BU_SG_REL_ BCM1 SG_ 2549088387 LCM_R_SNI 5000;
BA_REL_ "GenSigTimeoutTime" BU_SG_REL_ FCM SG_ 2549088387 LCM_R_SNI 5000;
BA_REL_ "GenSigTimeoutTime" BU_SG_REL_ MXB SG_ 2549088387 LCM_R_SNI 5000;
BA_REL_ "GenSigTimeoutTime" BU_SG_REL_ AFS SG_ 2549088387 NM_LCM_R_Wakeup 5000;
BA_REL_ "GenSigTimeoutTime" BU_SG_REL_ BCM1 SG_ 2549088387 NM_LCM_R_Wakeup 5000;
BA_REL_ "GenSigTimeoutTime" BU_SG_REL_ FCM SG_ 2549088387 NM_LCM_R_Wakeup 5000;
BA_REL_ "GenSigTimeoutTime" BU_SG_REL_ MXB SG_ 2549088387 NM_LCM_R_Wakeup 5000;
BA_REL_ "GenSigTimeoutTime" BU_SG_REL_ AFS SG_ 2549088387 NM_LCM_R_Lokalaktiv 5000;
BA_REL_ "GenSigTimeoutTime" BU_SG_REL_ BCM1 SG_ 2549088387 NM_LCM_R_Lokalaktiv 5000;
BA_REL_ "GenSigTimeoutTime" BU_SG_REL_ FCM SG_ 2549088387 NM_LCM_R_Lokalaktiv 5000;
BA_REL_ "GenSigTimeoutTime" BU_SG_REL_ MXB SG_ 2549088387 NM_LCM_R_Lokalaktiv 5000;
BA_REL_ "GenSigTimeoutTime" BU_SG_REL_ AFS SG_ 2549088387 NM_LCM_R_Subsystemaktiv 5000;
BA_REL_ "GenSigTimeoutTime" BU_SG_REL_ BCM1 SG_ 2549088387 NM_LCM_R_Subsystemaktiv 5000;
BA_REL_ "GenSigTimeoutTime" BU_SG_REL_ FCM SG_ 2549088387 NM_LCM_R_Subsystemaktiv 5000;
BA_REL_ "GenSigTimeoutTime" BU_SG_REL_ MXB SG_ 2549088387 NM_LCM_R_Subsystemaktiv 5000;
BA_REL_ "GenSigTimeoutTime" BU_SG_REL_ AFS SG_ 2549088387 LCM_R_KD_Fehler 5000;
BA_REL_ "GenSigTimeoutTime" BU_SG_REL_ BCM1 SG_ 2549088387 LCM_R_KD_Fehler 5000;
BA_REL_ "GenSigTimeoutTime" BU_SG_REL_ FCM SG_ 2549088387 LCM_R_KD_Fehler 5000;
BA_REL_ "GenSigTimeoutTime" BU_SG_REL_ MXB SG_ 2549088387 LCM_R_KD_Fehler 5000;
BA_REL_ "GenSigTimeoutTime" BU_SG_REL_ AFS SG_ 2549088406 LED_DK3_L_KompSchutz 5000;
BA_REL_ "GenSigTimeoutTime" BU_SG_REL_ BCM1 SG_ 2549088406 LED_DK3_L_KompSchutz 5000;
BA_REL_ "GenSigTimeoutTime" BU_SG_REL_ FCM SG_ 2549088406 LED_DK3_L_KompSchutz 5000;
BA_REL_ "GenSigTimeoutTime" BU_SG_REL_ MXB SG_ 2549088406 LED_DK3_L_KompSchutz 5000;
BA_REL_ "GenSigTimeoutTime" BU_SG_REL_ AFS SG_ 2549088406 LED_DK3_L_Abschaltstufe 5000;
BA_REL_ "GenSigTimeoutTime" BU_SG_REL_ BCM1 SG_ 2549088406 LED_DK3_L_Abschaltstufe 5000;
BA_REL_ "GenSigTimeoutTime" BU_SG_REL_ FCM SG_ 2549088406 LED_DK3_L_Abschaltstufe 5000;
BA_REL_ "GenSigTimeoutTime" BU_SG_REL_ MXB SG_ 2549088406 LED_DK3_L_Abschaltstufe 5000;
BA_REL_ "GenSigTimeoutTime" BU_SG_REL_ AFS SG_ 2549088406 LED_DK3_L_Transport_Mode 5000;
BA_REL_ "GenSigTimeoutTime" BU_SG_REL_ BCM1 SG_ 2549088406 LED_DK3_L_Transport_Mode 5000;
BA_REL_ "GenSigTimeoutTime" BU_SG_REL_ FCM SG_ 2549088406 LED_DK3_L_Transport_Mode 5000;
BA_REL_ "GenSigTimeoutTime" BU_SG_REL_ MXB SG_ 2549088406 LED_DK3_L_Transport_Mode 5000;
BA_REL_ "GenSigTimeoutTime" BU_SG_REL_ AFS SG_ 2549088406 LED_DK3_L_Nachlauftyp 5000;
BA_REL_ "GenSigTimeoutTime" BU_SG_REL_ BCM1 SG_ 2549088406 LED_DK3_L_Nachlauftyp 5000;
BA_REL_ "GenSigTimeoutTime" BU_SG_REL_ FCM SG_ 2549088406 LED_DK3_L_Nachlauftyp 5000;
BA_REL_ "GenSigTimeoutTime" BU_SG_REL_ MXB SG_ 2549088406 LED_DK3_L_Nachlauftyp 5000;
BA_REL_ "GenSigTimeoutTime" BU_SG_REL_ AFS SG_ 2549088406 LED_DK3_L_SNI 5000;
BA_REL_ "GenSigTimeoutTime" BU_SG_REL_ BCM1 SG_ 2549088406 LED_DK3_L_SNI 5000;
BA_REL_ "GenSigTimeoutTime" BU_SG_REL_ FCM SG_ 2549088406 LED_DK3_L_SNI 5000;
BA_REL_ "GenSigTimeoutTime" BU_SG_REL_ MXB SG_ 2549088406 LED_DK3_L_SNI 5000;
BA_REL_ "GenSigTimeoutTime" BU_SG_REL_ AFS SG_ 2549088406 NM_LED_DK3_L_Wakeup 5000;
BA_REL_ "GenSigTimeoutTime" BU_SG_REL_ BCM1 SG_ 2549088406 NM_LED_DK3_L_Wakeup 5000;
BA_REL_ "GenSigTimeoutTime" BU_SG_REL_ FCM SG_ 2549088406 NM_LED_DK3_L_Wakeup 5000;
BA_REL_ "GenSigTimeoutTime" BU_SG_REL_ MXB SG_ 2549088406 NM_LED_DK3_L_Wakeup 5000;
BA_REL_ "GenSigTimeoutTime" BU_SG_REL_ AFS SG_ 2549088406 NM_LED_DK3_L_Lokalaktiv 5000;
BA_REL_ "GenSigTimeoutTime" BU_SG_REL_ BCM1 SG_ 2549088406 NM_LED_DK3_L_Lokalaktiv 5000;
BA_REL_ "GenSigTimeoutTime" BU_SG_REL_ FCM SG_ 2549088406 NM_LED_DK3_L_Lokalaktiv 5000;
BA_REL_ "GenSigTimeoutTime" BU_SG_REL_ MXB SG_ 2549088406 NM_LED_DK3_L_Lokalaktiv 5000;
BA_REL_ "GenSigTimeoutTime" BU_SG_REL_ AFS SG_ 2549088406 LED_DK3_L_KD_Fehler 5000;
BA_REL_ "GenSigTimeoutTime" BU_SG_REL_ BCM1 SG_ 2549088406 LED_DK3_L_KD_Fehler 5000;
BA_REL_ "GenSigTimeoutTime" BU_SG_REL_ FCM SG_ 2549088406 LED_DK3_L_KD_Fehler 5000;
BA_REL_ "GenSigTimeoutTime" BU_SG_REL_ MXB SG_ 2549088406 LED_DK3_L_KD_Fehler 5000;
BA_REL_ "GenSigTimeoutTime" BU_SG_REL_ AFS SG_ 2549088407 LED_DK3_R_KompSchutz 5000;
BA_REL_ "GenSigTimeoutTime" BU_SG_REL_ BCM1 SG_ 2549088407 LED_DK3_R_KompSchutz 5000;
BA_REL_ "GenSigTimeoutTime" BU_SG_REL_ FCM SG_ 2549088407 LED_DK3_R_KompSchutz 5000;
BA_REL_ "GenSigTimeoutTime" BU_SG_REL_ MXB SG_ 2549088407 LED_DK3_R_KompSchutz 5000;
BA_REL_ "GenSigTimeoutTime" BU_SG_REL_ AFS SG_ 2549088407 LED_DK3_R_Abschaltstufe 5000;
BA_REL_ "GenSigTimeoutTime" BU_SG_REL_ BCM1 SG_ 2549088407 LED_DK3_R_Abschaltstufe 5000;
BA_REL_ "GenSigTimeoutTime" BU_SG_REL_ FCM SG_ 2549088407 LED_DK3_R_Abschaltstufe 5000;
BA_REL_ "GenSigTimeoutTime" BU_SG_REL_ MXB SG_ 2549088407 LED_DK3_R_Abschaltstufe 5000;
BA_REL_ "GenSigTimeoutTime" BU_SG_REL_ AFS SG_ 2549088407 LED_DK3_R_Transport_Mode 5000;
BA_REL_ "GenSigTimeoutTime" BU_SG_REL_ BCM1 SG_ 2549088407 LED_DK3_R_Transport_Mode 5000;
BA_REL_ "GenSigTimeoutTime" BU_SG_REL_ FCM SG_ 2549088407 LED_DK3_R_Transport_Mode 5000;
BA_REL_ "GenSigTimeoutTime" BU_SG_REL_ MXB SG_ 2549088407 LED_DK3_R_Transport_Mode 5000;
BA_REL_ "GenSigTimeoutTime" BU_SG_REL_ AFS SG_ 2549088407 LED_DK3_R_Nachlauftyp 5000;
BA_REL_ "GenSigTimeoutTime" BU_SG_REL_ BCM1 SG_ 2549088407 LED_DK3_R_Nachlauftyp 5000;
BA_REL_ "GenSigTimeoutTime" BU_SG_REL_ FCM SG_ 2549088407 LED_DK3_R_Nachlauftyp 5000;
BA_REL_ "GenSigTimeoutTime" BU_SG_REL_ MXB SG_ 2549088407 LED_DK3_R_Nachlauftyp 5000;
BA_REL_ "GenSigTimeoutTime" BU_SG_REL_ AFS SG_ 2549088407 LED_DK3_R_SNI 5000;
BA_REL_ "GenSigTimeoutTime" BU_SG_REL_ BCM1 SG_ 2549088407 LED_DK3_R_SNI 5000;
BA_REL_ "GenSigTimeoutTime" BU_SG_REL_ FCM SG_ 2549088407 LED_DK3_R_SNI 5000;
BA_REL_ "GenSigTimeoutTime" BU_SG_REL_ MXB SG_ 2549088407 LED_DK3_R_SNI 5000;
BA_REL_ "GenSigTimeoutTime" BU_SG_REL_ AFS SG_ 2549088407 NM_LED_DK3_R_Wakeup 5000;
BA_REL_ "GenSigTimeoutTime" BU_SG_REL_ BCM1 SG_ 2549088407 NM_LED_DK3_R_Wakeup 5000;
BA_REL_ "GenSigTimeoutTime" BU_SG_REL_ FCM SG_ 2549088407 NM_LED_DK3_R_Wakeup 5000;
BA_REL_ "GenSigTimeoutTime" BU_SG_REL_ MXB SG_ 2549088407 NM_LED_DK3_R_Wakeup 5000;
BA_REL_ "GenSigTimeoutTime" BU_SG_REL_ AFS SG_ 2549088407 NM_LED_DK3_R_Lokalaktiv 5000;
BA_REL_ "GenSigTimeoutTime" BU_SG_REL_ BCM1 SG_ 2549088407 NM_LED_DK3_R_Lokalaktiv 5000;
BA_REL_ "GenSigTimeoutTime" BU_SG_REL_ FCM SG_ 2549088407 NM_LED_DK3_R_Lokalaktiv 5000;
BA_REL_ "GenSigTimeoutTime" BU_SG_REL_ MXB SG_ 2549088407 NM_LED_DK3_R_Lokalaktiv 5000;
BA_REL_ "GenSigTimeoutTime" BU_SG_REL_ AFS SG_ 2549088407 LED_DK3_R_KD_Fehler 5000;
BA_REL_ "GenSigTimeoutTime" BU_SG_REL_ BCM1 SG_ 2549088407 LED_DK3_R_KD_Fehler 5000;
BA_REL_ "GenSigTimeoutTime" BU_SG_REL_ FCM SG_ 2549088407 LED_DK3_R_KD_Fehler 5000;
BA_REL_ "GenSigTimeoutTime" BU_SG_REL_ MXB SG_ 2549088407 LED_DK3_R_KD_Fehler 5000;
BA_REL_ "GenSigTimeoutTime" BU_SG_REL_ BCM1 SG_ 1387 LCM_Feh_L_CRC 2000;
BA_REL_ "GenSigTimeoutTime" BU_SG_REL_ MXB SG_ 1387 LCM_Feh_L_CRC 2000;
BA_REL_ "GenSigTimeoutTime" BU_SG_REL_ BCM1 SG_ 1387 LCM_Feh_L_BZ 2000;
BA_REL_ "GenSigTimeoutTime" BU_SG_REL_ MXB SG_ 1387 LCM_Feh_L_BZ 2000;
BA_REL_ "GenSigTimeoutTime" BU_SG_REL_ AFS SG_ 1387 LCM_TFL_Fehler_L 2000;
BA_REL_ "GenSigTimeoutTime" BU_SG_REL_ BCM1 SG_ 1387 LCM_TFL_Fehler_L 2000;
BA_REL_ "GenSigTimeoutTime" BU_SG_REL_ FCM SG_ 1387 LCM_TFL_Fehler_L 2000;
BA_REL_ "GenSigTimeoutTime" BU_SG_REL_ MXB SG_ 1387 LCM_TFL_Fehler_L 2000;
BA_REL_ "GenSigTimeoutTime" BU_SG_REL_ AFS SG_ 1387 LCM_Sonstiger_Fehler_L 2000;
BA_REL_ "GenSigTimeoutTime" BU_SG_REL_ BCM1 SG_ 1387 LCM_Sonstiger_Fehler_L 2000;
BA_REL_ "GenSigTimeoutTime" BU_SG_REL_ FCM SG_ 1387 LCM_Sonstiger_Fehler_L 2000;
BA_REL_ "GenSigTimeoutTime" BU_SG_REL_ MXB SG_ 1387 LCM_Sonstiger_Fehler_L 2000;
BA_REL_ "GenSigTimeoutTime" BU_SG_REL_ AFS SG_ 1387 LCM_SM_Fehler_L 2000;
BA_REL_ "GenSigTimeoutTime" BU_SG_REL_ BCM1 SG_ 1387 LCM_SM_Fehler_L 2000;
BA_REL_ "GenSigTimeoutTime" BU_SG_REL_ FCM SG_ 1387 LCM_SM_Fehler_L 2000;
BA_REL_ "GenSigTimeoutTime" BU_SG_REL_ MXB SG_ 1387 LCM_SM_Fehler_L 2000;
BA_REL_ "GenSigTimeoutTime" BU_SG_REL_ AFS SG_ 1387 LCM_Shutter_Fehler_L 2000;
BA_REL_ "GenSigTimeoutTime" BU_SG_REL_ BCM1 SG_ 1387 LCM_Shutter_Fehler_L 2000;
BA_REL_ "GenSigTimeoutTime" BU_SG_REL_ FCM SG_ 1387 LCM_Shutter_Fehler_L 2000;
BA_REL_ "GenSigTimeoutTime" BU_SG_REL_ MXB SG_ 1387 LCM_Shutter_Fehler_L 2000;
BA_REL_ "GenSigTimeoutTime" BU_SG_REL_ AFS SG_ 1387 LCM_PO_Fehler_L 2000;
BA_REL_ "GenSigTimeoutTime" BU_SG_REL_ BCM1 SG_ 1387 LCM_PO_Fehler_L 2000;
BA_REL_ "GenSigTimeoutTime" BU_SG_REL_ FCM SG_ 1387 LCM_PO_Fehler_L 2000;
BA_REL_ "GenSigTimeoutTime" BU_SG_REL_ MXB SG_ 1387 LCM_PO_Fehler_L 2000;
BA_REL_ "GenSigTimeoutTime" BU_SG_REL_ AFS SG_ 1387 LCM_Blinker_Fehler_L 2000;
BA_REL_ "GenSigTimeoutTime" BU_SG_REL_ BCM1 SG_ 1387 LCM_Blinker_Fehler_L 2000;
BA_REL_ "GenSigTimeoutTime" BU_SG_REL_ FCM SG_ 1387 LCM_Blinker_Fehler_L 2000;
BA_REL_ "GenSigTimeoutTime" BU_SG_REL_ MXB SG_ 1387 LCM_Blinker_Fehler_L 2000;
BA_REL_ "GenSigTimeoutTime" BU_SG_REL_ AFS SG_ 1387 LCM_LWR_L_allg_Fehler 2000;
BA_REL_ "GenSigTimeoutTime" BU_SG_REL_ BCM1 SG_ 1387 LCM_LWR_L_allg_Fehler 2000;
BA_REL_ "GenSigTimeoutTime" BU_SG_REL_ FCM SG_ 1387 LCM_LWR_L_allg_Fehler 2000;
BA_REL_ "GenSigTimeoutTime" BU_SG_REL_ MXB SG_ 1387 LCM_LWR_L_allg_Fehler 2000;
BA_REL_ "GenSigTimeoutTime" BU_SG_REL_ AFS SG_ 1387 LCM_LWR_L_defekt_Fehler 2000;
BA_REL_ "GenSigTimeoutTime" BU_SG_REL_ BCM1 SG_ 1387 LCM_LWR_L_defekt_Fehler 2000;
BA_REL_ "GenSigTimeoutTime" BU_SG_REL_ FCM SG_ 1387 LCM_LWR_L_defekt_Fehler 2000;
BA_REL_ "GenSigTimeoutTime" BU_SG_REL_ MXB SG_ 1387 LCM_LWR_L_defekt_Fehler 2000;
BA_REL_ "GenSigTimeoutTime" BU_SG_REL_ AFS SG_ 1387 LCM_Datensatz_Fehler_L 2000;
BA_REL_ "GenSigTimeoutTime" BU_SG_REL_ BCM1 SG_ 1387 LCM_Datensatz_Fehler_L 2000;
BA_REL_ "GenSigTimeoutTime" BU_SG_REL_ FCM SG_ 1387 LCM_Datensatz_Fehler_L 2000;
BA_REL_ "GenSigTimeoutTime" BU_SG_REL_ MXB SG_ 1387 LCM_Datensatz_Fehler_L 2000;
BA_REL_ "GenSigTimeoutTime" BU_SG_REL_ AFS SG_ 1387 LCM_DKL_L_defekt_Fehler 2000;
BA_REL_ "GenSigTimeoutTime" BU_SG_REL_ BCM1 SG_ 1387 LCM_DKL_L_defekt_Fehler 2000;
BA_REL_ "GenSigTimeoutTime" BU_SG_REL_ FCM SG_ 1387 LCM_DKL_L_defekt_Fehler 2000;
BA_REL_ "GenSigTimeoutTime" BU_SG_REL_ MXB SG_ 1387 LCM_DKL_L_defekt_Fehler 2000;
BA_REL_ "GenSigTimeoutTime" BU_SG_REL_ AFS SG_ 1387 LCM_GLW_L_defekt_Fehler 2000;
BA_REL_ "GenSigTimeoutTime" BU_SG_REL_ BCM1 SG_ 1387 LCM_GLW_L_defekt_Fehler 2000;
BA_REL_ "GenSigTimeoutTime" BU_SG_REL_ FCM SG_ 1387 LCM_GLW_L_defekt_Fehler 2000;
BA_REL_ "GenSigTimeoutTime" BU_SG_REL_ MXB SG_ 1387 LCM_GLW_L_defekt_Fehler 2000;
BA_REL_ "GenSigTimeoutTime" BU_SG_REL_ AFS SG_ 1387 LCM_SKL_L_defekt_Fehler 2000;
BA_REL_ "GenSigTimeoutTime" BU_SG_REL_ BCM1 SG_ 1387 LCM_SKL_L_defekt_Fehler 2000;
BA_REL_ "GenSigTimeoutTime" BU_SG_REL_ FCM SG_ 1387 LCM_SKL_L_defekt_Fehler 2000;
BA_REL_ "GenSigTimeoutTime" BU_SG_REL_ MXB SG_ 1387 LCM_SKL_L_defekt_Fehler 2000;
BA_REL_ "GenSigTimeoutTime" BU_SG_REL_ BCM1 SG_ 1388 LCM_Feh_R_CRC 2000;
BA_REL_ "GenSigTimeoutTime" BU_SG_REL_ MXB SG_ 1388 LCM_Feh_R_CRC 2000;
BA_REL_ "GenSigTimeoutTime" BU_SG_REL_ BCM1 SG_ 1388 LCM_Feh_R_BZ 2000;
BA_REL_ "GenSigTimeoutTime" BU_SG_REL_ MXB SG_ 1388 LCM_Feh_R_BZ 2000;
BA_REL_ "GenSigTimeoutTime" BU_SG_REL_ AFS SG_ 1388 LCM_TFL_Fehler_R 2000;
BA_REL_ "GenSigTimeoutTime" BU_SG_REL_ BCM1 SG_ 1388 LCM_TFL_Fehler_R 2000;
BA_REL_ "GenSigTimeoutTime" BU_SG_REL_ FCM SG_ 1388 LCM_TFL_Fehler_R 2000;
BA_REL_ "GenSigTimeoutTime" BU_SG_REL_ MXB SG_ 1388 LCM_TFL_Fehler_R 2000;
BA_REL_ "GenSigTimeoutTime" BU_SG_REL_ AFS SG_ 1388 LCM_Sonstiger_Fehler_R 2000;
BA_REL_ "GenSigTimeoutTime" BU_SG_REL_ BCM1 SG_ 1388 LCM_Sonstiger_Fehler_R 2000;
BA_REL_ "GenSigTimeoutTime" BU_SG_REL_ FCM SG_ 1388 LCM_Sonstiger_Fehler_R 2000;
BA_REL_ "GenSigTimeoutTime" BU_SG_REL_ MXB SG_ 1388 LCM_Sonstiger_Fehler_R 2000;
BA_REL_ "GenSigTimeoutTime" BU_SG_REL_ AFS SG_ 1388 LCM_SM_Fehler_R 2000;
BA_REL_ "GenSigTimeoutTime" BU_SG_REL_ BCM1 SG_ 1388 LCM_SM_Fehler_R 2000;
BA_REL_ "GenSigTimeoutTime" BU_SG_REL_ FCM SG_ 1388 LCM_SM_Fehler_R 2000;
BA_REL_ "GenSigTimeoutTime" BU_SG_REL_ MXB SG_ 1388 LCM_SM_Fehler_R 2000;
BA_REL_ "GenSigTimeoutTime" BU_SG_REL_ AFS SG_ 1388 LCM_Shutter_Fehler_R 2000;
BA_REL_ "GenSigTimeoutTime" BU_SG_REL_ BCM1 SG_ 1388 LCM_Shutter_Fehler_R 2000;
BA_REL_ "GenSigTimeoutTime" BU_SG_REL_ FCM SG_ 1388 LCM_Shutter_Fehler_R 2000;
BA_REL_ "GenSigTimeoutTime" BU_SG_REL_ MXB SG_ 1388 LCM_Shutter_Fehler_R 2000;
BA_REL_ "GenSigTimeoutTime" BU_SG_REL_ AFS SG_ 1388 LCM_PO_Fehler_R 2000;
BA_REL_ "GenSigTimeoutTime" BU_SG_REL_ BCM1 SG_ 1388 LCM_PO_Fehler_R 2000;
BA_REL_ "GenSigTimeoutTime" BU_SG_REL_ FCM SG_ 1388 LCM_PO_Fehler_R 2000;
BA_REL_ "GenSigTimeoutTime" BU_SG_REL_ MXB SG_ 1388 LCM_PO_Fehler_R 2000;
BA_REL_ "GenSigTimeoutTime" BU_SG_REL_ AFS SG_ 1388 LCM_Blinker_Fehler_R 2000;
BA_REL_ "GenSigTimeoutTime" BU_SG_REL_ BCM1 SG_ 1388 LCM_Blinker_Fehler_R 2000;
BA_REL_ "GenSigTimeoutTime" BU_SG_REL_ FCM SG_ 1388 LCM_Blinker_Fehler_R 2000;
BA_REL_ "GenSigTimeoutTime" BU_SG_REL_ MXB SG_ 1388 LCM_Blinker_Fehler_R 2000;
BA_REL_ "GenSigTimeoutTime" BU_SG_REL_ AFS SG_ 1388 LCM_LWR_R_allg_Fehler 2000;
BA_REL_ "GenSigTimeoutTime" BU_SG_REL_ BCM1 SG_ 1388 LCM_LWR_R_allg_Fehler 2000;
BA_REL_ "GenSigTimeoutTime" BU_SG_REL_ FCM SG_ 1388 LCM_LWR_R_allg_Fehler 2000;
BA_REL_ "GenSigTimeoutTime" BU_SG_REL_ MXB SG_ 1388 LCM_LWR_R_allg_Fehler 2000;
BA_REL_ "GenSigTimeoutTime" BU_SG_REL_ AFS SG_ 1388 LCM_LWR_R_defekt_Fehler 2000;
BA_REL_ "GenSigTimeoutTime" BU_SG_REL_ BCM1 SG_ 1388 LCM_LWR_R_defekt_Fehler 2000;
BA_REL_ "GenSigTimeoutTime" BU_SG_REL_ FCM SG_ 1388 LCM_LWR_R_defekt_Fehler 2000;
BA_REL_ "GenSigTimeoutTime" BU_SG_REL_ MXB SG_ 1388 LCM_LWR_R_defekt_Fehler 2000;
BA_REL_ "GenSigTimeoutTime" BU_SG_REL_ AFS SG_ 1388 LCM_Datensatz_Fehler_R 2000;
BA_REL_ "GenSigTimeoutTime" BU_SG_REL_ BCM1 SG_ 1388 LCM_Datensatz_Fehler_R 2000;
BA_REL_ "GenSigTimeoutTime" BU_SG_REL_ FCM SG_ 1388 LCM_Datensatz_Fehler_R 2000;
BA_REL_ "GenSigTimeoutTime" BU_SG_REL_ MXB SG_ 1388 LCM_Datensatz_Fehler_R 2000;
BA_REL_ "GenSigTimeoutTime" BU_SG_REL_ AFS SG_ 1388 LCM_DKL_R_defekt_Fehler 2000;
BA_REL_ "GenSigTimeoutTime" BU_SG_REL_ BCM1 SG_ 1388 LCM_DKL_R_defekt_Fehler 2000;
BA_REL_ "GenSigTimeoutTime" BU_SG_REL_ FCM SG_ 1388 LCM_DKL_R_defekt_Fehler 2000;
BA_REL_ "GenSigTimeoutTime" BU_SG_REL_ MXB SG_ 1388 LCM_DKL_R_defekt_Fehler 2000;
BA_REL_ "GenSigTimeoutTime" BU_SG_REL_ AFS SG_ 1388 LCM_GLW_R_defekt_Fehler 2000;
BA_REL_ "GenSigTimeoutTime" BU_SG_REL_ BCM1 SG_ 1388 LCM_GLW_R_defekt_Fehler 2000;
BA_REL_ "GenSigTimeoutTime" BU_SG_REL_ FCM SG_ 1388 LCM_GLW_R_defekt_Fehler 2000;
BA_REL_ "GenSigTimeoutTime" BU_SG_REL_ MXB SG_ 1388 LCM_GLW_R_defekt_Fehler 2000;
BA_REL_ "GenSigTimeoutTime" BU_SG_REL_ AFS SG_ 1388 LCM_SKL_R_defekt_Fehler 2000;
BA_REL_ "GenSigTimeoutTime" BU_SG_REL_ BCM1 SG_ 1388 LCM_SKL_R_defekt_Fehler 2000;
BA_REL_ "GenSigTimeoutTime" BU_SG_REL_ FCM SG_ 1388 LCM_SKL_R_defekt_Fehler 2000;
BA_REL_ "GenSigTimeoutTime" BU_SG_REL_ MXB SG_ 1388 LCM_SKL_R_defekt_Fehler 2000;
BA_REL_ "GenSigTimeoutTime" BU_SG_REL_ LCM_L SG_ 403 LCM_Soll_CRC 1000;
BA_REL_ "GenSigTimeoutTime" BU_SG_REL_ LCM_R SG_ 403 LCM_Soll_CRC 1000;
BA_REL_ "GenSigTimeoutTime" BU_SG_REL_ LLP_L SG_ 403 LCM_Soll_CRC 1000;
BA_REL_ "GenSigTimeoutTime" BU_SG_REL_ LLP_R SG_ 403 LCM_Soll_CRC 1000;
BA_REL_ "GenSigTimeoutTime" BU_SG_REL_ LCM_L SG_ 403 LCM_Soll_BZ 1000;
BA_REL_ "GenSigTimeoutTime" BU_SG_REL_ LCM_R SG_ 403 LCM_Soll_BZ 1000;
BA_REL_ "GenSigTimeoutTime" BU_SG_REL_ LLP_L SG_ 403 LCM_Soll_BZ 1000;
BA_REL_ "GenSigTimeoutTime" BU_SG_REL_ LLP_R SG_ 403 LCM_Soll_BZ 1000;
BA_REL_ "GenSigTimeoutTime" BU_SG_REL_ LCM_L SG_ 403 LCM_TFL_L_Anf 1000;
BA_REL_ "GenSigTimeoutTime" BU_SG_REL_ LLP_L SG_ 403 LCM_TFL_L_Anf 1000;
BA_REL_ "GenSigTimeoutTime" BU_SG_REL_ LCM_R SG_ 403 LCM_TFL_R_Anf 1000;
BA_REL_ "GenSigTimeoutTime" BU_SG_REL_ LLP_R SG_ 403 LCM_TFL_R_Anf 1000;
BA_REL_ "GenSigTimeoutTime" BU_SG_REL_ LCM_L SG_ 403 LCM_Abschaltung_Vbat_L_Anf 1000;
BA_REL_ "GenSigTimeoutTime" BU_SG_REL_ LLP_L SG_ 403 LCM_Abschaltung_Vbat_L_Anf 1000;
BA_REL_ "GenSigTimeoutTime" BU_SG_REL_ LCM_R SG_ 403 LCM_Abschaltung_Vbat_R_Anf 1000;
BA_REL_ "GenSigTimeoutTime" BU_SG_REL_ LLP_R SG_ 403 LCM_Abschaltung_Vbat_R_Anf 1000;
BA_REL_ "GenSigTimeoutTime" BU_SG_REL_ LCM_L SG_ 403 LCM_Blinker_L_Anf 1000;
BA_REL_ "GenSigTimeoutTime" BU_SG_REL_ LLP_L SG_ 403 LCM_Blinker_L_Anf 1000;
BA_REL_ "GenSigTimeoutTime" BU_SG_REL_ LCM_R SG_ 403 LCM_Blinker_R_Anf 1000;
BA_REL_ "GenSigTimeoutTime" BU_SG_REL_ LLP_R SG_ 403 LCM_Blinker_R_Anf 1000;
BA_REL_ "GenSigTimeoutTime" BU_SG_REL_ LCM_L SG_ 403 LCM_Blinkerzyklus_L 1000;
BA_REL_ "GenSigTimeoutTime" BU_SG_REL_ LLP_L SG_ 403 LCM_Blinkerzyklus_L 1000;
BA_REL_ "GenSigTimeoutTime" BU_SG_REL_ LCM_R SG_ 403 LCM_Blinkerzyklus_R 1000;
BA_REL_ "GenSigTimeoutTime" BU_SG_REL_ LLP_R SG_ 403 LCM_Blinkerzyklus_R 1000;
BA_REL_ "GenSigTimeoutTime" BU_SG_REL_ LCM_L SG_ 403 LCM_Sh_L_Anf 1000;
BA_REL_ "GenSigTimeoutTime" BU_SG_REL_ LLP_L SG_ 403 LCM_Sh_L_Anf 1000;
BA_REL_ "GenSigTimeoutTime" BU_SG_REL_ LCM_R SG_ 403 LCM_Sh_R_Anf 1000;
BA_REL_ "GenSigTimeoutTime" BU_SG_REL_ LLP_R SG_ 403 LCM_Sh_R_Anf 1000;
BA_REL_ "GenSigTimeoutTime" BU_SG_REL_ LCM_L SG_ 403 LCM_SM_L_Anf 1000;
BA_REL_ "GenSigTimeoutTime" BU_SG_REL_ LLP_L SG_ 403 LCM_SM_L_Anf 1000;
BA_REL_ "GenSigTimeoutTime" BU_SG_REL_ LCM_R SG_ 403 LCM_SM_R_Anf 1000;
BA_REL_ "GenSigTimeoutTime" BU_SG_REL_ LLP_R SG_ 403 LCM_SM_R_Anf 1000;
BA_REL_ "GenSigTimeoutTime" BU_SG_REL_ LCM_L SG_ 403 LCM_univ_1_L_Anf 1000;
BA_REL_ "GenSigTimeoutTime" BU_SG_REL_ LLP_L SG_ 403 LCM_univ_1_L_Anf 1000;
BA_REL_ "GenSigTimeoutTime" BU_SG_REL_ LCM_R SG_ 403 LCM_univ_1_R_Anf 1000;
BA_REL_ "GenSigTimeoutTime" BU_SG_REL_ LLP_R SG_ 403 LCM_univ_1_R_Anf 1000;
BA_REL_ "GenSigTimeoutTime" BU_SG_REL_ LCM_L SG_ 403 LCM_PO_L_Anf 1000;
BA_REL_ "GenSigTimeoutTime" BU_SG_REL_ LLP_L SG_ 403 LCM_PO_L_Anf 1000;
BA_REL_ "GenSigTimeoutTime" BU_SG_REL_ LCM_R SG_ 403 LCM_PO_R_Anf 1000;
BA_REL_ "GenSigTimeoutTime" BU_SG_REL_ LLP_R SG_ 403 LCM_PO_R_Anf 1000;
BA_REL_ "GenSigTimeoutTime" BU_SG_REL_ LCM_L SG_ 403 LCM_PL_L_Anf 1000;
BA_REL_ "GenSigTimeoutTime" BU_SG_REL_ LLP_L SG_ 403 LCM_PL_L_Anf 1000;
BA_REL_ "GenSigTimeoutTime" BU_SG_REL_ LCM_R SG_ 403 LCM_PL_R_Anf 1000;
BA_REL_ "GenSigTimeoutTime" BU_SG_REL_ LLP_R SG_ 403 LCM_PL_R_Anf 1000;
BA_REL_ "GenSigTimeoutTime" BU_SG_REL_ LCM_L SG_ 403 LCM_Leistungsreduzierung_Anf 1000;
BA_REL_ "GenSigTimeoutTime" BU_SG_REL_ LCM_R SG_ 403 LCM_Leistungsreduzierung_Anf 1000;
BA_REL_ "GenSigTimeoutTime" BU_SG_REL_ LLP_L SG_ 403 LCM_Leistungsreduzierung_Anf 1000;
BA_REL_ "GenSigTimeoutTime" BU_SG_REL_ LLP_R SG_ 403 LCM_Leistungsreduzierung_Anf 1000;
BA_REL_ "GenSigTimeoutTime" BU_SG_REL_ LCM_L SG_ 403 LCM_Blinkerwischen_Anf 1000;
BA_REL_ "GenSigTimeoutTime" BU_SG_REL_ LCM_R SG_ 403 LCM_Blinkerwischen_Anf 1000;
BA_REL_ "GenSigTimeoutTime" BU_SG_REL_ LLP_L SG_ 403 LCM_Blinkerwischen_Anf 1000;
BA_REL_ "GenSigTimeoutTime" BU_SG_REL_ LLP_R SG_ 403 LCM_Blinkerwischen_Anf 1000;
BA_REL_ "GenSigTimeoutTime" BU_SG_REL_ LCM_L SG_ 403 LCM_Animiertes_TFL_Anf 1000;
BA_REL_ "GenSigTimeoutTime" BU_SG_REL_ LCM_R SG_ 403 LCM_Animiertes_TFL_Anf 1000;
BA_REL_ "GenSigTimeoutTime" BU_SG_REL_ LLP_L SG_ 403 LCM_Animiertes_TFL_Anf 1000;
BA_REL_ "GenSigTimeoutTime" BU_SG_REL_ LLP_R SG_ 403 LCM_Animiertes_TFL_Anf 1000;
BA_REL_ "GenSigTimeoutTime" BU_SG_REL_ LCM_L SG_ 403 LCM_Signaturlicht_Anf 1000;
BA_REL_ "GenSigTimeoutTime" BU_SG_REL_ LCM_R SG_ 403 LCM_Signaturlicht_Anf 1000;
BA_REL_ "GenSigTimeoutTime" BU_SG_REL_ LLP_L SG_ 403 LCM_Signaturlicht_Anf 1000;
BA_REL_ "GenSigTimeoutTime" BU_SG_REL_ LLP_R SG_ 403 LCM_Signaturlicht_Anf 1000;
BA_REL_ "GenSigTimeoutTime" BU_SG_REL_ LCM_L SG_ 403 LCM_ECE_SAE_Umschaltung_Anf 1000;
BA_REL_ "GenSigTimeoutTime" BU_SG_REL_ LCM_R SG_ 403 LCM_ECE_SAE_Umschaltung_Anf 1000;
BA_REL_ "GenSigTimeoutTime" BU_SG_REL_ LLP_L SG_ 403 LCM_ECE_SAE_Umschaltung_Anf 1000;
BA_REL_ "GenSigTimeoutTime" BU_SG_REL_ LLP_R SG_ 403 LCM_ECE_SAE_Umschaltung_Anf 1000;
BA_REL_ "GenSigTimeoutTime" BU_SG_REL_ LCM_L SG_ 403 BM_Autobahn 1000;
BA_REL_ "GenSigTimeoutTime" BU_SG_REL_ LCM_R SG_ 403 BM_Autobahn 1000;
BA_REL_ "GenSigTimeoutTime" BU_SG_REL_ LLP_L SG_ 403 BM_Autobahn 1000;
BA_REL_ "GenSigTimeoutTime" BU_SG_REL_ LLP_R SG_ 403 BM_Autobahn 1000;
BA_REL_ "GenSigTimeoutTime" BU_SG_REL_ LCM_L SG_ 403 BM_ZV_auf 1000;
BA_REL_ "GenSigTimeoutTime" BU_SG_REL_ LCM_R SG_ 403 BM_ZV_auf 1000;
BA_REL_ "GenSigTimeoutTime" BU_SG_REL_ LLP_L SG_ 403 BM_ZV_auf 1000;
BA_REL_ "GenSigTimeoutTime" BU_SG_REL_ LLP_R SG_ 403 BM_ZV_auf 1000;
BA_REL_ "GenSigTimeoutTime" BU_SG_REL_ LCM_L SG_ 403 BM_ZV_zu 1000;
BA_REL_ "GenSigTimeoutTime" BU_SG_REL_ LCM_R SG_ 403 BM_ZV_zu 1000;
BA_REL_ "GenSigTimeoutTime" BU_SG_REL_ LLP_L SG_ 403 BM_ZV_zu 1000;
BA_REL_ "GenSigTimeoutTime" BU_SG_REL_ LLP_R SG_ 403 BM_ZV_zu 1000;
BA_REL_ "GenSigTimeoutTime" BU_SG_REL_ LCM_L SG_ 403 BCM1_CH_aktiv 1000;
BA_REL_ "GenSigTimeoutTime" BU_SG_REL_ LCM_R SG_ 403 BCM1_CH_aktiv 1000;
BA_REL_ "GenSigTimeoutTime" BU_SG_REL_ LED_DK3_LM_L SG_ 403 BCM1_CH_aktiv 1000;
BA_REL_ "GenSigTimeoutTime" BU_SG_REL_ LED_DK3_LM_R SG_ 403 BCM1_CH_aktiv 1000;
BA_REL_ "GenSigTimeoutTime" BU_SG_REL_ LED_LM_L SG_ 403 BCM1_CH_aktiv 1000;
BA_REL_ "GenSigTimeoutTime" BU_SG_REL_ LED_LM_R SG_ 403 BCM1_CH_aktiv 1000;
BA_REL_ "GenSigTimeoutTime" BU_SG_REL_ LLP_L SG_ 403 BCM1_CH_aktiv 1000;
BA_REL_ "GenSigTimeoutTime" BU_SG_REL_ LLP_R SG_ 403 BCM1_CH_aktiv 1000;
BA_REL_ "GenSigTimeoutTime" BU_SG_REL_ LCM_L SG_ 403 BCM1_LH_aktiv 1000;
BA_REL_ "GenSigTimeoutTime" BU_SG_REL_ LCM_R SG_ 403 BCM1_LH_aktiv 1000;
BA_REL_ "GenSigTimeoutTime" BU_SG_REL_ LED_DK3_LM_L SG_ 403 BCM1_LH_aktiv 1000;
BA_REL_ "GenSigTimeoutTime" BU_SG_REL_ LED_DK3_LM_R SG_ 403 BCM1_LH_aktiv 1000;
BA_REL_ "GenSigTimeoutTime" BU_SG_REL_ LED_LM_L SG_ 403 BCM1_LH_aktiv 1000;
BA_REL_ "GenSigTimeoutTime" BU_SG_REL_ LED_LM_R SG_ 403 BCM1_LH_aktiv 1000;
BA_REL_ "GenSigTimeoutTime" BU_SG_REL_ LLP_L SG_ 403 BCM1_LH_aktiv 1000;
BA_REL_ "GenSigTimeoutTime" BU_SG_REL_ LLP_R SG_ 403 BCM1_LH_aktiv 1000;
BA_REL_ "GenSigTimeoutTime" BU_SG_REL_ BCM1 SG_ 411 LCM_Sta_L_CRC 1000;
BA_REL_ "GenSigTimeoutTime" BU_SG_REL_ MXB SG_ 411 LCM_Sta_L_CRC 1000;
BA_REL_ "GenSigTimeoutTime" BU_SG_REL_ BCM1 SG_ 411 LCM_Sta_L_BZ 1000;
BA_REL_ "GenSigTimeoutTime" BU_SG_REL_ MXB SG_ 411 LCM_Sta_L_BZ 1000;
BA_REL_ "GenSigTimeoutTime" BU_SG_REL_ BCM1 SG_ 411 LCM_Ausgangsleistungsred_L_Sta 1000;
BA_REL_ "GenSigTimeoutTime" BU_SG_REL_ MXB SG_ 411 LCM_Ausgangsleistungsred_L_Sta 1000;
BA_REL_ "GenSigTimeoutTime" BU_SG_REL_ AFS SG_ 411 LCM_Abschaltbestaetigung_L 1000;
BA_REL_ "GenSigTimeoutTime" BU_SG_REL_ BCM1 SG_ 411 LCM_Abschaltbestaetigung_L 1000;
BA_REL_ "GenSigTimeoutTime" BU_SG_REL_ FCM SG_ 411 LCM_Abschaltbestaetigung_L 1000;
BA_REL_ "GenSigTimeoutTime" BU_SG_REL_ MXB SG_ 411 LCM_Abschaltbestaetigung_L 1000;
BA_REL_ "GenSigTimeoutTime" BU_SG_REL_ AFS SG_ 411 LCM_Blinker_L_Sta 1000;
BA_REL_ "GenSigTimeoutTime" BU_SG_REL_ BCM1 SG_ 411 LCM_Blinker_L_Sta 1000;
BA_REL_ "GenSigTimeoutTime" BU_SG_REL_ FCM SG_ 411 LCM_Blinker_L_Sta 1000;
BA_REL_ "GenSigTimeoutTime" BU_SG_REL_ MXB SG_ 411 LCM_Blinker_L_Sta 1000;
BA_REL_ "GenSigTimeoutTime" BU_SG_REL_ BCM1 SG_ 411 LCM_PL_L_Sta 1000;
BA_REL_ "GenSigTimeoutTime" BU_SG_REL_ MXB SG_ 411 LCM_PL_L_Sta 1000;
BA_REL_ "GenSigTimeoutTime" BU_SG_REL_ BCM1 SG_ 411 LCM_PO_L_Sta 1000;
BA_REL_ "GenSigTimeoutTime" BU_SG_REL_ MXB SG_ 411 LCM_PO_L_Sta 1000;
BA_REL_ "GenSigTimeoutTime" BU_SG_REL_ BCM1 SG_ 411 LCM_Sh_L_Sta 1000;
BA_REL_ "GenSigTimeoutTime" BU_SG_REL_ MXB SG_ 411 LCM_Sh_L_Sta 1000;
BA_REL_ "GenSigTimeoutTime" BU_SG_REL_ BCM1 SG_ 411 LCM_SM_L_Sta 1000;
BA_REL_ "GenSigTimeoutTime" BU_SG_REL_ MXB SG_ 411 LCM_SM_L_Sta 1000;
BA_REL_ "GenSigTimeoutTime" BU_SG_REL_ BCM1 SG_ 411 LCM_TFL_L_Sta 1000;
BA_REL_ "GenSigTimeoutTime" BU_SG_REL_ MXB SG_ 411 LCM_TFL_L_Sta 1000;
BA_REL_ "GenSigTimeoutTime" BU_SG_REL_ BCM1 SG_ 411 LCM_univ_1_L_Sta 1000;
BA_REL_ "GenSigTimeoutTime" BU_SG_REL_ MXB SG_ 411 LCM_univ_1_L_Sta 1000;
BA_REL_ "GenSigTimeoutTime" BU_SG_REL_ BCM1 SG_ 413 LCM_Sta_R_CRC 1000;
BA_REL_ "GenSigTimeoutTime" BU_SG_REL_ MXB SG_ 413 LCM_Sta_R_CRC 1000;
BA_REL_ "GenSigTimeoutTime" BU_SG_REL_ BCM1 SG_ 413 LCM_Sta_R_BZ 1000;
BA_REL_ "GenSigTimeoutTime" BU_SG_REL_ MXB SG_ 413 LCM_Sta_R_BZ 1000;
BA_REL_ "GenSigTimeoutTime" BU_SG_REL_ BCM1 SG_ 413 LCM_Ausgangsleistungsred_R_Sta 1000;
BA_REL_ "GenSigTimeoutTime" BU_SG_REL_ MXB SG_ 413 LCM_Ausgangsleistungsred_R_Sta 1000;
BA_REL_ "GenSigTimeoutTime" BU_SG_REL_ AFS SG_ 413 LCM_Abschaltbestaetigung_R 1000;
BA_REL_ "GenSigTimeoutTime" BU_SG_REL_ BCM1 SG_ 413 LCM_Abschaltbestaetigung_R 1000;
BA_REL_ "GenSigTimeoutTime" BU_SG_REL_ FCM SG_ 413 LCM_Abschaltbestaetigung_R 1000;
BA_REL_ "GenSigTimeoutTime" BU_SG_REL_ MXB SG_ 413 LCM_Abschaltbestaetigung_R 1000;
BA_REL_ "GenSigTimeoutTime" BU_SG_REL_ AFS SG_ 413 LCM_Blinker_R_Sta 1000;
BA_REL_ "GenSigTimeoutTime" BU_SG_REL_ BCM1 SG_ 413 LCM_Blinker_R_Sta 1000;
BA_REL_ "GenSigTimeoutTime" BU_SG_REL_ FCM SG_ 413 LCM_Blinker_R_Sta 1000;
BA_REL_ "GenSigTimeoutTime" BU_SG_REL_ MXB SG_ 413 LCM_Blinker_R_Sta 1000;
BA_REL_ "GenSigTimeoutTime" BU_SG_REL_ BCM1 SG_ 413 LCM_PL_R_Sta 1000;
BA_REL_ "GenSigTimeoutTime" BU_SG_REL_ MXB SG_ 413 LCM_PL_R_Sta 1000;
BA_REL_ "GenSigTimeoutTime" BU_SG_REL_ BCM1 SG_ 413 LCM_PO_R_Sta 1000;
BA_REL_ "GenSigTimeoutTime" BU_SG_REL_ MXB SG_ 413 LCM_PO_R_Sta 1000;
BA_REL_ "GenSigTimeoutTime" BU_SG_REL_ BCM1 SG_ 413 LCM_Sh_R_Sta 1000;
BA_REL_ "GenSigTimeoutTime" BU_SG_REL_ MXB SG_ 413 LCM_Sh_R_Sta 1000;
BA_REL_ "GenSigTimeoutTime" BU_SG_REL_ BCM1 SG_ 413 LCM_SM_R_Sta 1000;
BA_REL_ "GenSigTimeoutTime" BU_SG_REL_ MXB SG_ 413 LCM_SM_R_Sta 1000;
BA_REL_ "GenSigTimeoutTime" BU_SG_REL_ BCM1 SG_ 413 LCM_TFL_R_Sta 1000;
BA_REL_ "GenSigTimeoutTime" BU_SG_REL_ MXB SG_ 413 LCM_TFL_R_Sta 1000;
BA_REL_ "GenSigTimeoutTime" BU_SG_REL_ BCM1 SG_ 413 LCM_univ_1_R_Sta 1000;
BA_REL_ "GenSigTimeoutTime" BU_SG_REL_ MXB SG_ 413 LCM_univ_1_R_Sta 1000;
VAL_ 919 FGR_Akt_KS_Plus 0 "kein_Fehler" 1 "Fehler" ;
VAL_ 919 FGR_RAkt_KS_Plus 0 "Fehlermoeglichkeit_geprueft" 1 "Fehlermoeglichkeit_nicht_geprueft" ;
VAL_ 919 FGR_Akt_KS_Gnd 0 "kein_Fehler" 1 "Fehler" ;
VAL_ 919 FGR_RAkt_KS_Gnd 0 "Fehlermoeglichkeit_geprueft" 1 "Fehlermoeglichkeit_nicht_geprueft" ;
VAL_ 919 FGR_Akt_OL 0 "kein_Fehler" 1 "Fehler" ;
VAL_ 919 FGR_RAkt_OL 0 "Fehlermoeglichkeit_geprueft" 1 "Fehlermoeglichkeit_nicht_geprueft" ;
VAL_ 919 FGR_Akt_UeSpg 0 "kein_Fehler" 1 "Fehler" ;
VAL_ 919 FGR_RAkt_UeSpg 0 "Fehlermoeglichkeit_geprueft" 1 "Fehlermoeglichkeit_nicht_geprueft" ;
VAL_ 919 FGR_Akt_USpg 0 "kein_Fehler" 1 "Fehler" ;
VAL_ 919 FGR_RAkt_USpg 0 "Fehlermoeglichkeit_geprueft" 1 "Fehlermoeglichkeit_nicht_geprueft" ;
VAL_ 919 FGR_Akt_UeTemp 0 "kein_Fehler" 1 "Fehler" ;
VAL_ 919 FGR_RAkt_UeTemp 0 "Fehlermoeglichkeit_geprueft" 1 "Fehlermoeglichkeit_nicht_geprueft" ;
VAL_ 919 FGR_Akt_TempPre 0 "kein_Fehler" 1 "Temp_Pre_Alarm" ;
VAL_ 919 FGR_RAkt_TempPre 0 "Fehlermoeglichkeit_geprueft" 1 "Fehlermoeglichkeit_nicht_geprueft" ;
VAL_ 919 FGR_HS_KS_Plus 0 "kein_Fehler" 1 "Fehler" ;
VAL_ 919 FGR_RHS_KS_Plus 0 "Fehlermoeglichkeit_geprueft" 1 "Fehlermoeglichkeit_nicht_geprueft" ;
VAL_ 919 FGR_HS_KS_Gnd 0 "kein_Fehler" 1 "Fehler" ;
VAL_ 919 FGR_RHS_KS_Gnd 0 "Fehlermoeglichkeit_geprueft" 1 "Fehlermoeglichkeit_nicht_geprueft" ;
VAL_ 919 FGR_HS_unplSign 0 "kein_Fehler" 1 "Fehler" ;
VAL_ 919 FGR_RHS_unplSign 0 "Fehlermoeglichkeit_geprueft" 1 "Fehlermoeglichkeit_nicht_geprueft" ;
VAL_ 919 FGR_LIN_Def 0 "kein_Fehler" 1 "Fehler" ;
VAL_ 919 FGR_LIN_Timeout 0 "kein_Fehler" 1 "Fehler" ;
VAL_ 919 FGR_RLIN_Def 0 "Fehlermoeglichkeit_geprueft" 1 "Fehlermoeglichkeit_nicht_geprueft" ;
VAL_ 919 FGR_RLIN_Timeout 0 "Fehlermoeglichkeit_geprueft" 1 "Fehlermoeglichkeit_nicht_geprueft" ;
VAL_ 272 SOG_SollPos_L 4093 "Blockgrenze_oben" 4094 "Init" 4095 "Fehler" ;
VAL_ 272 SOG_MXB_Aufblenden 0 "MXB_nicht_aufblenden" 1 "MXB_aufblenden" ;
VAL_ 272 SOG_MXB_Aufbl_Schaltart 0 "Schalten_hart" 1 "Schalten_mit_Rampe" ;
VAL_ 272 SOG_Mali_Freigabe_re 0 "MXB_nicht_markieren" 1 "MXB_markieren" ;
VAL_ 272 SOG_Mali_Freigabe_li 0 "MXB_nicht_markieren" 1 "MXB_markieren" ;
VAL_ 272 SOG_SollPos_R 4093 "Blockgrenze_oben" 4094 "Init" 4095 "Fehler" ;
VAL_ 272 SOG_FehlPos_L 0 "Fehlerfallpos_nicht_anfahren" 1 "Fehlerfallpos_anfahren" ;
VAL_ 272 SOG_FehlPos_R 0 "Fehlerfallpos_nicht_anfahren" 1 "Fehlerfallpos_anfahren" ;
VAL_ 272 SOG_RefLauf_L 0 "Referenzlauf_nicht_angefordert" 1 "Referenzlauf_angefordert" ;
VAL_ 272 SOG_RefLauf_R 0 "Referenzlauf_nicht_angefordert" 1 "Referenzlauf_angefordert" ;
VAL_ 272 SOG_StGlTest_L 0 "Stellgliedtest_nicht_angefordert" 1 "Stellgliedtest_angefordert" ;
VAL_ 272 SOG_StGlTest_R 0 "Stellgliedtest_nicht_angefordert" 1 "Stellgliedtest_angefordert" ;
VAL_ 272 SOG_Verkehrsrichtung 0 "Rechtsverkehr" 1 "Linksverkehr" ;
VAL_ 272 SOG_XenonLeistung_L 253 "Brenner_Aus" 254 "Init" 255 "Fehler" ;
VAL_ 272 SOG_XenonLeistung_L_Schaltart 0 "ohne_Rampe" 1 "mit_Rampe" ;
VAL_ 272 SOG_XenonLeistung_R 253 "Brenner_Aus" 254 "Init" 255 "Fehler" ;
VAL_ 272 SOG_XenonLeistung_R_Schaltart 0 "ohne_Rampe" 1 "mit_Rampe" ;
VAL_ 407 SGL_IstPos 4093 "Blockgrenze_oben" 4094 "Init" 4095 "Fehler" ;
VAL_ 407 SGL_StaVerst 0 "keine_Verstellung" 1 "Verstellung" ;
VAL_ 407 SGL_StaFehPos 0 "Fehlerpos_nicht_angefahren" 1 "Fehlerpos_angefahren" ;
VAL_ 407 SGL_StaReflauf 0 "RefLauf_noch_nicht_erfolgt" 1 "RefLauf_erfolgt" ;
VAL_ 407 SGL_StaStGlTst 0 "Stellgliedtest_nicht_angefordert" 1 "Stellgliedtest_laeuft" ;
VAL_ 407 SGL_StagLWElMod 0 "Normalbetrieb" 1 "Betrieb_mit_red_Verstellgeschw" ;
VAL_ 407 SGL_StagLWVerkehr 0 "Rechtsverkehr" 1 "Linksverkehr" ;
VAL_ 407 SGL_StagLWFernlicht 0 "Fernlicht_nicht_aktiv" 1 "Fernlicht_aktiv" ;
VAL_ 407 SGL_XenonLeistung 253 "Brenner_Aus" 254 "Init" 255 "Fehler" ;
VAL_ 409 SGR_IstPos 4093 "Blockgrenze_oben" 4094 "Init" 4095 "Fehler" ;
VAL_ 409 SGR_StaVerst 0 "keine_Verstellung" 1 "Verstellung" ;
VAL_ 409 SGR_StaFehPos 0 "Fehlerpos_nicht_angefahren" 1 "Fehlerpos_angefahren" ;
VAL_ 409 SGR_StaReflauf 0 "RefLauf_noch_nicht_erfolgt" 1 "RefLauf_erfolgt" ;
VAL_ 409 SGR_StaStGlTst 0 "Stellgliedtest_nicht_angefordert" 1 "Stellgliedtest_laeuft" ;
VAL_ 409 SGR_StagLWElMod 0 "Normalbetrieb" 1 "Betrieb_mit_red_Verstellgeschw" ;
VAL_ 409 SGR_StagLWVerkehr 0 "Rechtsverkehr" 1 "Linksverkehr" ;
VAL_ 409 SGR_StagLWFernlicht 0 "Fernlicht_nicht_aktiv" 1 "Fernlicht_aktiv" ;
VAL_ 409 SGR_XenonLeistung 253 "Brenner_Aus" 254 "Init" 255 "Fehler" ;
VAL_ 791 Kamera_FDD_Obj01_ID 254 "Init" 255 "nicht_verfuegbar" ;
VAL_ 791 Kamera_FDD_Obj01_Entf_Nah 0 "kein_Objekt" 1 "Objekt_0-10m" 2 "Objekt_11-20m" 3 "Objekt_21-30m" 4 "Objekt_31-40m" 5 "Objekt_41-50m" 6 "Objekt_51-60m" 7 "Objekt_61-70m" 8 "Objekt_71-80m" 9 "Objekt_81-90m" 10 "Objekt_91-100m" 11 "reserviert" 12 "reserviert" 13 "keine_Entfernungsschaetzung" 14 "Init" 15 "nicht_verfuegbar" ;
VAL_ 791 Kamera_FDD_Obj01_Typ 0 "kein_Objekt" 1 "Scheinwerfer" 2 "Rueckleuchte" 3 "Scheinwerferpaar" 4 "Rueckleuchtenpaar_PKW" 5 "Kalibriermuster_links" 6 "Kalibriermuster_rechts" 7 "Cluster" 8 "Strassenleuchte" 9 "Positionsleuchte" 10 "Reflektor" 11 "unklassifizierte_Leuchtquelle" 12 "Reflektion" 13 "Rueckleuchtenpaar_LKW" 14 "Init" 15 "nicht_verfuegbar" ;
VAL_ 791 Kamera_FDD_Obj01_horizPos 1022 "Init" 1023 "nicht_verfuegbar" ;
VAL_ 791 Kamera_FDD_Obj01_MehrAlsAchtObj 0 "8 Objekte oder weniger detektiert" 1 "mehr als 8 Objekte detektiert" 2 "Init" 3 "nicht_verfuegbar" ;
VAL_ 791 Kamera_FDD_Obj01_Ersatzw 0 "Messwert" 1 "Ersatzwert" 2 "Init" 3 "nicht_verfuegbar" ;
VAL_ 791 Kamera_FDD_Obj01_horizDim 1022 "Init" 1023 "nicht_verfuegbar" ;
VAL_ 791 Kamera_FDD_Obj01_vertPos 1022 "Init" 1023 "nicht_verfuegbar" ;
VAL_ 791 Kamera_FDD_Obj01_Entfernung 0 "kein_Objekt" 1 "Objekt_0-50m" 2 "Objekt_51-75m" 3 "Objekt_76-100m" 4 "Objekt_101-125m" 5 "Objekt_126-150m" 6 "Objekt_151-175m" 7 "Objekt_176-200m" 8 "Objekt_201-250m" 9 "Objekt_251-max" 13 "keine_Entfernungsschaetzung" 14 "Init" 15 "nicht_verfuegbar" ;
VAL_ 791 Kamera_FDD_Obj01_Objguete 0 "Guete <= 70%" 1 "70% < Guete <= 85%" 2 "85% < Guete <= 95%" 3 "95% < Guete <= 100%" ;
VAL_ 799 Kamera_FDD_Obj02_ID 254 "Init" 255 "nicht_verfuegbar" ;
VAL_ 799 Kamera_FDD_Obj02_Entf_Nah 0 "kein_Objekt" 1 "Objekt_0-10m" 2 "Objekt_11-20m" 3 "Objekt_21-30m" 4 "Objekt_31-40m" 5 "Objekt_41-50m" 6 "Objekt_51-60m" 7 "Objekt_61-70m" 8 "Objekt_71-80m" 9 "Objekt_81-90m" 10 "Objekt_91-100m" 11 "reserviert" 12 "reserviert" 13 "keine_Entfernungsschaetzung" 14 "Init" 15 "nicht_verfuegbar" ;
VAL_ 799 Kamera_FDD_Obj02_Typ 0 "kein_Objekt" 1 "Scheinwerfer" 2 "Rueckleuchte" 3 "Scheinwerferpaar" 4 "Rueckleuchtenpaar_PKW" 5 "Kalibriermuster_links" 6 "Kalibriermuster_rechts" 7 "Cluster" 8 "Strassenleuchte" 9 "Positionsleuchte" 10 "Reflektor" 11 "unklassifizierte_Leuchtquelle" 12 "Reflektion" 13 "Rueckleuchtenpaar_LKW" 14 "Init" 15 "nicht_verfuegbar" ;
VAL_ 799 Kamera_FDD_Obj02_horizPos 1022 "Init" 1023 "nicht_verfuegbar" ;
VAL_ 799 Kamera_FDD_Obj02_Ersatzw 0 "Messwert" 1 "Ersatzwert" 2 "Init" 3 "nicht_verfuegbar" ;
VAL_ 799 Kamera_FDD_Obj02_horizDim 1022 "Init" 1023 "nicht_verfuegbar" ;
VAL_ 799 Kamera_FDD_Obj02_vertPos 1022 "Init" 1023 "nicht_verfuegbar" ;
VAL_ 799 Kamera_FDD_Obj02_Entfernung 0 "kein_Objekt" 1 "Objekt_0-50m" 2 "Objekt_51-75m" 3 "Objekt_76-100m" 4 "Objekt_101-125m" 5 "Objekt_126-150m" 6 "Objekt_151-175m" 7 "Objekt_176-200m" 8 "Objekt_201-250m" 9 "Objekt_251-max" 13 "keine_Entfernungsschaetzung" 14 "Init" 15 "nicht_verfuegbar" ;
VAL_ 799 Kamera_FDD_Obj02_Objguete 0 "Guete <= 70%" 1 "70% < Guete <= 85%" 2 "85% < Guete <= 95%" 3 "95% < Guete <= 100%" ;
VAL_ 838 Kamera_FDD_Obj03_ID 254 "Init" 255 "nicht_verfuegbar" ;
VAL_ 838 Kamera_FDD_Obj03_Entf_Nah 0 "kein_Objekt" 1 "Objekt_0-10m" 2 "Objekt_11-20m" 3 "Objekt_21-30m" 4 "Objekt_31-40m" 5 "Objekt_41-50m" 6 "Objekt_51-60m" 7 "Objekt_61-70m" 8 "Objekt_71-80m" 9 "Objekt_81-90m" 10 "Objekt_91-100m" 11 "reserviert" 12 "reserviert" 13 "keine_Entfernungsschaetzung" 14 "Init" 15 "nicht_verfuegbar" ;
VAL_ 838 Kamera_FDD_Obj03_Typ 0 "kein_Objekt" 1 "Scheinwerfer" 2 "Rueckleuchte" 3 "Scheinwerferpaar" 4 "Rueckleuchtenpaar_PKW" 5 "Kalibriermuster_links" 6 "Kalibriermuster_rechts" 7 "Cluster" 8 "Strassenleuchte" 9 "Positionsleuchte" 10 "Reflektor" 11 "unklassifizierte_Leuchtquelle" 12 "Reflektion" 13 "Rueckleuchtenpaar_LKW" 14 "Init" 15 "nicht_verfuegbar" ;
VAL_ 838 Kamera_FDD_Obj03_horizPos 1022 "Init" 1023 "nicht_verfuegbar" ;
VAL_ 838 Kamera_FDD_Obj03_Ersatzw 0 "Messwert" 1 "Ersatzwert" 2 "Init" 3 "nicht_verfuegbar" ;
VAL_ 838 Kamera_FDD_Obj03_horizDim 1022 "Init" 1023 "nicht_verfuegbar" ;
VAL_ 838 Kamera_FDD_Obj03_vertPos 1022 "Init" 1023 "nicht_verfuegbar" ;
VAL_ 838 Kamera_FDD_Obj03_Entfernung 0 "kein_Objekt" 1 "Objekt_0-50m" 2 "Objekt_51-75m" 3 "Objekt_76-100m" 4 "Objekt_101-125m" 5 "Objekt_126-150m" 6 "Objekt_151-175m" 7 "Objekt_176-200m" 8 "Objekt_201-250m" 9 "Objekt_251-max" 13 "keine_Entfernungsschaetzung" 14 "Init" 15 "nicht_verfuegbar" ;
VAL_ 838 Kamera_FDD_Obj03_Objguete 0 "Guete <= 70%" 1 "70% < Guete <= 85%" 2 "85% < Guete <= 95%" 3 "95% < Guete <= 100%" ;
VAL_ 839 Kamera_FDD_Obj04_ID 254 "Init" 255 "nicht_verfuegbar" ;
VAL_ 839 Kamera_FDD_Obj04_Entf_Nah 0 "kein_Objekt" 1 "Objekt_0-10m" 2 "Objekt_11-20m" 3 "Objekt_21-30m" 4 "Objekt_31-40m" 5 "Objekt_41-50m" 6 "Objekt_51-60m" 7 "Objekt_61-70m" 8 "Objekt_71-80m" 9 "Objekt_81-90m" 10 "Objekt_91-100m" 11 "reserviert" 12 "reserviert" 13 "keine_Entfernungsschaetzung" 14 "Init" 15 "nicht_verfuegbar" ;
VAL_ 839 Kamera_FDD_Obj04_Typ 0 "kein_Objekt" 1 "Scheinwerfer" 2 "Rueckleuchte" 3 "Scheinwerferpaar" 4 "Rueckleuchtenpaar_PKW" 5 "Kalibriermuster_links" 6 "Kalibriermuster_rechts" 7 "Cluster" 8 "Strassenleuchte" 9 "Positionsleuchte" 10 "Reflektor" 11 "unklassifizierte_Leuchtquelle" 12 "Reflektion" 13 "Rueckleuchtenpaar_LKW" 14 "Init" 15 "nicht_verfuegbar" ;
VAL_ 839 Kamera_FDD_Obj04_horizPos 1022 "Init" 1023 "nicht_verfuegbar" ;
VAL_ 839 Kamera_FDD_Obj04_Ersatzw 0 "Messwert" 1 "Ersatzwert" 2 "Init" 3 "nicht_verfuegbar" ;
VAL_ 839 Kamera_FDD_Obj04_horizDim 1022 "Init" 1023 "nicht_verfuegbar" ;
VAL_ 839 Kamera_FDD_Obj04_vertPos 1022 "Init" 1023 "nicht_verfuegbar" ;
VAL_ 839 Kamera_FDD_Obj04_Entfernung 0 "kein_Objekt" 1 "Objekt_0-50m" 2 "Objekt_51-75m" 3 "Objekt_76-100m" 4 "Objekt_101-125m" 5 "Objekt_126-150m" 6 "Objekt_151-175m" 7 "Objekt_176-200m" 8 "Objekt_201-250m" 9 "Objekt_251-max" 13 "keine_Entfernungsschaetzung" 14 "Init" 15 "nicht_verfuegbar" ;
VAL_ 839 Kamera_FDD_Obj04_Objguete 0 "Guete <= 70%" 1 "70% < Guete <= 85%" 2 "85% < Guete <= 95%" 3 "95% < Guete <= 100%" ;
VAL_ 840 Kamera_FDD_Obj05_ID 254 "Init" 255 "nicht_verfuegbar" ;
VAL_ 840 Kamera_FDD_Obj05_Entf_Nah 0 "kein_Objekt" 1 "Objekt_0-10m" 2 "Objekt_11-20m" 3 "Objekt_21-30m" 4 "Objekt_31-40m" 5 "Objekt_41-50m" 6 "Objekt_51-60m" 7 "Objekt_61-70m" 8 "Objekt_71-80m" 9 "Objekt_81-90m" 10 "Objekt_91-100m" 11 "reserviert" 12 "reserviert" 13 "keine_Entfernungsschaetzung" 14 "Init" 15 "nicht_verfuegbar" ;
VAL_ 840 Kamera_FDD_Obj05_Typ 0 "kein_Objekt" 1 "Scheinwerfer" 2 "Rueckleuchte" 3 "Scheinwerferpaar" 4 "Rueckleuchtenpaar_PKW" 5 "Kalibriermuster_links" 6 "Kalibriermuster_rechts" 7 "Cluster" 8 "Strassenleuchte" 9 "Positionsleuchte" 10 "Reflektor" 11 "unklassifizierte_Leuchtquelle" 12 "Reflektion" 13 "Rueckleuchtenpaar_LKW" 14 "Init" 15 "nicht_verfuegbar" ;
VAL_ 840 Kamera_FDD_Obj05_horizPos 1022 "Init" 1023 "nicht_verfuegbar" ;
VAL_ 840 Kamera_FDD_Obj05_Ersatzw 0 "Messwert" 1 "Ersatzwert" 2 "Init" 3 "nicht_verfuegbar" ;
VAL_ 840 Kamera_FDD_Obj05_horizDim 1022 "Init" 1023 "nicht_verfuegbar" ;
VAL_ 840 Kamera_FDD_Obj05_vertPos 1022 "Init" 1023 "nicht_verfuegbar" ;
VAL_ 840 Kamera_FDD_Obj05_Entfernung 0 "kein_Objekt" 1 "Objekt_0-50m" 2 "Objekt_51-75m" 3 "Objekt_76-100m" 4 "Objekt_101-125m" 5 "Objekt_126-150m" 6 "Objekt_151-175m" 7 "Objekt_176-200m" 8 "Objekt_201-250m" 9 "Objekt_251-max" 13 "keine_Entfernungsschaetzung" 14 "Init" 15 "nicht_verfuegbar" ;
VAL_ 840 Kamera_FDD_Obj05_Objguete 0 "Guete <= 70%" 1 "70% < Guete <= 85%" 2 "85% < Guete <= 95%" 3 "95% < Guete <= 100%" ;
VAL_ 841 Kamera_FDD_Obj06_ID 254 "Init" 255 "nicht_verfuegbar" ;
VAL_ 841 Kamera_FDD_Obj06_Entf_Nah 0 "kein_Objekt" 1 "Objekt_0-10m" 2 "Objekt_11-20m" 3 "Objekt_21-30m" 4 "Objekt_31-40m" 5 "Objekt_41-50m" 6 "Objekt_51-60m" 7 "Objekt_61-70m" 8 "Objekt_71-80m" 9 "Objekt_81-90m" 10 "Objekt_91-100m" 11 "reserviert" 12 "reserviert" 13 "keine_Entfernungsschaetzung" 14 "Init" 15 "nicht_verfuegbar" ;
VAL_ 841 Kamera_FDD_Obj06_Typ 0 "kein_Objekt" 1 "Scheinwerfer" 2 "Rueckleuchte" 3 "Scheinwerferpaar" 4 "Rueckleuchtenpaar_PKW" 5 "Kalibriermuster_links" 6 "Kalibriermuster_rechts" 7 "Cluster" 8 "Strassenleuchte" 9 "Positionsleuchte" 10 "Reflektor" 11 "unklassifizierte_Leuchtquelle" 12 "Reflektion" 13 "Rueckleuchtenpaar_LKW" 14 "Init" 15 "nicht_verfuegbar" ;
VAL_ 841 Kamera_FDD_Obj06_horizPos 1022 "Init" 1023 "nicht_verfuegbar" ;
VAL_ 841 Kamera_FDD_Obj06_Ersatzw 0 "Messwert" 1 "Ersatzwert" 2 "Init" 3 "nicht_verfuegbar" ;
VAL_ 841 Kamera_FDD_Obj06_horizDim 1022 "Init" 1023 "nicht_verfuegbar" ;
VAL_ 841 Kamera_FDD_Obj06_vertPos 1022 "Init" 1023 "nicht_verfuegbar" ;
VAL_ 841 Kamera_FDD_Obj06_Entfernung 0 "kein_Objekt" 1 "Objekt_0-50m" 2 "Objekt_51-75m" 3 "Objekt_76-100m" 4 "Objekt_101-125m" 5 "Objekt_126-150m" 6 "Objekt_151-175m" 7 "Objekt_176-200m" 8 "Objekt_201-250m" 9 "Objekt_251-max" 13 "keine_Entfernungsschaetzung" 14 "Init" 15 "nicht_verfuegbar" ;
VAL_ 841 Kamera_FDD_Obj06_Objguete 0 "Guete <= 70%" 1 "70% < Guete <= 85%" 2 "85% < Guete <= 95%" 3 "95% < Guete <= 100%" ;
VAL_ 842 Kamera_FDD_Obj07_ID 254 "Init" 255 "nicht_verfuegbar" ;
VAL_ 842 Kamera_FDD_Obj07_Entf_Nah 0 "kein_Objekt" 1 "Objekt_0-10m" 2 "Objekt_11-20m" 3 "Objekt_21-30m" 4 "Objekt_31-40m" 5 "Objekt_41-50m" 6 "Objekt_51-60m" 7 "Objekt_61-70m" 8 "Objekt_71-80m" 9 "Objekt_81-90m" 10 "Objekt_91-100m" 11 "reserviert" 12 "reserviert" 13 "keine_Entfernungsschaetzung" 14 "Init" 15 "nicht_verfuegbar" ;
VAL_ 842 Kamera_FDD_Obj07_Typ 0 "kein_Objekt" 1 "Scheinwerfer" 2 "Rueckleuchte" 3 "Scheinwerferpaar" 4 "Rueckleuchtenpaar_PKW" 5 "Kalibriermuster_links" 6 "Kalibriermuster_rechts" 7 "Cluster" 8 "Strassenleuchte" 9 "Positionsleuchte" 10 "Reflektor" 11 "unklassifizierte_Leuchtquelle" 12 "Reflektion" 13 "Rueckleuchtenpaar_LKW" 14 "Init" 15 "nicht_verfuegbar" ;
VAL_ 842 Kamera_FDD_Obj07_horizPos 1022 "Init" 1023 "nicht_verfuegbar" ;
VAL_ 842 Kamera_FDD_Obj07_Ersatzw 0 "Messwert" 1 "Ersatzwert" 2 "Init" 3 "nicht_verfuegbar" ;
VAL_ 842 Kamera_FDD_Obj07_horizDim 1022 "Init" 1023 "nicht_verfuegbar" ;
VAL_ 842 Kamera_FDD_Obj07_vertPos 1022 "Init" 1023 "nicht_verfuegbar" ;
VAL_ 842 Kamera_FDD_Obj07_Entfernung 0 "kein_Objekt" 1 "Objekt_0-50m" 2 "Objekt_51-75m" 3 "Objekt_76-100m" 4 "Objekt_101-125m" 5 "Objekt_126-150m" 6 "Objekt_151-175m" 7 "Objekt_176-200m" 8 "Objekt_201-250m" 9 "Objekt_251-max" 13 "keine_Entfernungsschaetzung" 14 "Init" 15 "nicht_verfuegbar" ;
VAL_ 842 Kamera_FDD_Obj07_Objguete 0 "Guete <= 70%" 1 "70% < Guete <= 85%" 2 "85% < Guete <= 95%" 3 "95% < Guete <= 100%" ;
VAL_ 843 Kamera_FDD_Obj08_ID 254 "Init" 255 "nicht_verfuegbar" ;
VAL_ 843 Kamera_FDD_Obj08_Entf_Nah 0 "kein_Objekt" 1 "Objekt_0-10m" 2 "Objekt_11-20m" 3 "Objekt_21-30m" 4 "Objekt_31-40m" 5 "Objekt_41-50m" 6 "Objekt_51-60m" 7 "Objekt_61-70m" 8 "Objekt_71-80m" 9 "Objekt_81-90m" 10 "Objekt_91-100m" 11 "reserviert" 12 "reserviert" 13 "keine_Entfernungsschaetzung" 14 "Init" 15 "nicht_verfuegbar" ;
VAL_ 843 Kamera_FDD_Obj08_Typ 0 "kein_Objekt" 1 "Scheinwerfer" 2 "Rueckleuchte" 3 "Scheinwerferpaar" 4 "Rueckleuchtenpaar_PKW" 5 "Kalibriermuster_links" 6 "Kalibriermuster_rechts" 7 "Cluster" 8 "Strassenleuchte" 9 "Positionsleuchte" 10 "Reflektor" 11 "unklassifizierte_Leuchtquelle" 12 "Reflektion" 13 "Rueckleuchtenpaar_LKW" 14 "Init" 15 "nicht_verfuegbar" ;
VAL_ 843 Kamera_FDD_Obj08_horizPos 1022 "Init" 1023 "nicht_verfuegbar" ;
VAL_ 843 Kamera_FDD_Obj08_Ersatzw 0 "Messwert" 1 "Ersatzwert" 2 "Init" 3 "nicht_verfuegbar" ;
VAL_ 843 Kamera_FDD_Obj08_horizDim 1022 "Init" 1023 "nicht_verfuegbar" ;
VAL_ 843 Kamera_FDD_Obj08_vertPos 1022 "Init" 1023 "nicht_verfuegbar" ;
VAL_ 843 Kamera_FDD_Obj08_Entfernung 0 "kein_Objekt" 1 "Objekt_0-50m" 2 "Objekt_51-75m" 3 "Objekt_76-100m" 4 "Objekt_101-125m" 5 "Objekt_126-150m" 6 "Objekt_151-175m" 7 "Objekt_176-200m" 8 "Objekt_201-250m" 9 "Objekt_251-max" 13 "keine_Entfernungsschaetzung" 14 "Init" 15 "nicht_verfuegbar" ;
VAL_ 843 Kamera_FDD_Obj08_Objguete 0 "Guete <= 70%" 1 "70% < Guete <= 85%" 2 "85% < Guete <= 95%" 3 "95% < Guete <= 100%" ;
VAL_ 792 Kamera_Systemzustand 0 "Kamera_operativ" 1 "Kamera_Initialisierung" 2 "Kamera_schaltet_ab" 3 "Kamera_Fehler" ;
VAL_ 792 Kamera_FDD_Eigenblend_Guete 14 "Init" 15 "Fehler" ;
VAL_ 792 Kamera_FDD_Eigenblend 0 "Keine_Eigenblendung_erkannt" 1 "Eigenblendung_erkannt" ;
VAL_ 792 Kamera_FDD_Strassenbeleuchung 0 "keine_Strassenbeleuchtung" 1 "Strassenbeleuchtung" 2 "Strassenleuchte" 3 "nicht_verfuegbar" ;
VAL_ 792 Kamera_FDD_Funktionsstatus 0 "FDD_ein_aktiv" 1 "FDD_ein_passiv" 2 "FDD_ein_Einschraenkung_Sicht" 3 "FDD_ein_Fehler_HW_SW" 4 "FDD_aus" 6 "Init" ;
VAL_ 792 Kamera_FDD_Anz_Strassenleuchten 15 "Init" ;
VAL_ 792 Kamera_FDD_Verkehrsrichtung 0 "rechtsverkehr" 1 "linksverkehr" 2 "Init" 3 "nicht verfuegbar" ;
VAL_ 792 Kamera_FSH_aktiv 0 "Kamera_Frontscheibenheizung_nicht_aktiviert" 1 "Kamera_Frontscheibenheizung_aktiviert" ;
VAL_ 792 Kamera_KD_Fehler 0 "kein_KD_Fehler" 1 "KD_Fehler" ;
VAL_ 960 RSt_Fahrerhinweise 0 "Init" 1 "Fahreruebernahme_Hinweis_ZAT_Automat_ohne_Gong" 2 "Fahreruebernahme_Hinweis_ZAT_Automat_mit_Gong" 3 "Fahreruebernahme_Hinweis_ZAT_Handschalter_ohne_Gong" 4 "Fahreruebernahme_Hinweis_ZAT_Handschalter_mit_Gong" 5 "Fahreruebernahme_Hinweis_ZAS_Automat_ohne_Gong" 6 "Fahreruebernahme_Hinweis_ZAS_Automat_mit_Gong" 7 "Fahreruebernahme_Hinweis_ZAS_Handschalter_ohne_Gong" 8 "Fahreruebernahme_Hinweis_ZAS_Handschalter_mit_Gong" 9 "RemoteStart_aktiv_ohne_Gong" 10 "RemoteStart_aktiv_mit_Gong" 11 "void" 12 "void" 13 "void" 14 "void" 15 "void" ;
VAL_ 960 ZAS_Kl_15 0 "aus" 1 "ein" ;
VAL_ 960 BCM_Ausparken_Betrieb 0 "kein_Betrieb" 1 "Ausparkvorgang_aktiv" ;
VAL_ 2549088386 LCM_L_KompSchutz 0 "inaktiv" 1 "aktiv" ;
VAL_ 2549088386 LCM_L_Abschaltstufe 0 "keine_Einschraenkung" 1 "Funktionseinschraenkung" ;
VAL_ 2549088386 LCM_L_Transport_Mode 0 "keine_Einschraenkung" 1 "Funktionseinschraenkung" ;
VAL_ 2549088386 LCM_L_Nachlauftyp 0 "Komm_bei_KL15_EIN" 1 "Komm_nach_KL15_AUS" 2 "Komm_bei_KL15_AUS" ;
VAL_ 2549088386 LCM_L_SNI 130 "LCM_L" ;
VAL_ 2549088386 NM_LCM_L_Wakeup 0 "Peripherie_Wakeup__Ursache_nicht_bekannt" 1 "Bus_Wakeup" 2 "KL15_HW" 3 "KL54_BLS" 4 "Erkennung_Anhaenger" 5 "AVS_Taster" 6 "AVS_Zustandswechsel" ;
VAL_ 2549088386 NM_LCM_L_Lokalaktiv 0 "war_nicht_lokal_aktiv" 1 "war_lokal_aktiv" ;
VAL_ 2549088386 NM_LCM_L_Subsystemaktiv 0 "Subsystem_war_nicht_lokalaktiv" 1 "war_lokalaktiv" ;
VAL_ 2549088386 LCM_L_KD_Fehler 0 "kein_KD_Fehler" 1 "KD_Fehler" ;
VAL_ 2549088387 LCM_R_KompSchutz 0 "inaktiv" 1 "aktiv" ;
VAL_ 2549088387 LCM_R_Abschaltstufe 0 "keine_Einschraenkung" 1 "Funktionseinschraenkung" ;
VAL_ 2549088387 LCM_R_Transport_Mode 0 "keine_Einschraenkung" 1 "Funktionseinschraenkung" ;
VAL_ 2549088387 LCM_R_Nachlauftyp 0 "Komm_bei_KL15_EIN" 1 "Komm_nach_KL15_AUS" 2 "Komm_bei_KL15_AUS" ;
VAL_ 2549088387 LCM_R_SNI 131 "LCM_R" ;
VAL_ 2549088387 NM_LCM_R_Wakeup 0 "Peripherie_Wakeup__Ursache_nicht_bekannt" 1 "Bus_Wakeup" 2 "KL15_HW" 3 "KL54_BLS" 4 "Erkennung_Anhaenger" 5 "AVS_Taster" 6 "AVS_Zustandswechsel" ;
VAL_ 2549088387 NM_LCM_R_Lokalaktiv 0 "war_nicht_lokal_aktiv" 1 "war_lokal_aktiv" ;
VAL_ 2549088387 NM_LCM_R_Subsystemaktiv 0 "Subsystem_war_nicht_lokalaktiv" 1 "war_lokalaktiv" ;
VAL_ 2549088387 LCM_R_KD_Fehler 0 "kein_KD_Fehler" 1 "KD_Fehler" ;
VAL_ 2549088406 LED_DK3_L_KompSchutz 0 "inaktiv" 1 "aktiv" ;
VAL_ 2549088406 LED_DK3_L_Abschaltstufe 0 "keine_Einschraenkung" 1 "Funktionseinschraenkung" ;
VAL_ 2549088406 LED_DK3_L_Transport_Mode 0 "keine_Einschraenkung" 1 "Funktionseinschraenkung" ;
VAL_ 2549088406 LED_DK3_L_Nachlauftyp 0 "Komm_bei_KL15_EIN" 1 "Komm_nach_KL15_AUS" 2 "Komm_bei_KL15_AUS" ;
VAL_ 2549088406 LED_DK3_L_SNI 150 "LED_L" ;
VAL_ 2549088406 NM_LED_DK3_L_Wakeup 0 "Peripherie_Wakeup__Ursache_nicht_bekannt" 1 "Bus_Wakeup" 2 "KL15_HW" 3 "KL54_BLS" 4 "Erkennung_Anhaenger" 5 "AVS_Taster" 6 "AVS_Zustandswechsel" ;
VAL_ 2549088406 NM_LED_DK3_L_Lokalaktiv 0 "war_nicht_lokal_aktiv" 1 "war_lokal_aktiv" ;
VAL_ 2549088406 LED_DK3_L_KD_Fehler 0 "kein_KD_Fehler" 1 "KD_Fehler" ;
VAL_ 2549088407 LED_DK3_R_KompSchutz 0 "inaktiv" 1 "aktiv" ;
VAL_ 2549088407 LED_DK3_R_Abschaltstufe 0 "keine_Einschraenkung" 1 "Funktionseinschraenkung" ;
VAL_ 2549088407 LED_DK3_R_Transport_Mode 0 "keine_Einschraenkung" 1 "Funktionseinschraenkung" ;
VAL_ 2549088407 LED_DK3_R_Nachlauftyp 0 "Komm_bei_KL15_EIN" 1 "Komm_nach_KL15_AUS" 2 "Komm_bei_KL15_AUS" ;
VAL_ 2549088407 LED_DK3_R_SNI 151 "LED_R" ;
VAL_ 2549088407 NM_LED_DK3_R_Wakeup 0 "Peripherie_Wakeup__Ursache_nicht_bekannt" 1 "Bus_Wakeup" 2 "KL15_HW" 3 "KL54_BLS" 4 "Erkennung_Anhaenger" 5 "AVS_Taster" 6 "AVS_Zustandswechsel" ;
VAL_ 2549088407 NM_LED_DK3_R_Lokalaktiv 0 "war_nicht_lokal_aktiv" 1 "war_lokal_aktiv" ;
VAL_ 2549088407 LED_DK3_R_KD_Fehler 0 "kein_KD_Fehler" 1 "KD_Fehler" ;
VAL_ 1387 LCM_TFL_Fehler_L 0 "kein_Fehler" 1 "Fehler" ;
VAL_ 1387 LCM_Sonstiger_Fehler_L 0 "kein_Fehler" 1 "Fehler" ;
VAL_ 1387 LCM_SM_Fehler_L 0 "kein_Fehler" 1 "Fehler" ;
VAL_ 1387 LCM_Shutter_Fehler_L 0 "kein_Fehler" 1 "Fehler" ;
VAL_ 1387 LCM_PO_Fehler_L 0 "kein_Fehler" 1 "Fehler" ;
VAL_ 1387 LCM_Blinker_Fehler_L 0 "kein_Fehler" 1 "Fehler" ;
VAL_ 1387 LCM_LWR_L_allg_Fehler 0 "kein_Fehler" 1 "Fehler" ;
VAL_ 1387 LCM_LWR_L_defekt_Fehler 0 "kein_Fehler" 1 "Fehler" ;
VAL_ 1387 LCM_Datensatz_Fehler_L 0 "kein_Fehler" 1 "Fehler" ;
VAL_ 1387 LCM_DKL_L_defekt_Fehler 0 "kein_Fehler" 1 "Fehler" ;
VAL_ 1387 LCM_GLW_L_defekt_Fehler 0 "kein_Fehler" 1 "Fehler" ;
VAL_ 1387 LCM_SKL_L_defekt_Fehler 0 "kein_Fehler" 1 "Fehler" ;
VAL_ 1388 LCM_TFL_Fehler_R 0 "kein_Fehler" 1 "Fehler" ;
VAL_ 1388 LCM_Sonstiger_Fehler_R 0 "kein_Fehler" 1 "Fehler" ;
VAL_ 1388 LCM_SM_Fehler_R 0 "kein_Fehler" 1 "Fehler" ;
VAL_ 1388 LCM_Shutter_Fehler_R 0 "kein_Fehler" 1 "Fehler" ;
VAL_ 1388 LCM_PO_Fehler_R 0 "kein_Fehler" 1 "Fehler" ;
VAL_ 1388 LCM_Blinker_Fehler_R 0 "kein_Fehler" 1 "Fehler" ;
VAL_ 1388 LCM_LWR_R_allg_Fehler 0 "kein_Fehler" 1 "Fehler" ;
VAL_ 1388 LCM_LWR_R_defekt_Fehler 0 "kein_Fehler" 1 "Fehler" ;
VAL_ 1388 LCM_Datensatz_Fehler_R 0 "kein_Fehler" 1 "Fehler" ;
VAL_ 1388 LCM_DKL_R_defekt_Fehler 0 "kein_Fehler" 1 "Fehler" ;
VAL_ 1388 LCM_GLW_R_defekt_Fehler 0 "kein_Fehler" 1 "Fehler" ;
VAL_ 1388 LCM_SKL_R_defekt_Fehler 0 "kein_Fehler" 1 "Fehler" ;
VAL_ 403 LCM_TFL_L_Anf 0 "TFL_aus" 1 "TFL_an" ;
VAL_ 403 LCM_TFL_R_Anf 0 "TFL_aus" 1 "TFL_an" ;
VAL_ 403 LCM_Abschaltung_Vbat_L_Anf 0 "default" 1 "Anfrage_LCM_Abschaltung" ;
VAL_ 403 LCM_Abschaltung_Vbat_R_Anf 0 "default" 1 "Anfrage_LCM_Abschaltung" ;
VAL_ 403 LCM_Blinker_L_Anf 0 "Blinker_aus" 1 "Blinker_an" ;
VAL_ 403 LCM_Blinker_R_Anf 0 "Blinker_aus" 1 "Blinker_an" ;
VAL_ 403 LCM_Blinkerzyklus_L 0 "Blinkzyklus_inaktiv" 1 "Blinkzyklus_aktiv" ;
VAL_ 403 LCM_Blinkerzyklus_R 0 "Blinkzyklus_inaktiv" 1 "Blinkzyklus_aktiv" ;
VAL_ 403 LCM_Sh_L_Anf 0 "Shutter_aus" 1 "Shutter_an" ;
VAL_ 403 LCM_Sh_R_Anf 0 "Shutter_aus" 1 "Shutter_an" ;
VAL_ 403 LCM_SM_L_Anf 0 "Sidemarker_aus" 1 "Sidemarker_an" ;
VAL_ 403 LCM_SM_R_Anf 0 "Sidemarker_aus" 1 "Sidemarker_an" ;
VAL_ 403 LCM_univ_1_L_Anf 0 "Ausgang_aus" 1 "Ausgang_an" ;
VAL_ 403 LCM_univ_1_R_Anf 0 "Ausgang_aus" 1 "Ausgang_an" ;
VAL_ 403 LCM_PO_L_Anf 0 "PO_aus" 1 "PO_an" ;
VAL_ 403 LCM_PO_R_Anf 0 "PO_aus" 1 "PO_an" ;
VAL_ 403 LCM_PL_L_Anf 0 "PL_aus" 1 "PL_an" ;
VAL_ 403 LCM_PL_R_Anf 0 "PL_aus" 1 "PL_an" ;
VAL_ 403 LCM_Leistungsreduzierung_Anf 0 "Init" 1 "Leistungsreduz_Stufe_1" 2 "Leistungsreduz_Stufe_2" 3 "Leistungsreduz_Stufe_3" ;
VAL_ 403 LCM_Blinkerwischen_Anf 0 "Blinker_Wischen_aus" 1 "Blinker_Wischen_ein" ;
VAL_ 403 LCM_Animiertes_TFL_Anf 0 "Animation_deaktiv" 1 "Animation_aktiv" ;
VAL_ 403 LCM_Signaturlicht_Anf 0 "Signaturlicht_aus" 1 "Signaturlicht_ein" ;
VAL_ 403 LCM_ECE_SAE_Umschaltung_Anf 0 "Anforderung_ECE" 1 "Anforderung_SAE" ;
VAL_ 403 BM_Autobahn 0 "inaktiv" 1 "aktiv" ;
VAL_ 403 BM_ZV_auf 0 "inaktiv" 1 "aktiv" ;
VAL_ 403 BM_ZV_zu 0 "inaktiv" 1 "aktiv" ;
VAL_ 403 BCM1_CH_aktiv 0 "Inaktiv" 1 "Aktiv" ;
VAL_ 403 BCM1_LH_aktiv 0 "Inaktiv" 1 "Aktiv" ;
VAL_ 411 LCM_Ausgangsleistungsred_L_Sta 0 "Inaktiv" 1 "Aktiv" ;
VAL_ 411 LCM_Abschaltbestaetigung_L 0 "Init_Default" 1 "Abschaltung_nicht_moeglich" 2 "Abschaltung_moeglich" 3 "Fehler" ;
VAL_ 411 LCM_Blinker_L_Sta 0 "Blinker_aus" 1 "Blinker_an" ;
VAL_ 411 LCM_PL_L_Sta 0 "PL_links_aus" 1 "PL_links_an" ;
VAL_ 411 LCM_PO_L_Sta 0 "PO_links_aus" 1 "PO_links_an" ;
VAL_ 411 LCM_Sh_L_Sta 0 "Shutter_links_aus" 1 "Shutter_links_an" ;
VAL_ 411 LCM_SM_L_Sta 0 "Sidemarker_aus" 1 "Sidemarker_an" ;
VAL_ 411 LCM_TFL_L_Sta 0 "TFL_links_aus" 1 "TFL_links_an" ;
VAL_ 411 LCM_univ_1_L_Sta 0 "Ausgang_links_aus" 1 "Ausgang_links_an" ;
VAL_ 413 LCM_Ausgangsleistungsred_R_Sta 0 "Inaktiv" 1 "Aktiv" ;
VAL_ 413 LCM_Abschaltbestaetigung_R 0 "Init_Default" 1 "Abschaltung_nicht_moeglich" 2 "Abschaltung_moeglich" 3 "Fehler" ;
VAL_ 413 LCM_Blinker_R_Sta 0 "Blinker_aus" 1 "Blinker_an" ;
VAL_ 413 LCM_PL_R_Sta 0 "PL_rechts_aus" 1 "PL_rechts_an" ;
VAL_ 413 LCM_PO_R_Sta 0 "PO_rechts_aus" 1 "PO_rechts_an" ;
VAL_ 413 LCM_Sh_R_Sta 0 "Shutter_rechts_aus" 1 "Shutter_rechts_an" ;
VAL_ 413 LCM_SM_R_Sta 0 "Sidemarker_aus" 1 "Sidemarker_an" ;
VAL_ 413 LCM_TFL_R_Sta 0 "TFL_rechts_aus" 1 "TFL_rechts_an" ;
VAL_ 413 LCM_univ_1_R_Sta 0 "Ausgang_rechts_aus" 1 "Ausgang_rechts_an" ;
